VERSION ""

NS_ :

BS_:

BU_: RLPSU DPSU APSU PSB SHVU_RR vHS_B2 FCS EMCU SLB RCM CGW_CCU vDummy_HS_B ATS RLHV PFSU SGU ALBCU DSAU SWRC SHVU_FR RCS RRPSU BLTN_CAM SCM DLBCU OHCL RWPC RRHV WPC HOD ASAU

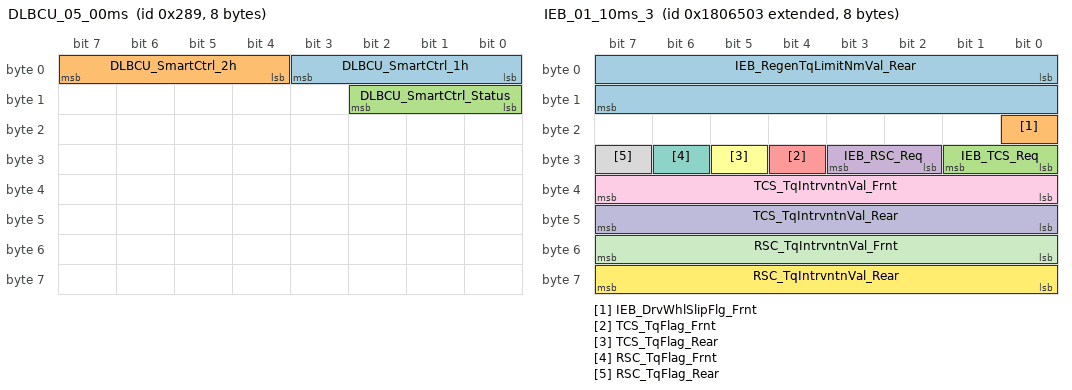
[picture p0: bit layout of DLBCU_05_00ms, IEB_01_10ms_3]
BO_ 649 DLBCU_05_00ms: 8 DLBCU
 SG_ DLBCU_SmartCtrl_1h : 0|4@1+ (1,0) [0|0] ""  CGW_CCU
 SG_ DLBCU_SmartCtrl_2h : 4|4@1+ (1,0) [0|0] ""  CGW_CCU
 SG_ DLBCU_SmartCtrl_Status : 8|3@1+ (1,0) [0|0] ""  CGW_CCU

BO_ 2172675331 IEB_01_10ms_3: 8 CGW_CCU
 SG_ IEB_RegenTqLimitNmVal_Rear : 0|16@1+ (1,0) [0|0] "Nm"  Vector__XXX
 SG_ IEB_DrvWhlSlipFlg_Frnt : 16|1@1+ (1,0) [0|0] ""  Vector__XXX
 SG_ IEB_TCS_Req : 24|2@1+ (1,0) [0|0] ""  Vector__XXX
 SG_ IEB_RSC_Req : 26|2@1+ (1,0) [0|0] ""  Vector__XXX
 SG_ TCS_TqFlag_Frnt : 28|1@1+ (1,0) [0|0] ""  Vector__XXX
 SG_ TCS_TqFlag_Rear : 29|1@1+ (1,0) [0|0] ""  Vector__XXX
 SG_ RSC_TqFlag_Frnt : 30|1@1+ (1,0) [0|0] ""  Vector__XXX
 SG_ RSC_TqFlag_Rear : 31|1@1+ (1,0) [0|0] ""  Vector__XXX
 SG_ TCS_TqIntrvntnVal_Frnt : 32|8@1+ (0.390625,0) [0|0] "%"  Vector__XXX
 SG_ TCS_TqIntrvntnVal_Rear : 40|8@1+ (0.390625,0) [0|0] "%"  Vector__XXX
 SG_ RSC_TqIntrvntnVal_Frnt : 48|8@1+ (0.390625,0) [0|0] "%"  Vector__XXX
 SG_ RSC_TqIntrvntnVal_Rear : 56|8@1+ (0.390625,0) [0|0] "%"  Vector__XXX

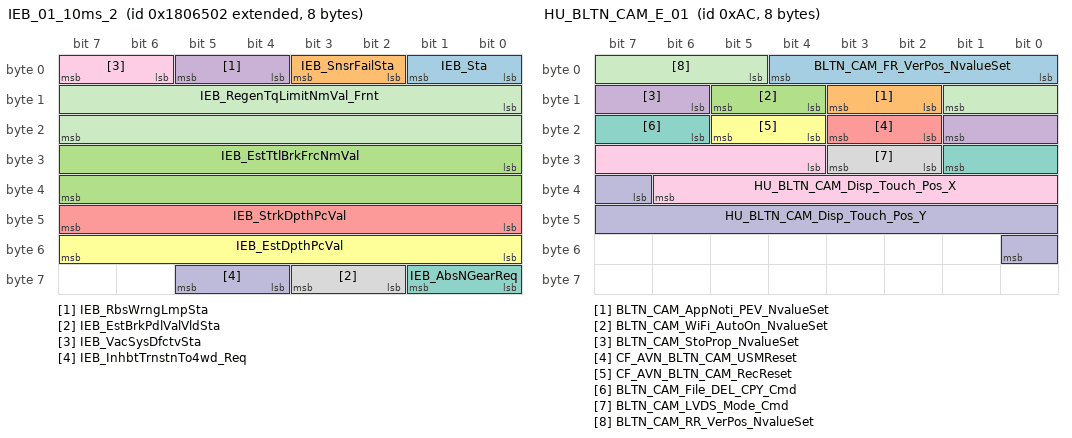
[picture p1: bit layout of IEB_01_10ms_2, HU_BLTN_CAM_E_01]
BO_ 2172675330 IEB_01_10ms_2: 8 CGW_CCU
 SG_ IEB_Sta : 0|2@1+ (1,0) [0|0] ""  Vector__XXX
 SG_ IEB_SnsrFailSta : 2|2@1+ (1,0) [0|0] ""  Vector__XXX
 SG_ IEB_EstTtlBrkFrcNmVal : 24|16@1+ (1,0) [0|0] "Nm"  Vector__XXX
 SG_ IEB_RbsWrngLmpSta : 4|2@1+ (1,0) [0|0] ""  Vector__XXX
 SG_ IEB_StrkDpthPcVal : 40|8@1+ (0.39215,0) [0|0] "%"  Vector__XXX
 SG_ IEB_EstDpthPcVal : 48|8@1+ (0.390625,0) [0|0] "%"  Vector__XXX
 SG_ IEB_AbsNGearReq : 56|2@1+ (1,0) [0|0] ""  Vector__XXX
 SG_ IEB_EstBrkPdlValVldSta : 58|2@1+ (1,0) [0|0] ""  Vector__XXX
 SG_ IEB_VacSysDfctvSta : 6|2@1+ (1,0) [0|0] ""  Vector__XXX
 SG_ IEB_InhbtTrnstnTo4wd_Req : 60|2@1+ (1,0) [0|0] ""  Vector__XXX
 SG_ IEB_RegenTqLimitNmVal_Frnt : 8|16@1+ (1,0) [0|0] "Nm"  Vector__XXX

BO_ 172 HU_BLTN_CAM_E_01: 8 CGW_CCU
 SG_ BLTN_CAM_FR_VerPos_NvalueSet : 0|5@1+ (1,0) [0|0] ""  BLTN_CAM
 SG_ BLTN_CAM_AppNoti_PEV_NvalueSet : 10|2@1+ (1,0) [0|0] ""  BLTN_CAM
 SG_ BLTN_CAM_WiFi_AutoOn_NvalueSet : 12|2@1+ (1,0) [0|0] ""  BLTN_CAM
 SG_ BLTN_CAM_StoProp_NvalueSet : 14|4@1+ (1,0) [0|0] ""  BLTN_CAM
 SG_ CF_AVN_BLTN_CAM_USMReset : 18|2@1+ (1,0) [0|0] ""  BLTN_CAM
 SG_ CF_AVN_BLTN_CAM_RecReset : 20|2@1+ (1,0) [0|0] ""  BLTN_CAM
 SG_ BLTN_CAM_File_DEL_CPY_Cmd : 22|4@1+ (1,0) [0|0] ""  BLTN_CAM
 SG_ BLTN_CAM_LVDS_Mode_Cmd : 26|2@1+ (1,0) [0|0] ""  BLTN_CAM
 SG_ HU_BLTN_CAM_Disp_Touch_Pos_X : 28|11@1+ (1,0) [0|0] ""  BLTN_CAM
 SG_ HU_BLTN_CAM_Disp_Touch_Pos_Y : 39|10@1+ (1,0) [0|0] ""  BLTN_CAM
 SG_ BLTN_CAM_RR_VerPos_NvalueSet : 5|5@1+ (1,0) [0|0] ""  BLTN_CAM

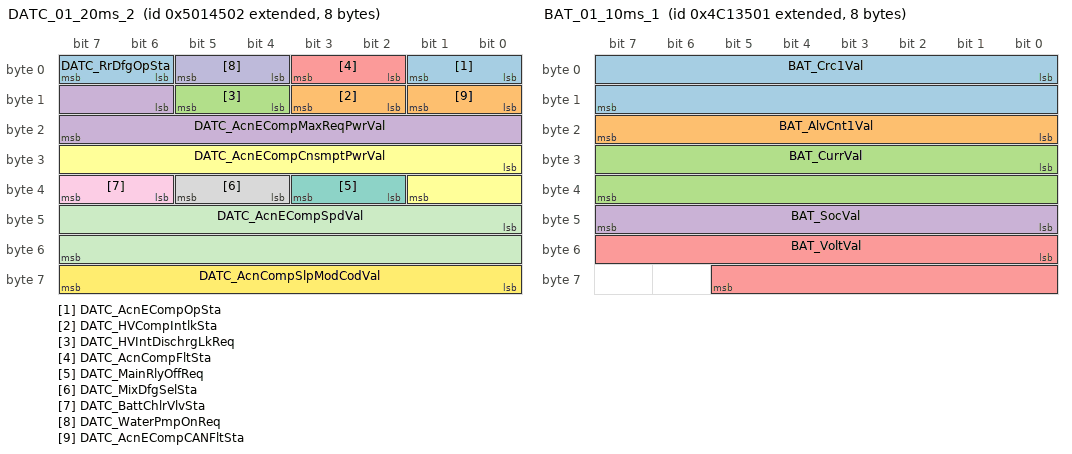
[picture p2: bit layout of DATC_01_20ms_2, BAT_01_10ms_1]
BO_ 2231452930 DATC_01_20ms_2: 8 CGW_CCU
 SG_ DATC_AcnECompOpSta : 0|2@1+ (1,0) [0|0] "flag"  Vector__XXX
 SG_ DATC_HVCompIntlkSta : 10|2@1+ (1,0) [0|0] "flag"  Vector__XXX
 SG_ DATC_HVIntDischrgLkReq : 12|2@1+ (1,0) [0|0] "flag"  Vector__XXX
 SG_ DATC_AcnECompMaxReqPwrVal : 14|10@1+ (20,0) [0|0] "W"  Vector__XXX
 SG_ DATC_AcnCompFltSta : 2|2@1+ (1,0) [0|0] "flag"  Vector__XXX
 SG_ DATC_AcnECompCnsmptPwrVal : 24|10@1+ (20,0) [0|0] "W"  Vector__XXX
 SG_ DATC_MainRlyOffReq : 34|2@1+ (1,0) [0|0] "flag"  Vector__XXX
 SG_ DATC_MixDfgSelSta : 36|2@1+ (1,0) [0|0] "flag"  Vector__XXX
 SG_ DATC_BattChlrVlvSta : 38|2@1+ (1,0) [0|0] ""  Vector__XXX
 SG_ DATC_WaterPmpOnReq : 4|2@1+ (1,0) [0|0] "flag"  Vector__XXX
 SG_ DATC_AcnECompSpdVal : 40|16@1+ (1,0) [0|0] "rpm"  Vector__XXX
 SG_ DATC_AcnCompSlpModCodVal : 56|8@1+ (1,0) [0|0] ""  Vector__XXX
 SG_ DATC_RrDfgOpSta : 6|2@1+ (1,0) [0|0] "flag"  Vector__XXX
 SG_ DATC_AcnECompCANFltSta : 8|2@1+ (1,0) [0|0] "flag"  Vector__XXX

BO_ 2227254529 BAT_01_10ms_1: 8 CGW_CCU
 SG_ BAT_Crc1Val : 0|16@1+ (1,0) [0|0] ""  Vector__XXX
 SG_ BAT_AlvCnt1Val : 16|8@1+ (1,0) [0|0] ""  Vector__XXX
 SG_ BAT_CurrVal : 24|16@1+ (0.01,-327) [0|0] "A"  Vector__XXX
 SG_ BAT_SocVal : 40|8@1+ (1,0) [0|0] "%"  BLTN_CAM
 SG_ BAT_VoltVal : 48|14@1+ (0.001,6) [0|0] "V"  Vector__XXX

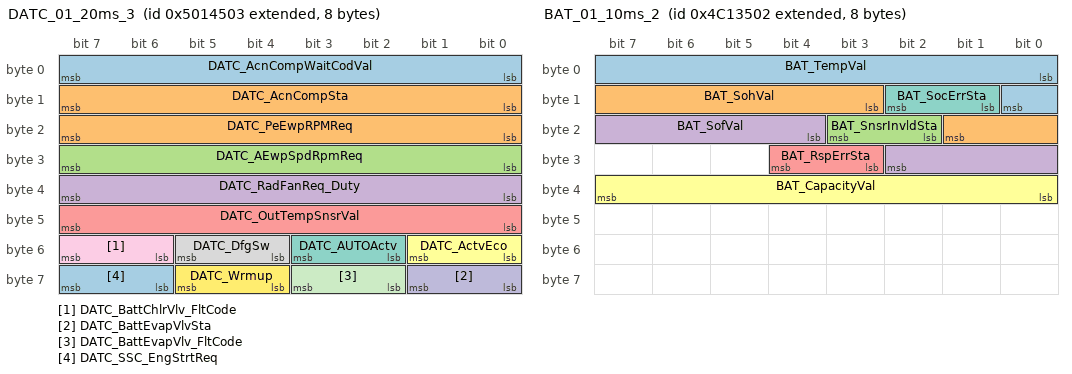
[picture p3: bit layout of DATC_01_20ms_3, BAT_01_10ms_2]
BO_ 2231452931 DATC_01_20ms_3: 8 CGW_CCU
 SG_ DATC_AcnCompWaitCodVal : 0|8@1+ (1,0) [0|0] ""  Vector__XXX
 SG_ DATC_PeEwpRPMReq : 16|8@1+ (30,0) [0|0] ""  Vector__XXX
 SG_ DATC_AEwpSpdRpmReq : 24|8@1+ (20,0) [0|0] "rpm"  Vector__XXX
 SG_ DATC_RadFanReq_Duty : 32|8@1+ (1,0) [0|0] "%"  Vector__XXX
 SG_ DATC_OutTempSnsrVal : 40|8@1+ (0.5,-40) [0|0] "¡É"  RCM
 SG_ DATC_ActvEco : 48|2@1+ (1,0) [0|0] ""  Vector__XXX
 SG_ DATC_AUTOActv : 50|2@1+ (1,0) [0|0] ""  Vector__XXX
 SG_ DATC_DfgSw : 52|2@1+ (1,0) [0|0] ""  Vector__XXX
 SG_ DATC_BattChlrVlv_FltCode : 54|2@1+ (1,0) [0|0] ""  Vector__XXX
 SG_ DATC_BattEvapVlvSta : 56|2@1+ (1,0) [0|0] ""  Vector__XXX
 SG_ DATC_BattEvapVlv_FltCode : 58|2@1+ (1,0) [0|0] ""  Vector__XXX
 SG_ DATC_Wrmup : 60|2@1+ (1,0) [0|0] ""  Vector__XXX
 SG_ DATC_SSC_EngStrtReq : 62|2@1+ (1,0) [0|0] ""  Vector__XXX
 SG_ DATC_AcnCompSta : 8|8@1+ (1,0) [0|0] ""  Vector__XXX

BO_ 2227254530 BAT_01_10ms_2: 8 CGW_CCU
 SG_ BAT_TempVal : 0|9@1+ (0.5,-40) [0|0] "¡É"  Vector__XXX
 SG_ BAT_SohVal : 11|7@1+ (1,0) [0|0] "%"  Vector__XXX
 SG_ BAT_SnsrInvldSta : 18|2@1+ (1,0) [0|0] ""  Vector__XXX
 SG_ BAT_SofVal : 20|7@1+ (0.1,0) [0|0] "V"  Vector__XXX
 SG_ BAT_RspErrSta : 27|2@1+ (1,0) [0|0] ""  Vector__XXX
 SG_ BAT_CapacityVal : 32|8@1+ (1,0) [0|0] ""  Vector__XXX
 SG_ BAT_SocErrSta : 9|2@1+ (1,0) [0|0] ""  Vector__XXX

BO_ 2231452929 DATC_01_20ms_1: 8 CGW_CCU
 SG_ DATC_Crc1Val : 0|16@1+ (1,0) [0|0] ""  Vector__XXX
 SG_ DATC_AlvCnt1Val : 16|8@1+ (1,0) [0|0] ""  Vector__XXX
 SG_ DATC_PtcRlySta : 24|3@1+ (1,0) [0|0] ""  Vector__XXX
 SG_ DATC_ManufacturerTyp : 27|3@1+ (1,0) [0|0] ""  Vector__XXX
 SG_ DATC_DatcPwmSts : 30|2@1+ (1,0) [0|0] ""  Vector__XXX
 SG_ DATC_AcnCompTyp : 32|3@1+ (1,0) [0|0] "flag"  Vector__XXX
 SG_ DATC_EewpRpmLvlReq : 35|3@1+ (1,0) [0|0] ""  Vector__XXX
 SG_ DATC_Cooldown : 38|2@1+ (1,0) [0|0] ""  Vector__XXX
 SG_ DATC_AcnReq : 40|2@1+ (1,0) [0|0] ""  Vector__XXX
 SG_ DATC_BlwSta : 42|2@1+ (1,0) [0|0] ""  Vector__XXX
 SG_ DATC_BlwMaxSta : 44|2@1+ (1,0) [0|0] ""  Vector__XXX
 SG_ DATC_EngStrtReq : 46|2@1+ (1,0) [0|0] ""  Vector__XXX
 SG_ DATC_IsgInhbtReq : 48|2@1+ (1,0) [0|0] ""  Vector__XXX
 SG_ DATC_AcnCompOnReq : 50|2@1+ (1,0) [0|0] "flag"  Vector__XXX
 SG_ DATC_SrvLmpReq : 52|2@1+ (1,0) [0|0] ""  Vector__XXX
 SG_ DATC_EcvFltSta : 54|2@1+ (1,0) [0|0] ""  Vector__XXX
 SG_ DATC_CalcAcnCompTqVal : 56|8@1+ (0.2,0) [0|0] "Nm"  Vector__XXX

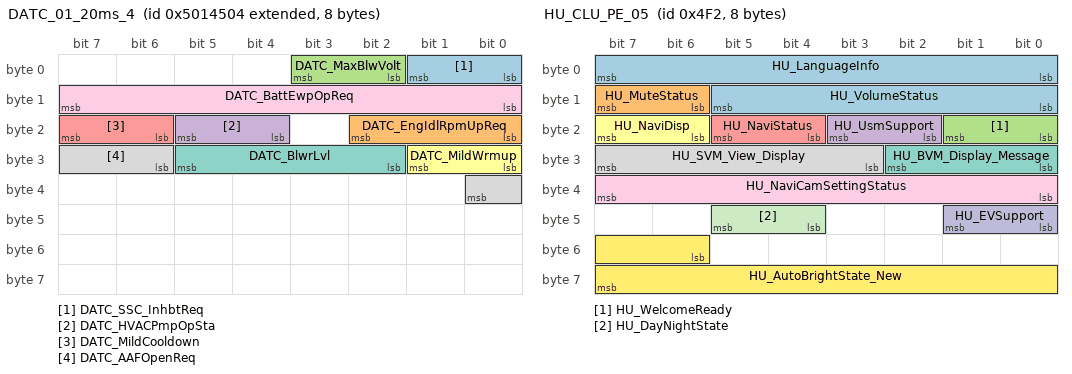
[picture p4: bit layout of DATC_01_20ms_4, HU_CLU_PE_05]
BO_ 2231452932 DATC_01_20ms_4: 8 CGW_CCU
 SG_ DATC_SSC_InhbtReq : 0|2@1+ (1,0) [0|0] ""  Vector__XXX
 SG_ DATC_EngIdlRpmUpReq : 16|3@1+ (1,0) [0|0] ""  Vector__XXX
 SG_ DATC_MaxBlwVolt : 2|2@1+ (1,0) [0|0] ""  Vector__XXX
 SG_ DATC_HVACPmpOpSta : 20|2@1+ (1,0) [0|0] ""  Vector__XXX
 SG_ DATC_MildCooldown : 22|2@1+ (1,0) [0|0] ""  Vector__XXX
 SG_ DATC_MildWrmup : 24|2@1+ (1,0) [0|0] ""  Vector__XXX
 SG_ DATC_BlwrLvl : 26|4@1+ (1,0) [0|0] ""  Vector__XXX
 SG_ DATC_AAFOpenReq : 30|3@1+ (1,0) [0|0] ""  Vector__XXX
 SG_ DATC_BattEwpOpReq : 8|8@1+ (30,0) [0|0] "rpm"  Vector__XXX

BO_ 1266 HU_CLU_PE_05: 8 CGW_CCU
 SG_ HU_LanguageInfo : 0|8@1+ (1,0) [0|0] ""  ATS,BLTN_CAM
 SG_ HU_MuteStatus : 14|2@1+ (1,0) [0|0] ""  Vector__XXX
 SG_ HU_WelcomeReady : 16|2@1+ (1,0) [0|0] ""  Vector__XXX
 SG_ HU_UsmSupport : 18|2@1+ (1,0) [0|0] ""  Vector__XXX
 SG_ HU_NaviStatus : 20|2@1+ (1,0) [0|0] ""  Vector__XXX
 SG_ HU_NaviDisp : 22|2@1+ (1,0) [0|0] ""  Vector__XXX
 SG_ HU_BVM_Display_Message : 24|3@1+ (1,0) [0|0] ""  Vector__XXX
 SG_ HU_SVM_View_Display : 27|5@1+ (1,0) [0|0] ""  Vector__XXX
 SG_ HU_NaviCamSettingStatus : 32|8@1+ (1,0) [0|0] ""  Vector__XXX
 SG_ HU_EVSupport : 40|2@1+ (1,0) [0|0] ""  Vector__XXX
 SG_ HU_DayNightState : 44|2@1+ (1,0) [0|0] ""  Vector__XXX
 SG_ HU_AutoBrightState_New : 54|10@1+ (1,0) [0|0] ""  Vector__XXX
 SG_ HU_VolumeStatus : 8|6@1+ (1,0) [0|0] ""  Vector__XXX

BO_ 191 RL_SHVU_03_200ms: 8 SHVU_RR
 SG_ RL_SHVU_DTCdisplay : 0|8@1+ (1,0) [0|0] ""  ATS
 SG_ RL_SHVU_DiagMode : 8|2@1+ (1,0) [0|0] ""  ATS

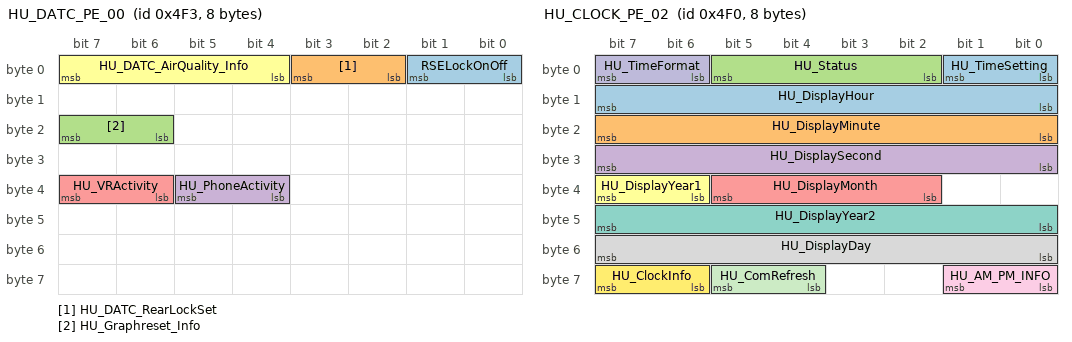
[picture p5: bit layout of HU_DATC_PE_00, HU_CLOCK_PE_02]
BO_ 1267 HU_DATC_PE_00: 8 CGW_CCU
 SG_ RSELockOnOff : 0|2@1+ (1,0) [0|0] ""  APSU,ATS
 SG_ HU_DATC_RearLockSet : 2|2@1+ (1,0) [0|0] ""  Vector__XXX
 SG_ HU_Graphreset_Info : 22|2@1+ (1,0) [0|0] ""  Vector__XXX
 SG_ HU_PhoneActivity : 36|2@1+ (1,0) [0|0] ""  Vector__XXX
 SG_ HU_VRActivity : 38|2@1+ (1,0) [0|0] ""  Vector__XXX
 SG_ HU_DATC_AirQuality_Info : 4|4@1+ (1,0) [0|0] ""  Vector__XXX

BO_ 1264 HU_CLOCK_PE_02: 8 CGW_CCU
 SG_ HU_TimeSetting : 0|2@1+ (1,0) [0|0] ""  ATS,BLTN_CAM
 SG_ HU_DisplayMinute : 16|8@1+ (1,0) [0|0] ""  ATS,BLTN_CAM
 SG_ HU_Status : 2|4@1+ (1,0) [0|0] ""  ATS,BLTN_CAM
 SG_ HU_DisplaySecond : 24|8@1+ (1,0) [0|0] ""  ATS,BLTN_CAM
 SG_ HU_DisplayMonth : 34|4@1+ (1,0) [0|0] ""  ATS,BLTN_CAM
 SG_ HU_DisplayYear1 : 38|2@1+ (1,0) [0|0] ""  ATS,BLTN_CAM
 SG_ HU_DisplayYear2 : 40|8@1+ (1,0) [0|0] ""  ATS,BLTN_CAM
 SG_ HU_DisplayDay : 48|8@1+ (1,0) [0|0] ""  ATS,BLTN_CAM
 SG_ HU_AM_PM_INFO : 56|2@1+ (1,0) [0|0] ""  ATS,BLTN_CAM
 SG_ HU_TimeFormat : 6|2@1+ (1,0) [0|0] ""  ATS,BLTN_CAM
 SG_ HU_ComRefresh : 60|2@1+ (1,0) [0|0] ""  ATS,BLTN_CAM
 SG_ HU_ClockInfo : 62|2@1+ (1,0) [0|0] ""  ATS,BLTN_CAM
 SG_ HU_DisplayHour : 8|8@1+ (1,0) [0|0] ""  ATS,BLTN_CAM

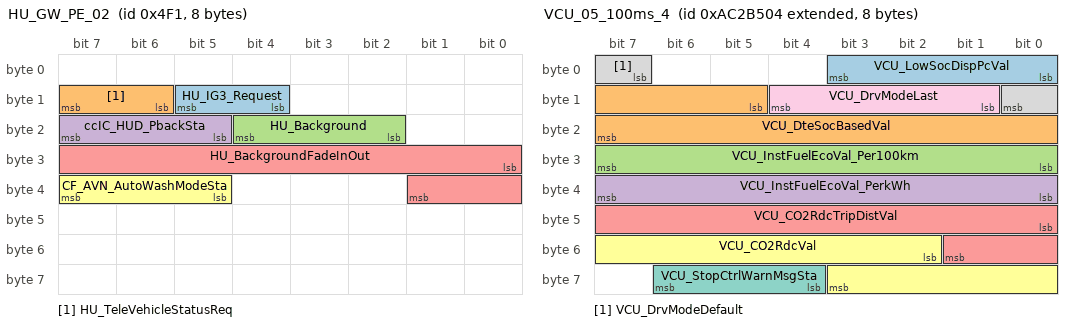
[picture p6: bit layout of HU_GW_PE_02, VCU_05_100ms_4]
BO_ 1265 HU_GW_PE_02: 8 CGW_CCU
 SG_ HU_IG3_Request : 12|2@1+ (1,0) [0|0] ""  Vector__XXX
 SG_ HU_TeleVehicleStatusReq : 14|2@1+ (1,0) [0|3] ""  Vector__XXX
 SG_ HU_Background : 18|3@1+ (1,0) [0|0] ""  ATS,BLTN_CAM
 SG_ ccIC_HUD_PbackSta : 21|3@1+ (1,0) [0|0] ""  DPSU
 SG_ HU_BackgroundFadeInOut : 24|10@1+ (0.1,0) [0|0] "%"  ATS,BLTN_CAM
 SG_ CF_AVN_AutoWashModeSta : 37|3@1+ (1,0) [0|0] ""  RCM

BO_ 2328016132 VCU_05_100ms_4: 8 CGW_CCU
 SG_ VCU_LowSocDispPcVal : 0|4@1+ (1,0) [0|0] ""  Vector__XXX
 SG_ VCU_DteSocBasedVal : 13|11@1+ (1,0) [0|0] "km"  Vector__XXX
 SG_ VCU_InstFuelEcoVal_Per100km : 24|8@1+ (0.5,0) [0|126.5] "kWh/100km"  Vector__XXX
 SG_ VCU_InstFuelEcoVal_PerkWh : 32|8@1+ (0.1,0) [0|25.5] "km/kWh"  Vector__XXX
 SG_ VCU_CO2RdcTripDistVal : 40|10@1+ (1,0) [0|1023] "km"  Vector__XXX
 SG_ VCU_CO2RdcVal : 50|10@1+ (100,0) [0|102300] "g"  Vector__XXX
 SG_ VCU_StopCtrlWarnMsgSta : 60|3@1+ (1,0) [0|0] ""  Vector__XXX
 SG_ VCU_DrvModeDefault : 7|2@1+ (1,0) [0|0] ""  Vector__XXX
 SG_ VCU_DrvModeLast : 9|4@1+ (1,0) [0|0] ""  Vector__XXX

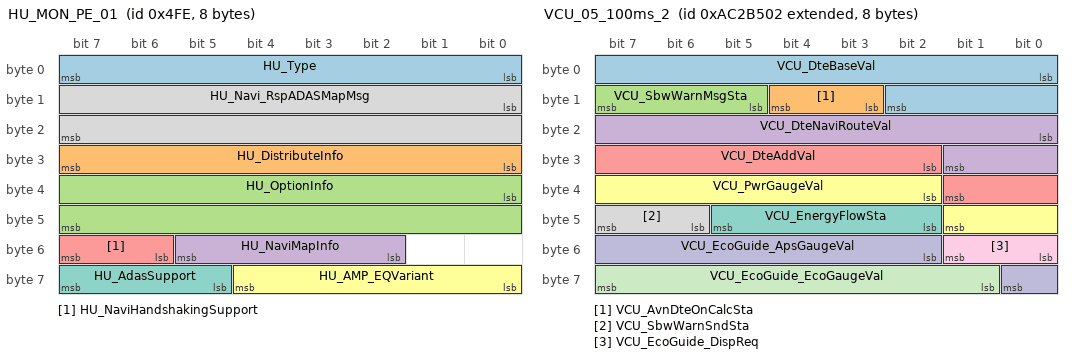
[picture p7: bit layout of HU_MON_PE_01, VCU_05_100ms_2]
BO_ 1278 HU_MON_PE_01: 8 CGW_CCU
 SG_ HU_Type : 0|8@1+ (1,0) [0|0] ""  BLTN_CAM
 SG_ HU_DistributeInfo : 24|8@1+ (1,0) [0|0] ""  BLTN_CAM
 SG_ HU_OptionInfo : 32|16@1+ (1,0) [0|0] ""  BLTN_CAM
 SG_ HU_NaviMapInfo : 50|4@1+ (1,0) [0|0] ""  Vector__XXX
 SG_ HU_NaviHandshakingSupport : 54|2@1+ (1,0) [0|0] ""  Vector__XXX
 SG_ HU_AMP_EQVariant : 56|5@1+ (1,0) [0|0] ""  Vector__XXX
 SG_ HU_AdasSupport : 61|3@1+ (1,0) [0|0] ""  Vector__XXX
 SG_ HU_Navi_RspADASMapMsg : 8|16@1+ (1,0) [0|0] ""  Vector__XXX

BO_ 1279 HU_USM_E_10: 8 CGW_CCU
 SG_ USM_SmartRegen_Map_Set : 11|2@1+ (1,0) [0|0] ""  Vector__XXX
 SG_ USM_SmartRegen_Sens_Set : 13|3@1+ (1,0) [0|0] ""  Vector__XXX
 SG_ AVN_SeatPosMemory_Btn : 16|3@1+ (1,0) [0|0] ""  Vector__XXX
 SG_ AVN_SeatPosPlyBck_Btn : 19|3@1+ (1,0) [0|0] ""  DPSU
 SG_ USM_RhstaLvlEnaSetReq : 22|2@1+ (1,0) [0|0] ""  Vector__XXX
 SG_ USM_CMSDayBrgtnsLvlLHSetReq : 24|4@1+ (1,0) [0|0] ""  Vector__XXX
 SG_ USM_CMSNgtBrgtnsLvlLHSetReq : 28|4@1+ (1,0) [0|0] ""  Vector__XXX
 SG_ USM_CMSDayBrgtnsLvlRHSetReq : 32|4@1+ (1,0) [0|0] ""  Vector__XXX
 SG_ USM_CMSNgtBrgtnsLvlRHSetReq : 36|4@1+ (1,0) [0|0] ""  Vector__XXX
 SG_ USM_CMSBrgtnsReset : 40|2@1+ (1,0) [0|0] ""  Vector__XXX
 SG_ USM_TurnDistLnDispSetReq : 42|2@1+ (1,0) [0|0] ""  Vector__XXX
 SG_ PCA_FrSd_NValueSet : 44|2@1+ (1,0) [0|0] ""  Vector__XXX
 SG_ CF_AVN_1stRrStRmndNValueSet : 46|2@1+ (1,0) [0|0] ""  Vector__XXX
 SG_ AVN_Usm_CluThemeSta_New : 48|4@1+ (1,0) [0|0] ""  Vector__XXX
 SG_ C_AllDrOpnNValueSet : 52|3@1+ (1,0) [0|0] ""  Vector__XXX
 SG_ USM_RpmECOSet : 55|2@1+ (1,0) [0|0] ""  Vector__XXX
 SG_ VESS_ChgGuideMdLvl : 57|3@1+ (1,0) [0|0] ""  Vector__XXX
 SG_ Usm_RpmSPORTSet : 60|2@1+ (1,0) [0|0] ""  Vector__XXX
 SG_ Usm_RpmSPORTPLUSSet : 62|2@1+ (1,0) [0|0] ""  Vector__XXX

BO_ 2328016129 VCU_05_100ms_1: 8 CGW_CCU
 SG_ VCU_Crc5Val : 0|16@1+ (1,0) [0|0] ""  Vector__XXX
 SG_ VCU_AlvCnt5Val : 16|8@1+ (1,0) [0|0] ""  Vector__XXX
 SG_ VCU_EvDrvRdyCluDispSta : 24|2@1+ (1,0) [0|3] ""  SWRC
 SG_ VCU_PwrDnModeSta : 26|2@1+ (1,0) [0|3] ""  Vector__XXX
 SG_ VCU_CluWarnMsgSta : 28|4@1+ (1,0) [0|15] ""  Vector__XXX
 SG_ VCU_DteOffDispSta : 32|2@1+ (1,0) [0|0] "flag"  Vector__XXX
 SG_ VCU_LowSocAlertSta : 34|3@1+ (1,0) [0|7] ""  Vector__XXX
 SG_ VCU_VcrmReq : 38|2@1+ (1,0) [0|3] ""  Vector__XXX
 SG_ VCU_PdlWarnMsgSta : 40|2@1+ (1,0) [0|3] ""  Vector__XXX
 SG_ VCU_AwdDiagDispSta : 42|2@1+ (1,0) [0|0] ""  Vector__XXX
 SG_ VCU_AwdLockDispSta : 44|2@1+ (1,0) [0|0] ""  Vector__XXX
 SG_ VCU_VirtualApsActSta : 46|2@1+ (1,0) [0|3] ""  Vector__XXX
 SG_ VCU_VirtualApsVal : 48|8@1+ (0.3906,0) [0|99.61] "%"  Vector__XXX
 SG_ VCU_ServiceLampReq : 56|2@1+ (1,0) [0|3] ""  Vector__XXX
 SG_ VCU_ServiceModeSta : 58|2@1+ (1,0) [0|3] ""  Vector__XXX
 SG_ VCU_NPosWshModSta : 60|2@1+ (1,0) [0|0] "flag"  Vector__XXX
 SG_ VCU_PowerTrainType : 62|2@1+ (1,0) [0|3] ""  Vector__XXX

BO_ 2328016130 VCU_05_100ms_2: 8 CGW_CCU
 SG_ VCU_DteBaseVal : 0|11@1+ (1,0) [0|2047] "km"  Vector__XXX
 SG_ VCU_AvnDteOnCalcSta : 11|2@1+ (1,0) [0|3] ""  Vector__XXX
 SG_ VCU_SbwWarnMsgSta : 13|3@1+ (1,0) [0|0] "flag"  Vector__XXX
 SG_ VCU_DteNaviRouteVal : 16|10@1+ (2,0) [0|1026] "km"  Vector__XXX
 SG_ VCU_DteAddVal : 26|8@1+ (1,0) [0|255] "km"  Vector__XXX
 SG_ VCU_PwrGaugeVal : 34|8@1- (1,0) [-100|100] "%"  Vector__XXX
 SG_ VCU_EnergyFlowSta : 42|4@1+ (1,0) [0|15] ""  Vector__XXX
 SG_ VCU_SbwWarnSndSta : 46|2@1+ (1,0) [0|0] "flag"  Vector__XXX
 SG_ VCU_EcoGuide_DispReq : 48|2@1+ (1,0) [0|3] ""  Vector__XXX
 SG_ VCU_EcoGuide_ApsGaugeVal : 50|7@1+ (1,0) [0|100] "%"  Vector__XXX
 SG_ VCU_EcoGuide_EcoGaugeVal : 57|7@1+ (1,0) [0|100] "%"  Vector__XXX

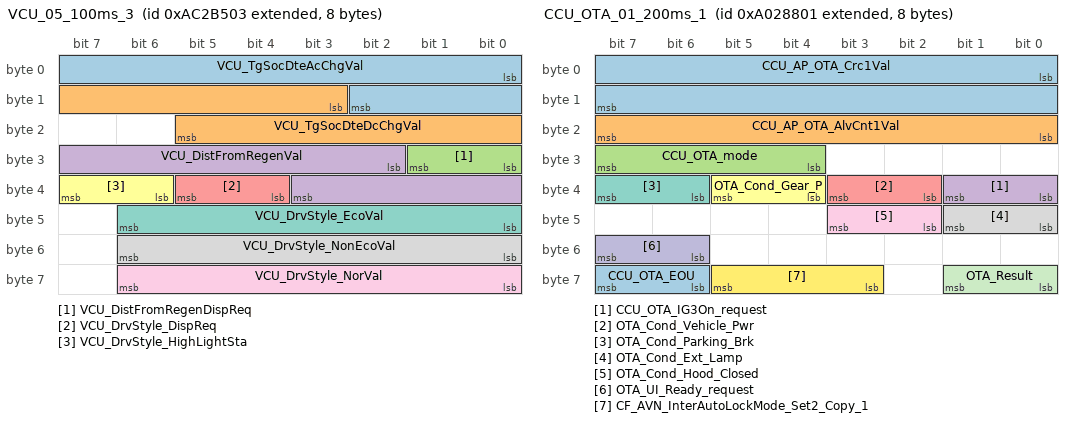
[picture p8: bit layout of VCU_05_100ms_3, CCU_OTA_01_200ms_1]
BO_ 2328016131 VCU_05_100ms_3: 8 CGW_CCU
 SG_ VCU_TgSocDteAcChgVal : 0|11@1+ (1,0) [0|2047] "km"  Vector__XXX
 SG_ VCU_TgSocDteDcChgVal : 11|11@1+ (1,0) [0|2047] "km"  Vector__XXX
 SG_ VCU_DistFromRegenDispReq : 24|2@1+ (1,0) [0|3] ""  Vector__XXX
 SG_ VCU_DistFromRegenVal : 26|10@1+ (10,0) [0|10230] "m"  Vector__XXX
 SG_ VCU_DrvStyle_DispReq : 36|2@1+ (1,0) [0|3] ""  Vector__XXX
 SG_ VCU_DrvStyle_HighLightSta : 38|2@1+ (1,0) [0|3] ""  Vector__XXX
 SG_ VCU_DrvStyle_EcoVal : 40|7@1+ (1,0) [0|100] "%"  Vector__XXX
 SG_ VCU_DrvStyle_NonEcoVal : 48|7@1+ (1,0) [0|100] "%"  Vector__XXX
 SG_ VCU_DrvStyle_NorVal : 56|7@1+ (1,0) [0|100] "%"  Vector__XXX

BO_ 2315421697 CCU_OTA_01_200ms_1: 8 CGW_CCU
 SG_ CCU_AP_OTA_Crc1Val : 0|16@1+ (1,0) [0|0] ""  vDummy_HS_B
 SG_ CCU_AP_OTA_AlvCnt1Val : 16|8@1+ (1,0) [0|0] ""  vDummy_HS_B
 SG_ CCU_OTA_mode : 28|4@1+ (1,0) [0|0] ""  Vector__XXX
 SG_ CCU_OTA_IG3On_request : 32|2@1+ (1,0) [0|0] ""  Vector__XXX
 SG_ OTA_Cond_Vehicle_Pwr : 34|2@1+ (1,0) [0|0] "flag"  Vector__XXX
 SG_ OTA_Cond_Gear_P : 36|2@1+ (1,0) [0|0] "flag"  Vector__XXX
 SG_ OTA_Cond_Parking_Brk : 38|2@1+ (1,0) [0|0] "flag"  Vector__XXX
 SG_ OTA_Cond_Ext_Lamp : 40|2@1+ (1,0) [0|0] "flag"  Vector__XXX
 SG_ OTA_Cond_Hood_Closed : 42|2@1+ (1,0) [0|0] "flag"  Vector__XXX
 SG_ OTA_UI_Ready_request : 54|2@1+ (1,0) [0|0] ""  Vector__XXX
 SG_ OTA_Result : 56|2@1+ (1,0) [0|0] "flag"  Vector__XXX
 SG_ CF_AVN_InterAutoLockMode_Set2_Copy_1 : 59|3@1+ (1,0) [0|0] ""  Vector__XXX
 SG_ CCU_OTA_EOU : 62|2@1+ (1,0) [0|0] ""  Vector__XXX

BO_ 2470763009 CLU_09_00ms_1: 8 CGW_CCU
 SG_ CLU_Crc9Val : 0|16@1+ (1,0) [0|0] ""  Vector__XXX
 SG_ CLU_AlvCnt9Val : 16|8@1+ (1,0) [0|0] ""  Vector__XXX
 SG_ USM_MdLmpClrSetReq : 24|4@1+ (1,0) [0|0] ""  Vector__XXX
 SG_ USM_RrWiperRevSetReq : 28|2@1+ (1,0) [0|0] ""  Vector__XXX
 SG_ USM_RrStRemindSetReq : 30|2@1+ (1,0) [0|0] ""  Vector__XXX
 SG_ USM_RrWpcSetReq : 32|2@1+ (1,0) [0|0] ""  Vector__XXX
 SG_ USM_WpcSetReq : 34|2@1+ (1,0) [0|0] ""  WPC
 SG_ USM_SeqLmpSetReq : 36|2@1+ (1,0) [0|0] ""  Vector__XXX
 SG_ USM_UnlckWlcmSetReq : 38|2@1+ (1,0) [0|0] ""  Vector__XXX
 SG_ USM_SmrtWlcmSetReq : 40|2@1+ (1,0) [0|0] ""  Vector__XXX
 SG_ USM_UipSetReq : 42|2@1+ (1,0) [0|0] ""  Vector__XXX
 SG_ USM_DigitalKeyEnblSetReq : 44|2@1+ (1,0) [0|0] ""  Vector__XXX
 SG_ USM_OwnerPhnRegSetReq : 46|2@1+ (1,0) [0|0] ""  Vector__XXX
 SG_ USM_NFCCard1RegSetReq : 48|2@1+ (1,0) [0|0] ""  Vector__XXX
 SG_ USM_NFCCard2RegSetReq : 50|2@1+ (1,0) [0|0] ""  Vector__XXX
 SG_ USM_ProcStpReq : 52|1@1+ (1,0) [0|0] ""  Vector__XXX
 SG_ USM_PwrAutoOffTimeSetReq : 54|3@1+ (1,0) [0|0] ""  Vector__XXX
 SG_ USM_RrStRemindSetReq_RestMode : 57|3@1+ (1,0) [0|0] ""  Vector__XXX
 SG_ USM_1stRrStRemindSetReq : 60|2@1+ (1,0) [0|0] ""  Vector__XXX

BO_ 200 HU_USM_E_12: 8 CGW_CCU
 SG_ CF_AVN_ADrLNValueSet_2 : 0|3@1+ (1,0) [0|0] ""  Vector__XXX
 SG_ CF_AVN_FCA_JC_OnOffEquipNvalueSet : 12|2@1+ (1,0) [0|0] ""  Vector__XXX
 SG_ CF_AVN_FCA_FrSdOnOffEquipNvalueSet : 14|2@1+ (1,0) [0|0] ""  Vector__XXX
 SG_ CF_AVN_LKA_OnOffEquip2NvalueSet : 16|2@1+ (1,0) [0|0] ""  Vector__XXX
 SG_ CF_AVN_BCA_OnOffEquip2NvalueSet : 18|2@1+ (1,0) [0|0] ""  Vector__XXX
 SG_ CF_AVN_BVM_OnOffEquipNvalueSet : 20|2@1+ (1,0) [0|0] ""  Vector__XXX
 SG_ CF_AVN_SEA_OnOffEquip3NvalueSet : 22|2@1+ (1,0) [0|0] ""  Vector__XXX
 SG_ CF_AVN_BodySpprtSet_AST : 24|2@1+ (1,0) [0|0] ""  ALBCU
 SG_ CF_AVN_SEW_OnOffEquip3NvalueSet : 26|2@1+ (1,0) [0|0] ""  Vector__XXX
 SG_ CF_AVN_HudImsAutoSave : 28|2@1+ (1,0) [0|0] ""  Vector__XXX
 SG_ USM_PwrDrBuzzerNValueSet : 3|2@1+ (1,0) [0|0] ""  Vector__XXX
 SG_ CF_AVN_DWLNValueSet : 30|3@1+ (1,0) [0|0] ""  Vector__XXX
 SG_ CF_AVN_AirSptTimeNValueSet_AST : 33|3@1+ (1,0) [0|0] ""  ALBCU
 SG_ CF_AVN_AirSptStrNValue_AST : 36|2@1+ (1,0) [0|0] ""  ALBCU
 SG_ CF_AVN_SeatDrvModNvalueSet_AST : 38|2@1+ (1,0) [0|0] ""  ALBCU
 SG_ CF_AVN_TPMS_TireReplaceNValueSet : 40|3@1+ (1,0) [0|0] ""  Vector__XXX
 SG_ CF_AVN_TowModeSet : 43|3@1+ (1,0) [0|0] ""  Vector__XXX
 SG_ USM_PwrDrCloseByBraekNValueSet : 46|2@1+ (1,0) [0|0] ""  Vector__XXX
 SG_ CF_AVN_ISLANAOffstNvalueSet : 50|3@1+ (1,0) [0|0] ""  Vector__XXX
 SG_ USM_DrvGhostDoorReq : 56|2@1+ (1,0) [0|0] ""  Vector__XXX
 SG_ USM_AstGhostDoorReq : 58|2@1+ (1,0) [0|0] ""  Vector__XXX
 SG_ USM_RLGhostDoorReq : 60|2@1+ (1,0) [0|0] ""  Vector__XXX
 SG_ USM_RRGhostDoorReq : 62|2@1+ (1,0) [0|0] ""  Vector__XXX
 SG_ CF_AVN_FCA_FrOnOffEquipNvalueSet : 7|2@1+ (1,0) [0|0] ""  Vector__XXX
 SG_ CF_AVN_FCA_WarnTimeNvalueSet : 9|3@1+ (1,0) [0|0] ""  Vector__XXX

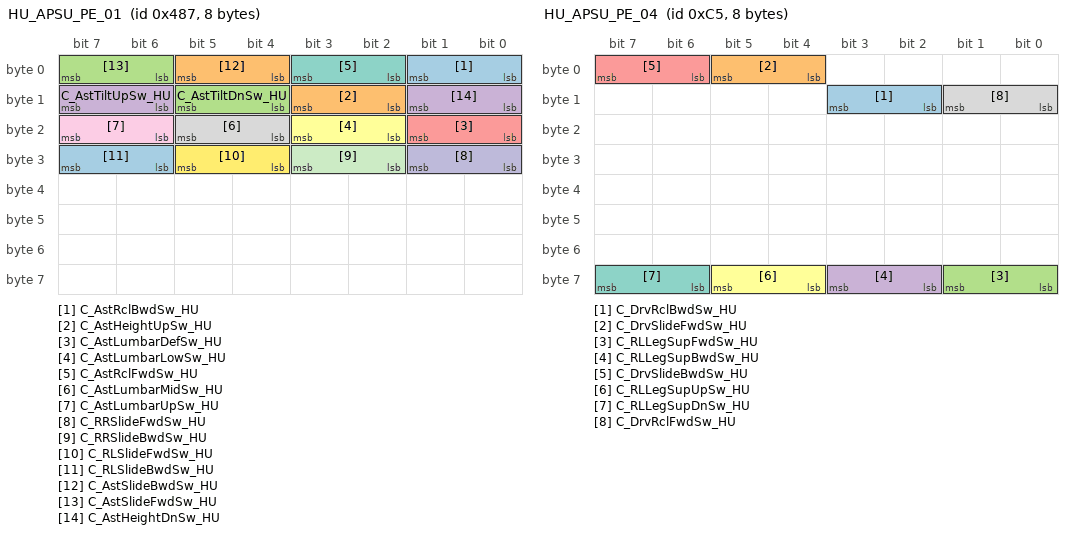
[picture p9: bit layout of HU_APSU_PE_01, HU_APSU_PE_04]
BO_ 1159 HU_APSU_PE_01: 8 CGW_CCU
 SG_ C_AstRclBwdSw_HU : 0|2@1+ (1,0) [0|0] ""  APSU
 SG_ C_AstHeightUpSw_HU : 10|2@1+ (1,0) [0|0] ""  APSU
 SG_ C_AstTiltDnSw_HU : 12|2@1+ (1,0) [0|0] ""  APSU
 SG_ C_AstTiltUpSw_HU : 14|2@1+ (1,0) [0|0] ""  APSU
 SG_ C_AstLumbarDefSw_HU : 16|2@1+ (1,0) [0|0] ""  ASAU,ALBCU
 SG_ C_AstLumbarLowSw_HU : 18|2@1+ (1,0) [0|0] ""  ASAU,ALBCU
 SG_ C_AstRclFwdSw_HU : 2|2@1+ (1,0) [0|0] ""  APSU
 SG_ C_AstLumbarMidSw_HU : 20|2@1+ (1,0) [0|0] ""  ASAU,ALBCU
 SG_ C_AstLumbarUpSw_HU : 22|2@1+ (1,0) [0|0] ""  ASAU,ALBCU
 SG_ C_RRSlideFwdSw_HU : 24|2@1+ (1,0) [0|0] ""  APSU,RRPSU,RLPSU
 SG_ C_RRSlideBwdSw_HU : 26|2@1+ (1,0) [0|0] ""  APSU,RRPSU,RLPSU
 SG_ C_RLSlideFwdSw_HU : 28|2@1+ (1,0) [0|0] ""  APSU,RRPSU,RLPSU
 SG_ C_RLSlideBwdSw_HU : 30|2@1+ (1,0) [0|0] ""  APSU,RRPSU,RLPSU
 SG_ C_AstSlideBwdSw_HU : 4|2@1+ (1,0) [0|0] ""  APSU
 SG_ C_AstSlideFwdSw_HU : 6|2@1+ (1,0) [0|0] ""  APSU
 SG_ C_AstHeightDnSw_HU : 8|2@1+ (1,0) [0|0] ""  APSU

BO_ 197 HU_APSU_PE_04: 8 CGW_CCU
 SG_ C_DrvRclBwdSw_HU : 10|2@1+ (1,0) [0|0] ""  DPSU
 SG_ C_DrvSlideFwdSw_HU : 4|2@1+ (1,0) [0|0] ""  DPSU
 SG_ C_RLLegSupFwdSw_HU : 56|2@1+ (1,0) [0|0] ""  APSU,RRPSU,RLPSU
 SG_ C_RLLegSupBwdSw_HU : 58|2@1+ (1,0) [0|0] ""  APSU,RRPSU,RLPSU
 SG_ C_DrvSlideBwdSw_HU : 6|2@1+ (1,0) [0|0] ""  DPSU
 SG_ C_RLLegSupUpSw_HU : 60|2@1+ (1,0) [0|0] ""  APSU,RRPSU,RLPSU
 SG_ C_RLLegSupDnSw_HU : 62|2@1+ (1,0) [0|0] ""  APSU,RRPSU,RLPSU
 SG_ C_DrvRclFwdSw_HU : 8|2@1+ (1,0) [0|0] ""  DPSU

BO_TX_BU_ 191 : SHVU_RR,SHVU_FR,RLHV;
CM_ BO_ 2227254529 "[P] Periodic";
CM_ SG_ 2227254529 BAT_Crc1Val "BAT_CyclicRedundancyCheck1Value";
CM_ SG_ 2227254529 BAT_AlvCnt1Val "BAT_AliveCounter1Value";
CM_ SG_ 2227254529 BAT_CurrVal "BAT_CurrentValue";
CM_ SG_ 2227254529 BAT_SocVal "BAT_StateOfChargeValue";
CM_ SG_ 2227254529 BAT_VoltVal "BAT_VoltageValue";
CM_ BO_ 2227254530 "[P] Periodic";
CM_ SG_ 2227254530 BAT_TempVal "BAT_TemperatureValue";
CM_ SG_ 2227254530 BAT_SohVal "BAT_StateOfHealthValue";
CM_ SG_ 2227254530 BAT_SnsrInvldSta "BAT_SensorInvalidStatus";
CM_ SG_ 2227254530 BAT_SofVal "BAT_StateOfFunctionValue";
CM_ SG_ 2227254530 BAT_RspErrSta "BAT_ResponseErrorStatus";
CM_ SG_ 2227254530 BAT_CapacityVal "12V Battery Capacity Value";
CM_ SG_ 2227254530 BAT_SocErrSta "BAT_SoCErrorStatus";
CM_ BO_ 2315421697 "[PE] Periodic and On Event";
CM_ SG_ 2315421697 CCU_OTA_mode "OTA_mode";
CM_ SG_ 2315421697 CCU_OTA_IG3On_request "IG3 Rly ON request";
CM_ SG_ 2315421697 OTA_UI_Ready_request "OTA UI Ready";
CM_ SG_ 2315421697 OTA_Result "¾÷µ¥ÀÌÆ® °á°ú";
CM_ SG_ 2315421697 CF_AVN_InterAutoLockMode_Set2_Copy_1 "USM Request for Charing Connector Locking Mode (Auto/Lock/Unlock)";
CM_ BO_ 2470763009 "[EC] On Event and On Change";
CM_ SG_ 2470763009 CLU_Crc9Val "CLU_CyclicRedundancyCheck9Value";
CM_ SG_ 2470763009 CLU_AlvCnt9Val "CLU_AliveCounter9Value";
CM_ SG_ 2470763009 USM_MdLmpClrSetReq "USM_MoodLampColorSetRequest";
CM_ SG_ 2470763009 USM_RrWiperRevSetReq "USM_RearWiperReverseSetRequest";
CM_ SG_ 2470763009 USM_RrStRemindSetReq "USM_RrseatReminderSetRequest(2nd :General: CLU20/CF_Clu_RrSeatRemindNValueSet)";
CM_ SG_ 2470763009 USM_RrWpcSetReq "USM_RearWpcSetRequest";
CM_ SG_ 2470763009 USM_WpcSetReq "USM_WpcSetRequest";
CM_ SG_ 2470763009 USM_SeqLmpSetReq "USM_SequencialLampSetRequest";
CM_ SG_ 2470763009 USM_UnlckWlcmSetReq "USM_UnlockWelcomeSetRequest";
CM_ SG_ 2470763009 USM_SmrtWlcmSetReq "USM_SmartWelcomeSetRequest";
CM_ SG_ 2470763009 USM_UipSetReq "2nd General: CF_Clu_UIPNValueSet";
CM_ SG_ 2470763009 USM_DigitalKeyEnblSetReq "Request to set the Digital Key ON or OFF(2nd General DB: CF_Clu_DigitalKeyNValueSet)";
CM_ SG_ 2470763009 USM_OwnerPhnRegSetReq "2nd general DB: CF_Clu_OwnerPhoneNValueSet";
CM_ SG_ 2470763009 USM_NFCCard1RegSetReq "2nd General DB:CF_Clu_NFCCard1NValueSet";
CM_ SG_ 2470763009 USM_NFCCard2RegSetReq "2nd General DB:CF_Clu_NFCCard2NValueSet";
CM_ SG_ 2470763009 USM_ProcStpReq "2nd General DB:CF_Clu_ProcessStopReq";
CM_ SG_ 2470763009 USM_PwrAutoOffTimeSetReq "USM_PowerAutoofftimeSetRequest";
CM_ SG_ 2470763009 USM_RrStRemindSetReq_RestMode "Request to set  Restmod of Rear Seat remind";
CM_ SG_ 2470763009 USM_1stRrStRemindSetReq "USM_RrseatReminderSetRequest(2nd :General: CLU21/CF_Clu_1stRrSeatRemindNValueSet)";
CM_ BO_ 2231452929 "[P] Periodic";
CM_ SG_ 2231452929 DATC_Crc1Val "DATC_CyclicRedundancyCheck1Value";
CM_ SG_ 2231452929 DATC_AlvCnt1Val "DATC_AliveCounter1Value";
CM_ SG_ 2231452929 DATC_PtcRlySta "DATC_PtcRelayStatus";
CM_ SG_ 2231452929 DATC_ManufacturerTyp "DATC_ManufacturerType";
CM_ SG_ 2231452929 DATC_DatcPwmSts "Status of E-comp";
CM_ SG_ 2231452929 DATC_AcnCompTyp "DATC_AirconCompressorType";
CM_ SG_ 2231452929 DATC_EewpRpmLvlReq "DATC_EewpRpmlevelReq";
CM_ SG_ 2231452929 DATC_Cooldown "Complete of cooldown";
CM_ SG_ 2231452929 DATC_AcnReq "DATC_AirconRequest";
CM_ SG_ 2231452929 DATC_BlwSta "DATC_BlowerStatus";
CM_ SG_ 2231452929 DATC_BlwMaxSta "DATC_BlowerMaxStatus";
CM_ SG_ 2231452929 DATC_EngStrtReq "DATC_EngineStartRequest";
CM_ SG_ 2231452929 DATC_IsgInhbtReq "DATC_IsgInhibitRequset";
CM_ SG_ 2231452929 DATC_AcnCompOnReq "DATC_AirconCompressorOnRequest";
CM_ SG_ 2231452929 DATC_SrvLmpReq "DATC_ServiceLampRequest";
CM_ SG_ 2231452929 DATC_EcvFltSta "DATC_EcvFaultStatus";
CM_ SG_ 2231452929 DATC_CalcAcnCompTqVal "DATC_CalculatedAirconCompressortorqueValue";
CM_ BO_ 2231452930 "[P] Periodic";
CM_ SG_ 2231452930 DATC_AcnECompOpSta "DATC_AirconElectricCompressorOperationStatus";
CM_ SG_ 2231452930 DATC_HVCompIntlkSta "DATC_HighVoltageCompressorInterlockStatus";
CM_ SG_ 2231452930 DATC_HVIntDischrgLkReq "DATC_HighVoltageInterlockDischargeRequest";
CM_ SG_ 2231452930 DATC_AcnECompMaxReqPwrVal "DATC_AirconElectricalCompressorMaximumRequestPowerValue";
CM_ SG_ 2231452930 DATC_AcnCompFltSta "DATC_AirconElectricCompressorFaultStatus";
CM_ SG_ 2231452930 DATC_AcnECompCnsmptPwrVal "DATC_AirconElectricalCompressorConsumptionPowerValue";
CM_ SG_ 2231452930 DATC_MainRlyOffReq "DATC_MainRelayoffRequest";
CM_ SG_ 2231452930 DATC_MixDfgSelSta "DATC_MixDefogSelectStatus";
CM_ SG_ 2231452930 DATC_BattChlrVlvSta "Battery chiller valve status";
CM_ SG_ 2231452930 DATC_WaterPmpOnReq "DATC_WaterPumpOnRequest";
CM_ SG_ 2231452930 DATC_AcnECompSpdVal "DATC_AirconElectricalCompressorSpeedValue";
CM_ SG_ 2231452930 DATC_AcnCompSlpModCodVal "DATC_AirconCompressorSleepModeCodeValue";
CM_ SG_ 2231452930 DATC_RrDfgOpSta "DATC_RearDefogOperatingState";
CM_ SG_ 2231452930 DATC_AcnECompCANFltSta "DATC_AirconElectricalCompressorCANFaultStatus";
CM_ BO_ 2231452931 "[P] Periodic";
CM_ SG_ 2231452931 DATC_AcnCompWaitCodVal "DATC_AirconCompressorWaitCode";
CM_ SG_ 2231452931 DATC_PeEwpRPMReq "DATC_PeEwpRpmRequest";
CM_ SG_ 2231452931 DATC_AEwpSpdRpmReq "DATC_AsistenceEwpSpeedRpmRequest";
CM_ SG_ 2231452931 DATC_RadFanReq_Duty "This signal indicates Request cooling fan speed to cool HVAC System (Duty)";
CM_ SG_ 2231452931 DATC_OutTempSnsrVal "DATC_OutsideTemperatureSensorValue";
CM_ SG_ 2231452931 DATC_ActvEco "DATC_ActiveEco";
CM_ SG_ 2231452931 DATC_AUTOActv "DATCAutoActivation";
CM_ SG_ 2231452931 DATC_DfgSw "DATC_DefogSwitch";
CM_ SG_ 2231452931 DATC_BattChlrVlv_FltCode "Battery Chiller Filt Code";
CM_ SG_ 2231452931 DATC_BattEvapVlvSta "BATTERY COOL V/V (EVAP) STATUS";
CM_ SG_ 2231452931 DATC_BattEvapVlv_FltCode "BATTERY COOL V/V (EVAP) FltCode";
CM_ SG_ 2231452931 DATC_Wrmup "Complete of warmup";
CM_ SG_ 2231452931 DATC_SSC_EngStrtReq "Engine start request in SSC state";
CM_ SG_ 2231452931 DATC_AcnCompSta "DATC_AirconCompressorStatus";
CM_ BO_ 2231452932 "[P] Periodic";
CM_ SG_ 2231452932 DATC_SSC_InhbtReq "Request to EMS not to enter SSC";
CM_ SG_ 2231452932 DATC_EngIdlRpmUpReq "DATC_EngineIdleRpmUpRequest";
CM_ SG_ 2231452932 DATC_MaxBlwVolt "DATC_MaxBlowerVoltage";
CM_ SG_ 2231452932 DATC_HVACPmpOpSta "HVAC Pump Operation Status";
CM_ SG_ 2231452932 DATC_MildWrmup "Mild Warmup State";
CM_ SG_ 2231452932 DATC_BattEwpOpReq "Battery EWP Operating Request";
CM_ BO_ 649 "[EC] On Event and On Change";
CM_ SG_ 649 DLBCU_SmartCtrl_1h "½º¸¶Æ® ÀÚ¼¼Á¦¾î DLBCU ¿¬µ¿ Á¶Àý¿¡ µû¸¥ °³¼±ÇöÈ² AVN Ç¥½Ã¹®±¸_1½Ã°£";
CM_ SG_ 649 DLBCU_SmartCtrl_2h "½º¸¶Æ® ÀÚ¼¼Á¦¾î DLBCU ¿¬µ¿ Á¶Àý¿¡ µû¸¥ °³¼±ÇöÈ² AVN Ç¥½Ã ¹®±¸_2½Ã°£";
CM_ SG_ 649 DLBCU_SmartCtrl_Status "½º¸¶Æ® ÀÚ¼¼Á¦¾î 2´Ü°è DLBCU ¿¬µ¿ Á¶Àý µ¿ÀÛ ½ÃÀÛ / Á¾·á / Áß´Ü AVN ÆË¾÷";
CM_ BO_ 1159 "[PE] Periodic and On Event";
CM_ SG_ 1159 C_AstRclBwdSw_HU "Assistant seat Moving control :Recline Backward";
CM_ SG_ 1159 C_AstHeightUpSw_HU "Assistant seat Moving control : Height Up";
CM_ SG_ 1159 C_AstTiltDnSw_HU "Assistant seat Moving control : Tilt Down";
CM_ SG_ 1159 C_AstTiltUpSw_HU "Assistant seat Moving Switch : Tilt Up";
CM_ SG_ 1159 C_AstLumbarDefSw_HU "Assistant seat moving switch: Deflate";
CM_ SG_ 1159 C_AstLumbarLowSw_HU "Assistant seat moving switch:Lumbar Low";
CM_ SG_ 1159 C_AstRclFwdSw_HU "Assistant seat Moving Switch : Recline Forward";
CM_ SG_ 1159 C_AstLumbarMidSw_HU "Assistant seat Moving control : Lumbar Mid";
CM_ SG_ 1159 C_AstLumbarUpSw_HU "Assistant seat Moving control : Lumbar Up";
CM_ SG_ 1159 C_RRSlideFwdSw_HU "2nd Right side seat Moving control :Power Slide Forward";
CM_ SG_ 1159 C_RRSlideBwdSw_HU "2nd Right side seat Moving control :Power Slide Backward";
CM_ SG_ 1159 C_RLSlideFwdSw_HU "2nd Left side seat Moving control :Power Slide Forward";
CM_ SG_ 1159 C_RLSlideBwdSw_HU "2nd Left side seat Moving control :Power Slide Backward";
CM_ SG_ 1159 C_AstSlideBwdSw_HU "Assistant seat moving switch : Slide Backward";
CM_ SG_ 1159 C_AstSlideFwdSw_HU "Assistant seat Moving switch : Slide Forward";
CM_ SG_ 1159 C_AstHeightDnSw_HU "Assistant seat Moving control : Height Down";
CM_ BO_ 197 "[PE] Periodic and On Event";
CM_ SG_ 197 C_DrvRclBwdSw_HU "Driver Seat Recline Backward Control";
CM_ SG_ 197 C_DrvSlideFwdSw_HU "Driver Seat Slide Forward Control";
CM_ SG_ 197 C_RLLegSupFwdSw_HU "2nd Left side seat Moving control : Leg Support Forward";
CM_ SG_ 197 C_RLLegSupBwdSw_HU "2nd Left side seat Moving control : Leg Support Backward";
CM_ SG_ 197 C_DrvSlideBwdSw_HU "Driver Seat Slide Backward Control";
CM_ SG_ 197 C_RLLegSupUpSw_HU "2nd Left side seat Moving control : Leg Support Up";
CM_ SG_ 197 C_RLLegSupDnSw_HU "2nd Left side seat Moving control : Leg Support Down";
CM_ SG_ 197 C_DrvRclFwdSw_HU "Driver Seat Recline Forward Control";
CM_ BO_ 172 "[EC] On Event and On Change";
CM_ SG_ 172 BLTN_CAM_FR_VerPos_NvalueSet "Front Camera Vertical position setting value.";
CM_ SG_ 172 BLTN_CAM_AppNoti_PEV_NvalueSet "Parked Event notification to Connectivity Phone App. On/Off";
CM_ SG_ 172 BLTN_CAM_WiFi_AutoOn_NvalueSet "Wifi On/Off User setting";
CM_ SG_ 172 BLTN_CAM_StoProp_NvalueSet "Propotion of built-in Cam SD card Propotion set of the Recording Categories";
CM_ SG_ 172 CF_AVN_BLTN_CAM_USMReset "Buit-in Cam USM Reset Request.";
CM_ SG_ 172 CF_AVN_BLTN_CAM_RecReset "Buit-in Cam format(all file delete/Reset) Request.";
CM_ SG_ 172 BLTN_CAM_File_DEL_CPY_Cmd "Buit-in Cam operation control of copying and deleting.";
CM_ SG_ 172 BLTN_CAM_LVDS_Mode_Cmd "This Signal is for LVDS output commend to BLTN_CAM";
CM_ SG_ 172 HU_BLTN_CAM_Disp_Touch_Pos_X "X position of touch of display when BLTN-in CAM Engineer mode in";
CM_ SG_ 172 HU_BLTN_CAM_Disp_Touch_Pos_Y "Y position of touch of display when BLTN-in CAM Engineer mode in";
CM_ SG_ 172 BLTN_CAM_RR_VerPos_NvalueSet "Rear Camera Vertical position setting value.";
CM_ BO_ 1264 "[PE] Periodic and On Event";
CM_ SG_ 1264 HU_TimeSetting "Information for current time setting";
CM_ SG_ 1264 HU_DisplayMinute "Information for time display in Minute unit";
CM_ SG_ 1264 HU_Status "Information for H/U status
Transmitted on H/U status changing";
CM_ SG_ 1264 HU_DisplaySecond "Information for time display in Second unit";
CM_ SG_ 1264 HU_DisplayMonth "Information for Month";
CM_ SG_ 1264 HU_DisplayYear1 "Information for Year (XXOO)
XX : HU_DisplayYear1
OO: HU_DisplayYear2";
CM_ SG_ 1264 HU_DisplayYear2 "Information for Year (XXOO)
XX : HU_DisplayYear1
OO: HU_DisplayYear2";
CM_ SG_ 1264 HU_DisplayDay "Information for Day";
CM_ SG_ 1264 HU_AM_PM_INFO "Information for AM/PM";
CM_ SG_ 1264 HU_TimeFormat "Information for time format
Digital CLOCK only";
CM_ SG_ 1264 HU_DisplayHour "Information for time display in Hour unit";
CM_ BO_ 1266 "[PE] Periodic and On Event";
CM_ SG_ 1266 HU_LanguageInfo "Information for System Language (for Display Font)";
CM_ SG_ 1266 HU_MuteStatus "Information for System Mute Display";
CM_ SG_ 1266 HU_WelcomeReady "HU playback ready signal to play welcome animation video";
CM_ SG_ 1266 HU_UsmSupport "Information whether HU can support USM or not";
CM_ SG_ 1266 HU_NaviStatus "Information for Navigation Status (Booting, Normal Operation, No SD card)
-AVN NAVI Transmission Signal";
CM_ SG_ 1266 HU_NaviDisp "Information for Navi Display status on Front Monitor";
CM_ SG_ 1266 HU_BVM_Display_Message "BVM Operation Message";
CM_ SG_ 1266 HU_SVM_View_Display "BVM View display to cluster";
CM_ SG_ 1266 HU_NaviCamSettingStatus "Information for Navi Camera alert setting status

+ Bit-coded field (On 1, Off 0)
   - bit 0 : Fixed Camera
   - bit 1 : Signal/Speed Violation Camera
   - bit 2 : Movable Camera
   - bit 3 : User Registration Fixed Camera
   - bit 4 : User Registration Signal/Speed Violation Camera
   - bit 5~6 : Reserved
-AVN NAVI Transmission Signal";
CM_ SG_ 1266 HU_EVSupport "Notification whether EV function support or not.";
CM_ SG_ 1266 HU_AutoBrightState_New "HU Display Brightness State(When automatically adjusted)";
CM_ SG_ 1266 HU_VolumeStatus "Information for AVN Volume";
CM_ BO_ 1267 "[PE] Periodic and On Event";
CM_ SG_ 1267 RSELockOnOff "Command for RSE Lock Requst from Head Unit";
CM_ SG_ 1267 HU_DATC_RearLockSet "This signal is rear DATC(MTC) lock siganl when no RRC option";
CM_ SG_ 1267 HU_Graphreset_Info "Command for Hybrid Vehicle Fuel Economy Graph Reset Information
-Transmitting to Cluster when drivers agree 'Graph Reset'
-Keep the Value of Avergae Fuel Consumption and Line on the Graph";
CM_ SG_ 1267 HU_PhoneActivity "Information for Acitivity of Phone Call (For All area)";
CM_ SG_ 1267 HU_VRActivity "Information for Acitivity of VR (For All area)";
CM_ SG_ 1267 HU_DATC_AirQuality_Info "AirQuality Information";
CM_ BO_ 1265 "[PE] Periodic and On Event";
CM_ SG_ 1265 HU_IG3_Request "IG3 wake up and sleep request for EV/PHEV";
CM_ SG_ 1265 HU_TeleVehicleStatusReq "Request vehicle status information.";
CM_ SG_ 1265 HU_Background "HU Backgound image info";
CM_ SG_ 1265 ccIC_HUD_PbackSta "Status signal for HUD interoperation with IMS";
CM_ SG_ 1265 HU_BackgroundFadeInOut "HU Background Fade in/out info - (HEX * Factor) %";
CM_ BO_ 1278 "[PE] Periodic and On Event";
CM_ SG_ 1278 HU_Type "Information for H/U Platform type
- Integrated AVN 1.0 use different value depends on development company (Mobis:0x68/LG:0x70)
- Integrated AVN 1.0 Mobis is developed based on Display Audio
- Integrated AVN 1.0 LG is developed based on Compact AVN

Information for China OPIO Platform
- 0xFC: China OPIO w/o CLU interface (most of phase1)
- 0xFD: China OPIO w/CLU interface (parts of phase1, phase2)

Information for Audio Platform Type
- 0x43 : Audio 4.0 Value";
CM_ SG_ 1278 HU_DistributeInfo "Region :Europe/North America/
Vehicle Type : RHD/LHD
Positionning information";
CM_ SG_ 1278 HU_OptionInfo "Information of H/U functions";
CM_ SG_ 1278 HU_NaviMapInfo "Information about map data  used in Navigation";
CM_ SG_ 1278 HU_NaviHandshakingSupport "This is a signal to send whether handshaking logic is applied related to Navigation's 'Map based ADAS' specification";
CM_ SG_ 1278 HU_AMP_EQVariant "Set EQ Variant for various vehicle cases.
During the AMP initializing process, This signal should be sent before AMP unmute.
This signal is only needed for models that have variant EQ for vehicle types. (Hatchback, Wagon, Hybrid etc..)
Models that doesn¡¯t have variant EQ for vehicle types shouldn¡¯t have this signal.";
CM_ SG_ 1278 HU_AdasSupport "Information about ADAS support
-Classify between General Map and Precise Map Transmission Function
-AVN System Transmission Signal";
CM_ SG_ 1278 HU_Navi_RspADASMapMsg "HU_ResponseADASMapMessage";
CM_ BO_ 1279 "[EC] On Event and On Change";
CM_ SG_ 1279 USM_SmartRegen_Map_Set "Smart Regeneration 2.0 Map information USM User set signal";
CM_ SG_ 1279 USM_SmartRegen_Sens_Set "Smart Regeneration User Personality of Reduction Set Signal";
CM_ SG_ 1279 AVN_SeatPosMemory_Btn "Seat position save signal";
CM_ SG_ 1279 AVN_SeatPosPlyBck_Btn "Seat position move signal";
CM_ SG_ 1279 USM_CMSBrgtnsReset "CMS Brightness Reset (LH/RH)";
CM_ SG_ 1279 CF_AVN_1stRrStRmndNValueSet "This signal is for setting the ROA function when IBU control ROA Function.";
CM_ SG_ 1279 AVN_Usm_CluThemeSta_New "This signal is u sed for a Cluster Theme setitng.";
CM_ SG_ 1279 VESS_ChgGuideMdLvl "Releated to VESS Alarm Sound Level";
CM_ BO_ 200 "[EC] On Event and On Change";
CM_ SG_ 200 CF_AVN_BodySpprtSet_AST "This signal is for the Ergo-Motion seat (AST) body support (Smart Posture Assist) USM";
CM_ SG_ 200 CF_AVN_AirSptTimeNValueSet_AST "This signal is for the Ergo-Motion seat (AST) massage function time setting";
CM_ SG_ 200 CF_AVN_AirSptStrNValue_AST "This signal is for the ERGO seat (AST) massage intensity USM";
CM_ SG_ 200 CF_AVN_SeatDrvModNvalueSet_AST "This signal is for the Ergo-Motion seat (AST) smart support (Smart Support) USM";
CM_ BO_ 2172675330 "[P] Periodic";
CM_ SG_ 2172675330 IEB_Sta "IEB_Status ##2G##ESC - EBS1 - CF_Brk_EBSStat";
CM_ SG_ 2172675330 IEB_SnsrFailSta "IEB_SensorFailStatus ##2G##ESC - EBS1 - CF_Brk_SnsFail";
CM_ SG_ 2172675330 IEB_EstTtlBrkFrcNmVal "IEB_EstimatedTotalBrakeForceValue ##2G##ESC - EBS1 - CR_Brk_EstTot_Nm";
CM_ SG_ 2172675330 IEB_RbsWrngLmpSta "IEB_RbsWarningLamp ##2G##ESC - EBS1 - CF_Brk_RBSWLamp";
CM_ SG_ 2172675330 IEB_StrkDpthPcVal "IEB_StrokeDepthPcValue ##2G##ESC - EBS2 - CR_Brk_StkDep_Pc";
CM_ SG_ 2172675330 IEB_EstDpthPcVal "IEB_EstimatedPedalDepthValue ##2G##ESC - EBS2 - CR_Brk_Est_StkDep_Pc";
CM_ SG_ 2172675330 IEB_AbsNGearReq "IEB_AbsNGearRequest ##2G##ESC - TCS11 - CF_Brk_AbsNReq";
CM_ SG_ 2172675330 IEB_EstBrkPdlValVldSta "IEB_EstimatedBrakePedalValueValidityStatus ##2G##ESC - EBS2 - CF_Brk_Est_StkValid";
CM_ SG_ 2172675330 IEB_VacSysDfctvSta "IEB_VacuumSystemDefectiveStatus ##2G##ESC - EBS1 - CF_Brk_VacuumSysDef";
CM_ SG_ 2172675330 IEB_RegenTqLimitNmVal_Frnt "IEB_RegenTorqueLimitValue ##2G##ESC - EBS1 - CR_Brk_RegenTqLimit_Nm";
CM_ BO_ 2172675331 "[P] Periodic";
CM_ SG_ 2172675331 IEB_RegenTqLimitNmVal_Rear "IEB_RegenTorqueLimitValue Rear";
CM_ SG_ 2172675331 IEB_DrvWhlSlipFlg_Frnt "Slip status of driving wheel ##2G##ESC ? EBS2 ? CF_Brk_DrvWhlSlipFlg";
CM_ SG_ 2172675331 IEB_TCS_Req "IEB_TCS_Request";
CM_ SG_ 2172675331 IEB_RSC_Req "IEB_RSC_Request";
CM_ SG_ 2172675331 TCS_TqFlag_Frnt "TCS_TorqueFlag_Front";
CM_ SG_ 2172675331 TCS_TqFlag_Rear "TCS_TorqueFlag_Rear";
CM_ SG_ 2172675331 RSC_TqFlag_Frnt "RSC_TorqueFlag_Front";
CM_ SG_ 2172675331 RSC_TqFlag_Rear "RSC_TorqueFlag_Rear";
CM_ SG_ 2172675331 TCS_TqIntrvntnVal_Frnt "TCS_TorqueInterventionValue_Front";
CM_ SG_ 2172675331 TCS_TqIntrvntnVal_Rear "TCS_TorqueInterventionValue_Rear";
CM_ SG_ 2172675331 RSC_TqIntrvntnVal_Frnt "RSC_TorqueInterventionValue_Front";
CM_ SG_ 2172675331 RSC_TqIntrvntnVal_Rear "RSC_TorqueInterventionValue_Rear";
CM_ BO_ 191 "[PE] Periodic and On Event";
CM_ SG_ 191 RL_SHVU_DTCdisplay "0x00: DTC is not exist(Fail is not exist)/0x01:IGN2 Fuse Open Detection/0x02:Switch Input Detection at Same Time/0x03:NTC/Heating wire Open Detection/0x04:NTC+/NTC- Terminal Short Detection/0x05:NTC+/Heater+ Terminal Short Detection/0x06:NTC+/Heater-, Heater+/Heater-, Heater+/NTC- Terminal Short Detection/0x07:NTC+/Heater- Wiring Short Detection/0x08:NTC+/Heater-, Heater+/Heater-, Heater+/NTC- Wiring Short Detection/0x09:Target Temperature Dissatisfied/0x0A:Blower+/Blower- Short, Blower+/Blower Speed, Blower-/Blower Speed Wiring Short Detection/0x0B:Blower+/Blower RPM, Blower-/Blower RPM, Blower Speed/Blower RPM Short Detection/0x0C:Blower+, Blower-, Blower Speed Signal open Detection/0x0D:Blower RPM signal Open Detection/0x0E~0xFD:Unused/0xFE:No Display/0xFF:Invalid";
CM_ SG_ 191 RL_SHVU_DiagMode "0x0:Default/0x1:DTC Mode/0x2:Normal Mode/0x3:Invalid";
CM_ BO_ 2328016129 "[P] Periodic";
CM_ SG_ 2328016129 VCU_Crc5Val "VCU_CyclicRedundancyCheck5Value";
CM_ SG_ 2328016129 VCU_AlvCnt5Val "VCU_AliveCounter5Value";
CM_ SG_ 2328016129 VCU_EvDrvRdyCluDispSta "VCU_EvDriveReadyClusterDisplayStatus ##2G##VCU - VCU1 - CF_Vcu_EvRdyClu";
CM_ SG_ 2328016129 VCU_PwrDnModeSta "VCU_PowerDownModeStatus ##2G##VCU - VCU5 - CF_Vcu_PwrDnMode";
CM_ SG_ 2328016129 VCU_CluWarnMsgSta "VCU_ClusterWarningMessageStatus ##2G##VCU - VCU7 - CF_Vcu_WarnMsg";
CM_ SG_ 2328016129 VCU_DteOffDispSta "VCU_DteOffDisplayStatus ##2G##VCU - VCU5 - CF_Vcu_DteOff";
CM_ SG_ 2328016129 VCU_LowSocAlertSta "VCU_LowSocAlertStatus ##2G##VCU - VCU3 - CF_Vcu_LowSocAlert";
CM_ SG_ 2328016129 VCU_VcrmReq "VCU_VcrmRequest ##2G##VCU - VCU3 - CF_Vcu_Vcrm_Req";
CM_ SG_ 2328016129 VCU_PdlWarnMsgSta "VCU_PaddleWarningMassageStatus";
CM_ SG_ 2328016129 VCU_AwdDiagDispSta "VCU_AwdDiagnosisDisplayStatus";
CM_ SG_ 2328016129 VCU_AwdLockDispSta "VCU_AwdLockDisplayStatus";
CM_ SG_ 2328016129 VCU_VirtualApsActSta "VCU_VirtualApsActivatedStatus ##2G##VCU - VCU1 - CF_Vcu_EstApsSel";
CM_ SG_ 2328016129 VCU_VirtualApsVal "VCU_VirtualApsValue ##2G##VCU - VCU1 - CR_Vcu_EstAccPed_PC";
CM_ SG_ 2328016129 VCU_ServiceLampReq "VCU_SeviceLampRequest ##2G##VCU - VCU5 - CF_Vcu_SerLamp";
CM_ SG_ 2328016129 VCU_ServiceModeSta "VCU_ServiceModeStatus ##2G##VCU - VCU2 - CF_Vcu_ServiceMod";
CM_ SG_ 2328016129 VCU_NPosWshModSta "VCU_NPositionWashModeStatus";
CM_ SG_ 2328016129 VCU_PowerTrainType "VCU_PowerTrainType";
CM_ BO_ 2328016130 "[P] Periodic";
CM_ SG_ 2328016130 VCU_DteBaseVal "VCU_DteBaseValue ##2G##VCU - VCU1 - CR_Vcu_DistEmpty_km(VCU6 - CR_Vcu_DistEmpty_km)";
CM_ SG_ 2328016130 VCU_AvnDteOnCalcSta "VCU_AvnDteOnCalculationStatus ##2G##VCU - VCU1 - CF_Vcu_AvnDteCalc(VCU6 - CF_Vcu_AvnDteCalc)";
CM_ SG_ 2328016130 VCU_SbwWarnMsgSta "VCU_SbwWarningMessageStatus ##2G##VCU - VCU20 - CF_Vcu_SbwWarnMsg";
CM_ SG_ 2328016130 VCU_DteNaviRouteVal "VCU_DteNaviRouteValue ##2G##VCU - VCU3 - CR_Vcu_DistEmptyAvn_km";
CM_ SG_ 2328016130 VCU_DteAddVal "VCU_DteAddedValue ##2G##VCU - VCU1 - CR_Vcu_DistEmptyAdd_km(VCU6 - CR_Vcu_DistEmptyAdd_km)";
CM_ SG_ 2328016130 VCU_PwrGaugeVal "VCU_PowerGaugeValue ##2G##VCU - VCU5 - CR_Vcu_TqMotClu_Pc";
CM_ SG_ 2328016130 VCU_EnergyFlowSta "VCU_EnergyFlowStatus ##2G##VCU - VCU5 - CF_Vcu_EvMod";
CM_ SG_ 2328016130 VCU_SbwWarnSndSta "VCU_SbwWarningSoundStatus ##2G##VCU - VCU20 - CF_Vcu_SbwWarnSnd";
CM_ SG_ 2328016130 VCU_EcoGuide_DispReq "VCU_EcoGuide_DisplayRequest ##2G##VCU - VCU7 - CF_Vcu_SmartEcoDisp";
CM_ SG_ 2328016130 VCU_EcoGuide_ApsGaugeVal "VCU_EcoGuide_ApsGaugeValue ##2G##VCU - VCU7 - CR_Vcu_SmartEcoLvl";
CM_ SG_ 2328016130 VCU_EcoGuide_EcoGaugeVal "VCU_EcoGuide_EcoGaugeValue ##2G##VCU - VCU7 - CR_Vcu_SmartEcoRng";
CM_ BO_ 2328016131 "[P] Periodic";
CM_ SG_ 2328016131 VCU_TgSocDteAcChgVal "VCU_TargetSocDte(Sc/Ac)ChargerValue ##2G##VCU - VCU19 - CR_Vcu_TgSocDte_AcChg";
CM_ SG_ 2328016131 VCU_TgSocDteDcChgVal "VCU_TargetSocDte(Qc/Dc)ChargerValue ##2G##VCU - VCU19 - CR_Vcu_TgSocDte_DcChg";
CM_ SG_ 2328016131 VCU_DistFromRegenDispReq "VCU_DistanceFromRegenerationDisplayRequest ##2G##VCU - VCU7 - CR_Vcu_RegenRangeAddSet";
CM_ SG_ 2328016131 VCU_DistFromRegenVal "VCU_DistanceFromRegenerationValue ##2G##VCU - VCU7 - CR_Vcu_RegenRangeAdd";
CM_ SG_ 2328016131 VCU_DrvStyle_DispReq "VCU_DriveStyle_DisplayRequest ##2G##VCU - VCU7 - CF_Vcu_FueEffStat";
CM_ SG_ 2328016131 VCU_DrvStyle_HighLightSta "VCU_DriveStyle_HighLightStatus ##2G##VCU - VCU7 - CF_Vcu_FueEffStatBox";
CM_ SG_ 2328016131 VCU_DrvStyle_EcoVal "VCU_DriveStyle_EcoValue ##2G##VCU - VCU7 - CR_Vcu_HighFueEff_Pc";
CM_ SG_ 2328016131 VCU_DrvStyle_NonEcoVal "VCU_DriveStyle_NonEcoValue ##2G##VCU - VCU7 - CR_Vcu_LowFueEff_Pc";
CM_ SG_ 2328016131 VCU_DrvStyle_NorVal "VCU_DriveStyle_NorValue ##2G##VCU - VCU7 - CR_Vcu_NorFueEff_Pc";
CM_ BO_ 2328016132 "[P] Periodic";
CM_ SG_ 2328016132 VCU_LowSocDispPcVal "VCU_LowSocDisplayPercentValue";
CM_ SG_ 2328016132 VCU_DteSocBasedVal "VCU_DteSocBasedValue";
CM_ SG_ 2328016132 VCU_InstFuelEcoVal_Per100km "VCU_InstantFuelEconomy(kWh/100km) ##2G##VCU - VCU5 - CR_Vcu_FuelEco_KP100km";
CM_ SG_ 2328016132 VCU_InstFuelEcoVal_PerkWh "VCU_InstantFuelEconomyValue_(km/kWh) ##2G##VCU - VCU5 - CR_Vcu_FuelEco_KPK";
CM_ SG_ 2328016132 VCU_CO2RdcTripDistVal "VCU_CO2ReductionTripDistanceValue ##2G##VCU - VCU4 - CF_Vcu_CO2RdcTripDist";
CM_ SG_ 2328016132 VCU_CO2RdcVal "VCU_CO2ReductionValue ##2G##VCU - VCU4 - CF_Vcu_CO2Rdc";
CM_ SG_ 2328016132 VCU_StopCtrlWarnMsgSta "i-Pedal Warning Message Status";
CM_ SG_ 2328016132 VCU_DrvModeDefault "Drive Mode(Default Mode) Value for Cluster Display(EV)";
CM_ SG_ 2328016132 VCU_DrvModeLast "This signal is the drive mode that needs to maintain on restart";
BA_DEF_ BO_ "DiagState" ENUM "No","Yes" ;
BA_DEF_ BO_ "DiagResponse" ENUM "No","Yes" ;
BA_DEF_ BO_ "DiagRequest" ENUM "No","Yes" ;
BA_DEF_ BO_ "TpMessage" ENUM "No","Yes" ;
BA_DEF_ BO_ "UsrMsgIDSforwardDeviation" INT 0 100 ;
BA_DEF_ BO_ "UsrMsgIDSbackwardDeviation" INT 50 1000 ;
BA_DEF_ BO_ "GenMsgCycleTime" INT 0 2000 ;
BA_DEF_ BO_ "GenMsgStartDelayTime" INT 0 2000 ;
BA_DEF_ BO_ "GenMsgSendType" ENUM "Cyclic","NoMsgSendType" ;
BA_DEF_ BO_ "GenMsgCycleTimeFast" INT 0 500 ;
BA_DEF_ BO_ "GenMsgDelayTime" INT 0 20 ;
BA_DEF_ BO_ "GenMsgILSupport" ENUM "No","Yes" ;
BA_DEF_ BO_ "GenMsgNrOfRepetition" INT 0 3 ;
BA_DEF_ BO_ "NmMessage" ENUM "No","Yes" ;
BA_DEF_ BO_ "NWM-Botschaft" ENUM "No","Yes" ;
BA_DEF_ BO_ "TpTxIndex" INT 0 255 ;
BA_DEF_ BO_ "VFrameFormat" ENUM "StandardCAN","ExtendedCAN","reserved","reserved","reserved","reserved","reserved","reserved","reserved","reserved","reserved","reserved","reserved","reserved","StandardCAN_FD","ExtendedCAN_FD" ;
BA_DEF_ SG_ "UserSigValidity" ENUM "B+","ACC","IG","IG1","IG2","IG3","IG1 or IG2","IG1 or IG3","Undef" ;
BA_DEF_ SG_ "TimeoutValue" STRING ;
BA_DEF_ SG_ "UsrSigPurpose" ENUM "Undef","FN","DIAG","DIAG(Req)","DIAG(Res)","DIAG(Phy)","DEV","CCP(Req)","CCP(Res)","NM","TP" ;
BA_DEF_ SG_ "GenSigStartValue" INT 0 1215752192 ;
BA_DEF_ SG_ "NetworkRequest" ENUM "Yes","No" ;
BA_DEF_ SG_ "NetworkRequestHoldingTime" INT 0 65535 ;
BA_DEF_ SG_ "Description" STRING ;
BA_DEF_ SG_ "Version" STRING ;
BA_DEF_ SG_ "GenSigEnvVarType" ENUM "Int","Float","Undef" ;
BA_DEF_ SG_ "GenSigSendType" ENUM "Cyclic","OnWrite","OnWriteWithRepetition","OnChange","OnChangeWithRepetition","IfActive","IfActiveWithRepetition","NoSigSendType","OnChangeAndIfActive","OnChangeAndIfActiveWithRepetition" ;
BA_DEF_ SG_ "GwSigLatencyTime" INT 0 65536 ;
BA_DEF_ SG_ "GwSigMissingSourceType" ENUM "Undef","OldValue","DefaultValue","InitialValue" ;
BA_DEF_ SG_ "NWM-WakeupAllowed" ENUM "<n.a.>" ;
BA_DEF_ SG_ "RoutingFactor" INT 1 1215752192 ;
BA_DEF_REL_ BU_SG_REL_ "GenSigTimeoutTime" INT 0 7000 ;
BA_DEF_DEF_ "DiagState" "No" ;
BA_DEF_DEF_ "DiagResponse" "No" ;
BA_DEF_DEF_ "DiagRequest" "No" ;
BA_DEF_DEF_ "TpMessage" "No" ;
BA_DEF_DEF_ "UsrMsgIDSforwardDeviation" 10 ;
BA_DEF_DEF_ "UsrMsgIDSbackwardDeviation" 100 ;
BA_DEF_DEF_ "GenMsgCycleTime" 200 ;
BA_DEF_DEF_ "GenMsgStartDelayTime" 0 ;
BA_DEF_DEF_ "GenMsgSendType" "NoMsgSendType" ;
BA_DEF_DEF_ "GenMsgCycleTimeFast" 40 ;
BA_DEF_DEF_ "GenMsgDelayTime" 20 ;
BA_DEF_DEF_ "GenMsgILSupport" "Yes" ;
BA_DEF_DEF_ "GenMsgNrOfRepetition" 3 ;
BA_DEF_DEF_ "NmMessage" "No" ;
BA_DEF_DEF_ "NWM-Botschaft" "No" ;
BA_DEF_DEF_ "TpTxIndex" 0 ;
BA_DEF_DEF_ "VFrameFormat" "StandardCAN" ;
BA_DEF_DEF_ "UserSigValidity" "IG" ;
BA_DEF_DEF_ "TimeoutValue" "" ;
BA_DEF_DEF_ "UsrSigPurpose" "FN" ;
BA_DEF_DEF_ "GenSigStartValue" 0 ;
BA_DEF_DEF_ "NetworkRequest" "No" ;
BA_DEF_DEF_ "NetworkRequestHoldingTime" 0 ;
BA_DEF_DEF_ "Description" "" ;
BA_DEF_DEF_ "Version" "" ;
BA_DEF_DEF_ "GenSigEnvVarType" "Undef" ;
BA_DEF_DEF_ "GenSigSendType" "NoSigSendType" ;
BA_DEF_DEF_ "GwSigLatencyTime" 40 ;
BA_DEF_DEF_ "GwSigMissingSourceType" "Undef" ;
BA_DEF_DEF_ "NWM-WakeupAllowed" "<n.a.>" ;
BA_DEF_DEF_ "RoutingFactor" 1 ;
BA_DEF_DEF_REL_ "GenSigTimeoutTime" 500 ;
BA_ "GenMsgSendType" BO_ 2227254529 0;
BA_ "GenMsgCycleTime" BO_ 2227254529 50;
BA_ "GenMsgCycleTimeFast" BO_ 2227254529 0;
BA_ "GenMsgNrOfRepetition" BO_ 2227254529 0;
BA_ "VFrameFormat" BO_ 2227254529 1;
BA_ "Description" SG_ 2227254529 BAT_Crc1Val "The data area for CRC calculation is based on the data length (DLC) of the message DB.

The CRC shall be calculated over the entire data block (excluding the CRC bytes) including the user data, alive counter and Data ID

 

- CRC Polynomial (0x1021) , Initial Value : 0xFFFF, XOR value : 0x0000, Data ID : Message ID + 0xF800 

- The initial value is for CRC calculation and the message should be sent with the calculated result value. 

- The mathematical expression to 16 bit CRC polynomial is given here. G(x) = x16 + x12 + x5 + 1";
BA_ "GenSigStartValue" SG_ 2227254529 BAT_Crc1Val 65535;
BA_ "UserSigValidity" SG_ 2227254529 BAT_Crc1Val 7;
BA_ "RoutingFactor" SG_ 2227254529 BAT_Crc1Val 5;
BA_ "Version" SG_ 2227254529 BAT_Crc1Val "18.11.08";
BA_ "Description" SG_ 2227254529 BAT_AlvCnt1Val "For the first transmission request for a data element the counter shall be initialized with 0 and shall be incremented by 1 for every subsequent send request. 

When the counter reaches the maximum value(0xFF), then it shall restart with 0 for the next send request";
BA_ "UserSigValidity" SG_ 2227254529 BAT_AlvCnt1Val 7;
BA_ "RoutingFactor" SG_ 2227254529 BAT_AlvCnt1Val 5;
BA_ "Version" SG_ 2227254529 BAT_AlvCnt1Val "18.11.08";
BA_ "Description" SG_ 2227254529 BAT_CurrVal "[For 12V Lithium Battery vehicle model]

This is Battery current as measured by battery sensor.

This value is  

   - IRANGE : 1 (medium current)

   - Resolution : 10mA";
BA_ "GenSigStartValue" SG_ 2227254529 BAT_CurrVal 65535;
BA_ "UserSigValidity" SG_ 2227254529 BAT_CurrVal 7;
BA_ "RoutingFactor" SG_ 2227254529 BAT_CurrVal 5;
BA_ "Version" SG_ 2227254529 BAT_CurrVal "17.11.00";
BA_ "Description" SG_ 2227254529 BAT_SocVal "[For 12V Lithium Battery vehicle model]

This signal is battery State of Charge as calculated by battery sensor.";
BA_ "UserSigValidity" SG_ 2227254529 BAT_SocVal 7;
BA_ "RoutingFactor" SG_ 2227254529 BAT_SocVal 5;
BA_ "Version" SG_ 2227254529 BAT_SocVal "19.01.00";
BA_ "Description" SG_ 2227254529 BAT_VoltVal "[For 12V Lithium Battery vehicle model]

This is the actual battery voltage as measured on the battery pole by battery sensor.

The Resolution is 1mV.";
BA_ "GenSigStartValue" SG_ 2227254529 BAT_VoltVal 16383;
BA_ "UserSigValidity" SG_ 2227254529 BAT_VoltVal 7;
BA_ "RoutingFactor" SG_ 2227254529 BAT_VoltVal 5;
BA_ "Version" SG_ 2227254529 BAT_VoltVal "17.11.00";
BA_ "GenMsgSendType" BO_ 2227254530 0;
BA_ "GenMsgCycleTime" BO_ 2227254530 50;
BA_ "GenMsgCycleTimeFast" BO_ 2227254530 0;
BA_ "GenMsgNrOfRepetition" BO_ 2227254530 0;
BA_ "VFrameFormat" BO_ 2227254530 1;
BA_ "Description" SG_ 2227254530 BAT_TempVal "This is actual battery electrolyte temperature value by battery sensor.

The value is calculated by a Battery Temperature Model, depending on measured temperature of the battery pole.

The resolution is 0.5¡É.";
BA_ "GenSigStartValue" SG_ 2227254530 BAT_TempVal 511;
BA_ "UserSigValidity" SG_ 2227254530 BAT_TempVal 7;
BA_ "RoutingFactor" SG_ 2227254530 BAT_TempVal 5;
BA_ "Version" SG_ 2227254530 BAT_TempVal "20.03.05";
BA_ "Description" SG_ 2227254530 BAT_SohVal "[For 12V Lithium Battery vehicle model]

This signal is battery State of Health(SOH) as calculated by battery sensor.

This value shows reduction rate of nominal capacity.

This value can be used for diagnosis information of application system.";
BA_ "GenSigStartValue" SG_ 2227254530 BAT_SohVal 127;
BA_ "UserSigValidity" SG_ 2227254530 BAT_SohVal 7;
BA_ "RoutingFactor" SG_ 2227254530 BAT_SohVal 5;
BA_ "Version" SG_ 2227254530 BAT_SohVal "17.11.00";
BA_ "Description" SG_ 2227254530 BAT_SnsrInvldSta "[For 12V Lithium Battery vehicle model]

This bit is Battery Sensor Invalid flag and setting condition is depending on Battery Sensor self diagnosis information.

 BS Invalid = 0 : BS is Valid Condition

 BS Invalid = 1 : BS is Invalid Condition";
BA_ "GenSigStartValue" SG_ 2227254530 BAT_SnsrInvldSta 1;
BA_ "UserSigValidity" SG_ 2227254530 BAT_SnsrInvldSta 7;
BA_ "RoutingFactor" SG_ 2227254530 BAT_SnsrInvldSta 5;
BA_ "Version" SG_ 2227254530 BAT_SnsrInvldSta "17.11.00";
BA_ "Description" SG_ 2227254530 BAT_SofVal "[For 12V Lithium Battery vehicle model]

This signal is battery State of Function(SOF) as calculated by battery sensor.

This value shows information about the battery ability to crank the engine (both of warm & cold cranking).

This value is prediction value of the minimum voltage for the next cranking.";
BA_ "GenSigStartValue" SG_ 2227254530 BAT_SofVal 127;
BA_ "UserSigValidity" SG_ 2227254530 BAT_SofVal 7;
BA_ "RoutingFactor" SG_ 2227254530 BAT_SofVal 5;
BA_ "Version" SG_ 2227254530 BAT_SofVal "17.11.00";
BA_ "Description" SG_ 2227254530 BAT_RspErrSta "[For 12V Lithium Battery vehicle model]

Battery Sensor shall send one status bit signal, Response_Error. Response_Error shall be set whenever a frame received by the node or a frame transmitted by the node contains an error in the response field.

Response_Error shall be cleared after transmission.

Based on this single bit the master node can conclude the following:

 -Response_Error = 0 : the node is operating correctly

 -Response_Error = 1 : the node has intermittent problems

 -The node did not answer : the node (or bus or master) has serious problems.";
BA_ "GenSigStartValue" SG_ 2227254530 BAT_RspErrSta 1;
BA_ "UserSigValidity" SG_ 2227254530 BAT_RspErrSta 7;
BA_ "RoutingFactor" SG_ 2227254530 BAT_RspErrSta 5;
BA_ "Version" SG_ 2227254530 BAT_RspErrSta "17.11.00";
BA_ "Description" SG_ 2227254530 BAT_CapacityVal "12V Battery Capacity Value";
BA_ "UserSigValidity" SG_ 2227254530 BAT_CapacityVal 7;
BA_ "RoutingFactor" SG_ 2227254530 BAT_CapacityVal 5;
BA_ "Version" SG_ 2227254530 BAT_CapacityVal "21.07.06";
BA_ "Description" SG_ 2227254530 BAT_SocErrSta "[For 12V Lithium Battery vehicle model]

This bit is flags for indication whether battery SOC detection value is plausible or not by battery sensor.

If it is set to value 0, then it means battery SOC is normal state.

If it is set to value 1, then it means battery SOC is implausible state.

 * Conditions to set value = 1

  1) There has no chance to recalibrate SOC after power on reset

  2) There has no SOC recalibration after last recalibration

  3) There has no chance to get a plausible CNOM value";
BA_ "GenSigStartValue" SG_ 2227254530 BAT_SocErrSta 1;
BA_ "UserSigValidity" SG_ 2227254530 BAT_SocErrSta 7;
BA_ "RoutingFactor" SG_ 2227254530 BAT_SocErrSta 5;
BA_ "Version" SG_ 2227254530 BAT_SocErrSta "19.01.00";
BA_ "GenMsgSendType" BO_ 2315421697 0;
BA_ "VFrameFormat" BO_ 2315421697 1;
BA_ "Description" SG_ 2315421697 CCU_AP_OTA_Crc1Val "The data area for CRC calculation is based on the data length (DLC) of the message DB.

The CRC shall be calculated over the entire data block (excluding the CRC bytes) including the user data, alive counter and Data ID

 

- CRC Polynomial (0x1021) , Initial Value : 0xFFFF, XOR value : 0x0000, Data ID : Message ID + 0xF800 

- The initial value is for CRC calculation and the message should be sent with the calculated result value. 

- The mathematical expression to 16 bit CRC polynomial is given here. G(x) = x16 + x12 + x5 + 1";
BA_ "GenSigSendType" SG_ 2315421697 CCU_AP_OTA_Crc1Val 4;
BA_ "GenSigStartValue" SG_ 2315421697 CCU_AP_OTA_Crc1Val 65535;
BA_ "UserSigValidity" SG_ 2315421697 CCU_AP_OTA_Crc1Val 3;
BA_REL_ "GenSigTimeoutTime" BU_SG_REL_ vDummy_HS_B SG_ 2315421697 CCU_AP_OTA_Crc1Val 1500;
BA_ "Version" SG_ 2315421697 CCU_AP_OTA_Crc1Val "19.12.02";
BA_ "Description" SG_ 2315421697 CCU_AP_OTA_AlvCnt1Val "For the first transmission request for a data element the counter shall be initialized with 0 and shall be incremented by 1 for every subsequent send request. 

When the counter reaches the maximum value(0xFF), then it shall restart with 0 for the next send request";
BA_ "GenSigSendType" SG_ 2315421697 CCU_AP_OTA_AlvCnt1Val 4;
BA_ "UserSigValidity" SG_ 2315421697 CCU_AP_OTA_AlvCnt1Val 3;
BA_REL_ "GenSigTimeoutTime" BU_SG_REL_ vDummy_HS_B SG_ 2315421697 CCU_AP_OTA_AlvCnt1Val 1500;
BA_ "Version" SG_ 2315421697 CCU_AP_OTA_AlvCnt1Val "19.12.02";
BA_ "GenSigSendType" SG_ 2315421697 CCU_OTA_mode 4;
BA_ "UserSigValidity" SG_ 2315421697 CCU_OTA_mode 0;
BA_ "Version" SG_ 2315421697 CCU_OTA_mode "20.01.01";
BA_ "GenSigSendType" SG_ 2315421697 CCU_OTA_IG3On_request 4;
BA_ "UserSigValidity" SG_ 2315421697 CCU_OTA_IG3On_request 0;
BA_ "Version" SG_ 2315421697 CCU_OTA_IG3On_request "20.01.02";
BA_ "GenSigSendType" SG_ 2315421697 OTA_Cond_Vehicle_Pwr 4;
BA_ "GenSigStartValue" SG_ 2315421697 OTA_Cond_Vehicle_Pwr 1;
BA_ "UserSigValidity" SG_ 2315421697 OTA_Cond_Vehicle_Pwr 0;
BA_ "Version" SG_ 2315421697 OTA_Cond_Vehicle_Pwr "20.11.03";
BA_ "GenSigSendType" SG_ 2315421697 OTA_Cond_Gear_P 4;
BA_ "GenSigStartValue" SG_ 2315421697 OTA_Cond_Gear_P 1;
BA_ "UserSigValidity" SG_ 2315421697 OTA_Cond_Gear_P 0;
BA_ "Version" SG_ 2315421697 OTA_Cond_Gear_P "20.11.03";
BA_ "GenSigSendType" SG_ 2315421697 OTA_Cond_Parking_Brk 4;
BA_ "GenSigStartValue" SG_ 2315421697 OTA_Cond_Parking_Brk 1;
BA_ "UserSigValidity" SG_ 2315421697 OTA_Cond_Parking_Brk 0;
BA_ "Version" SG_ 2315421697 OTA_Cond_Parking_Brk "20.11.03";
BA_ "GenSigSendType" SG_ 2315421697 OTA_Cond_Ext_Lamp 4;
BA_ "GenSigStartValue" SG_ 2315421697 OTA_Cond_Ext_Lamp 1;
BA_ "UserSigValidity" SG_ 2315421697 OTA_Cond_Ext_Lamp 0;
BA_ "Version" SG_ 2315421697 OTA_Cond_Ext_Lamp "20.11.03";
BA_ "GenSigSendType" SG_ 2315421697 OTA_Cond_Hood_Closed 4;
BA_ "GenSigStartValue" SG_ 2315421697 OTA_Cond_Hood_Closed 1;
BA_ "UserSigValidity" SG_ 2315421697 OTA_Cond_Hood_Closed 0;
BA_ "Version" SG_ 2315421697 OTA_Cond_Hood_Closed "20.11.03";
BA_ "Description" SG_ 2315421697 OTA_UI_Ready_request "OTA User Approval Popup Request Signal (to ccIC)";
BA_ "GenSigSendType" SG_ 2315421697 OTA_UI_Ready_request 4;
BA_ "UserSigValidity" SG_ 2315421697 OTA_UI_Ready_request 0;
BA_ "Version" SG_ 2315421697 OTA_UI_Ready_request "21.04.00";
BA_ "GenSigSendType" SG_ 2315421697 OTA_Result 4;
BA_ "UserSigValidity" SG_ 2315421697 OTA_Result 0;
BA_ "Version" SG_ 2315421697 OTA_Result "21.02.02";
BA_ "GenSigSendType" SG_ 2315421697 CF_AVN_InterAutoLockMode_Set2_Copy_1 4;
BA_ "UserSigValidity" SG_ 2315421697 CF_AVN_InterAutoLockMode_Set2_Copy_1 3;
BA_ "Version" SG_ 2315421697 CF_AVN_InterAutoLockMode_Set2_Copy_1 "20.09.00";
BA_ "GenSigSendType" SG_ 2315421697 CCU_OTA_EOU 4;
BA_ "UserSigValidity" SG_ 2315421697 CCU_OTA_EOU 0;
BA_ "Version" SG_ 2315421697 CCU_OTA_EOU "20.09.00";
BA_ "GenMsgCycleTime" BO_ 2470763009 0;
BA_ "VFrameFormat" BO_ 2470763009 1;
BA_ "Description" SG_ 2470763009 CLU_Crc9Val "The data area for CRC calculation is based on the data length (DLC) of the message DB.

The CRC shall be calculated over the entire data block (excluding the CRC bytes) including the user data, alive counter and Data ID

 

- CRC Polynomial (0x1021) , Initial Value : 0xFFFF, XOR value : 0x0000, Data ID : Message ID + 0xF800 

- The initial value is for CRC calculation and the message should be sent with the calculated result value. 

- The mathematical expression to 16 bit CRC polynomial is given here. G(x) = x16 + x12 + x5 + 1";
BA_ "GenSigSendType" SG_ 2470763009 CLU_Crc9Val 4;
BA_ "GenSigStartValue" SG_ 2470763009 CLU_Crc9Val 65535;
BA_ "UserSigValidity" SG_ 2470763009 CLU_Crc9Val 3;
BA_ "Version" SG_ 2470763009 CLU_Crc9Val "18.11.08";
BA_ "Description" SG_ 2470763009 CLU_AlvCnt9Val "For the first transmission request for a data element the counter shall be initialized with 0 and shall be incremented by 1 for every subsequent send request. 

When the counter reaches the maximum value(0xFF), then it shall restart with 0 for the next send request";
BA_ "GenSigSendType" SG_ 2470763009 CLU_AlvCnt9Val 4;
BA_ "UserSigValidity" SG_ 2470763009 CLU_AlvCnt9Val 3;
BA_ "Version" SG_ 2470763009 CLU_AlvCnt9Val "18.11.08";
BA_ "Description" SG_ 2470763009 USM_MdLmpClrSetReq "Request set the Mood Lamp Color";
BA_ "GenSigSendType" SG_ 2470763009 USM_MdLmpClrSetReq 4;
BA_ "UserSigValidity" SG_ 2470763009 USM_MdLmpClrSetReq 3;
BA_ "Version" SG_ 2470763009 USM_MdLmpClrSetReq "20.08.06";
BA_ "Description" SG_ 2470763009 USM_RrWiperRevSetReq "Request to set RearWiper Reverse Mode";
BA_ "GenSigSendType" SG_ 2470763009 USM_RrWiperRevSetReq 4;
BA_ "UserSigValidity" SG_ 2470763009 USM_RrWiperRevSetReq 3;
BA_ "Version" SG_ 2470763009 USM_RrWiperRevSetReq "17.11.00";
BA_ "Description" SG_ 2470763009 USM_RrStRemindSetReq "USM Function for RearSeatReminder on/off SW";
BA_ "GenSigSendType" SG_ 2470763009 USM_RrStRemindSetReq 4;
BA_ "UserSigValidity" SG_ 2470763009 USM_RrStRemindSetReq 3;
BA_ "Version" SG_ 2470763009 USM_RrStRemindSetReq "19.01.04";
BA_ "Description" SG_ 2470763009 USM_RrWpcSetReq "USM Function for REAR WPC(Wireless Phone Chager) on/off SW";
BA_ "GenSigSendType" SG_ 2470763009 USM_RrWpcSetReq 4;
BA_ "UserSigValidity" SG_ 2470763009 USM_RrWpcSetReq 3;
BA_ "Version" SG_ 2470763009 USM_RrWpcSetReq "17.11.00";
BA_ "Description" SG_ 2470763009 USM_WpcSetReq "USM Function for WPC(Wireless Phone Chager) on/off SW";
BA_ "GenSigSendType" SG_ 2470763009 USM_WpcSetReq 4;
BA_ "UserSigValidity" SG_ 2470763009 USM_WpcSetReq 3;
BA_REL_ "GenSigTimeoutTime" BU_SG_REL_ WPC SG_ 2470763009 USM_WpcSetReq 0;
BA_ "Version" SG_ 2470763009 USM_WpcSetReq "17.11.00";
BA_ "Description" SG_ 2470763009 USM_SeqLmpSetReq "This signal is used for a request to set the value of USM Menus. This signal requests to change status of SequencialLamp ON/OFF setting.





When this signal change, the message (CLU18) is sent 3 times.";
BA_ "GenSigSendType" SG_ 2470763009 USM_SeqLmpSetReq 4;
BA_ "UserSigValidity" SG_ 2470763009 USM_SeqLmpSetReq 3;
BA_ "Version" SG_ 2470763009 USM_SeqLmpSetReq "17.11.00";
BA_ "Description" SG_ 2470763009 USM_UnlckWlcmSetReq "This signal is used for a request to set the value of USM Menus. This signal requests to change status of Welcome System setting.





When this signal change, the message (CLU18) is sent 3 times.";
BA_ "GenSigSendType" SG_ 2470763009 USM_UnlckWlcmSetReq 4;
BA_ "UserSigValidity" SG_ 2470763009 USM_UnlckWlcmSetReq 3;
BA_ "Version" SG_ 2470763009 USM_UnlckWlcmSetReq "17.11.00";
BA_ "Description" SG_ 2470763009 USM_SmrtWlcmSetReq "This signal is used for a request to set the value of USM Menus. This signal requests to change status of Welcome System setting.





When this signal change, the message (CLU18) is sent 3 times.";
BA_ "GenSigSendType" SG_ 2470763009 USM_SmrtWlcmSetReq 4;
BA_ "UserSigValidity" SG_ 2470763009 USM_SmrtWlcmSetReq 3;
BA_ "Version" SG_ 2470763009 USM_SmrtWlcmSetReq "17.11.00";
BA_ "Description" SG_ 2470763009 USM_UipSetReq "Request to set Uip(Ultrasonic Intrusion Protection)

This signal is used for a request to set the value of USM Menus. 

When this signal change, the message is sent 3 times.";
BA_ "GenSigSendType" SG_ 2470763009 USM_UipSetReq 4;
BA_ "UserSigValidity" SG_ 2470763009 USM_UipSetReq 3;
BA_ "Version" SG_ 2470763009 USM_UipSetReq "18.11.07";
BA_ "Description" SG_ 2470763009 USM_DigitalKeyEnblSetReq "This signal is used for a request to set the value of USM Menus. This signal requests to set Digital Key On/Off.";
BA_ "GenSigSendType" SG_ 2470763009 USM_DigitalKeyEnblSetReq 4;
BA_ "UserSigValidity" SG_ 2470763009 USM_DigitalKeyEnblSetReq 3;
BA_ "Version" SG_ 2470763009 USM_DigitalKeyEnblSetReq "18.11.00";
BA_ "Description" SG_ 2470763009 USM_OwnerPhnRegSetReq "This signal is used for a request to set the value of USM Menus.

This signal requests to set Digital Key On/Off";
BA_ "GenSigSendType" SG_ 2470763009 USM_OwnerPhnRegSetReq 4;
BA_ "UserSigValidity" SG_ 2470763009 USM_OwnerPhnRegSetReq 3;
BA_ "Version" SG_ 2470763009 USM_OwnerPhnRegSetReq "18.11.00";
BA_ "Description" SG_ 2470763009 USM_NFCCard1RegSetReq "This signal is used for a request to set the value of USM Menus. This signal requests to go through the process for NFC Card 1 recoding.";
BA_ "GenSigSendType" SG_ 2470763009 USM_NFCCard1RegSetReq 4;
BA_ "UserSigValidity" SG_ 2470763009 USM_NFCCard1RegSetReq 3;
BA_ "Version" SG_ 2470763009 USM_NFCCard1RegSetReq "18.11.00";
BA_ "Description" SG_ 2470763009 USM_NFCCard2RegSetReq "This signal is used for arequest to set the value of usm menus.

This signal requests to go through the process NFC Card 2 recording";
BA_ "GenSigSendType" SG_ 2470763009 USM_NFCCard2RegSetReq 4;
BA_ "UserSigValidity" SG_ 2470763009 USM_NFCCard2RegSetReq 3;
BA_ "Version" SG_ 2470763009 USM_NFCCard2RegSetReq "18.11.00";
BA_ "Description" SG_ 2470763009 USM_ProcStpReq "This signal is used for a request to escape the IAU Authorizaton processing";
BA_ "GenSigSendType" SG_ 2470763009 USM_ProcStpReq 4;
BA_ "UserSigValidity" SG_ 2470763009 USM_ProcStpReq 3;
BA_ "Version" SG_ 2470763009 USM_ProcStpReq "18.11.00";
BA_ "Description" SG_ 2470763009 USM_PwrAutoOffTimeSetReq "This signal is used for a request to set the value of USM Menus. This signal requests to change status of Power auto off time setting.";
BA_ "GenSigSendType" SG_ 2470763009 USM_PwrAutoOffTimeSetReq 4;
BA_ "UserSigValidity" SG_ 2470763009 USM_PwrAutoOffTimeSetReq 3;
BA_ "Version" SG_ 2470763009 USM_PwrAutoOffTimeSetReq "18.12.02";
BA_ "Description" SG_ 2470763009 USM_RrStRemindSetReq_RestMode "This is a signal for Rear Seat remind USM 

Request to set  Restmod of Rear Seat remind";
BA_ "GenSigSendType" SG_ 2470763009 USM_RrStRemindSetReq_RestMode 4;
BA_ "UserSigValidity" SG_ 2470763009 USM_RrStRemindSetReq_RestMode 3;
BA_ "Version" SG_ 2470763009 USM_RrStRemindSetReq_RestMode "19.09.04";
BA_ "Description" SG_ 2470763009 USM_1stRrStRemindSetReq "USM Function for RearSeatReminder on/off SW for IBU only Type";
BA_ "GenSigSendType" SG_ 2470763009 USM_1stRrStRemindSetReq 4;
BA_ "UserSigValidity" SG_ 2470763009 USM_1stRrStRemindSetReq 3;
BA_ "Version" SG_ 2470763009 USM_1stRrStRemindSetReq "20.02.06";
BA_ "GenMsgSendType" BO_ 2231452929 0;
BA_ "GenMsgCycleTime" BO_ 2231452929 100;
BA_ "GenMsgCycleTimeFast" BO_ 2231452929 0;
BA_ "GenMsgNrOfRepetition" BO_ 2231452929 0;
BA_ "VFrameFormat" BO_ 2231452929 1;
BA_ "Description" SG_ 2231452929 DATC_Crc1Val "The data area for CRC calculation is based on the data length (DLC) of the message DB.

The CRC shall be calculated over the entire data block (excluding the CRC bytes) including the user data, alive counter and Data ID

 

- CRC Polynomial (0x1021) , Initial Value : 0xFFFF, XOR value : 0x0000, Data ID : Message ID + 0xF800 

- The initial value is for CRC calculation and the message should be sent with the calculated result value. 

- The mathematical expression to 16 bit CRC polynomial is given here. G(x) = x16 + x12 + x5 + 1";
BA_ "GenSigStartValue" SG_ 2231452929 DATC_Crc1Val 65535;
BA_ "UserSigValidity" SG_ 2231452929 DATC_Crc1Val 7;
BA_ "RoutingFactor" SG_ 2231452929 DATC_Crc1Val 5;
BA_ "Version" SG_ 2231452929 DATC_Crc1Val "18.11.08";
BA_ "Description" SG_ 2231452929 DATC_AlvCnt1Val "For the first transmission request for a data element the counter shall be initialized with 0 and shall be incremented by 1 for every subsequent send request. 

When the counter reaches the maximum value(0xFF), then it shall restart with 0 for the next send request";
BA_ "UserSigValidity" SG_ 2231452929 DATC_AlvCnt1Val 7;
BA_ "RoutingFactor" SG_ 2231452929 DATC_AlvCnt1Val 5;
BA_ "Version" SG_ 2231452929 DATC_AlvCnt1Val "18.11.08";
BA_ "Description" SG_ 2231452929 DATC_PtcRlySta "This signal indicates PTC relay operation condition of gasoline engine. This signal is used for EMS to decide engine RPM up.";
BA_ "UserSigValidity" SG_ 2231452929 DATC_PtcRlySta 7;
BA_ "RoutingFactor" SG_ 2231452929 DATC_PtcRlySta 5;
BA_ "Version" SG_ 2231452929 DATC_PtcRlySta "17.11.00";
BA_ "Description" SG_ 2231452929 DATC_ManufacturerTyp "This signal FATC_ID identifies FATC Maker.";
BA_ "UserSigValidity" SG_ 2231452929 DATC_ManufacturerTyp 3;
BA_ "RoutingFactor" SG_ 2231452929 DATC_ManufacturerTyp 5;
BA_ "Version" SG_ 2231452929 DATC_ManufacturerTyp "17.11.00";
BA_ "Description" SG_ 2231452929 DATC_DatcPwmSts "This signal indicates operating status of E-comp.";
BA_ "UserSigValidity" SG_ 2231452929 DATC_DatcPwmSts 3;
BA_ "RoutingFactor" SG_ 2231452929 DATC_DatcPwmSts 5;
BA_ "Version" SG_ 2231452929 DATC_DatcPwmSts "18.09.00";
BA_ "Description" SG_ 2231452929 DATC_AcnCompTyp "Heater Control(FATC/MTC) information generated by HVAC Compressor type.";
BA_ "UserSigValidity" SG_ 2231452929 DATC_AcnCompTyp 3;
BA_ "RoutingFactor" SG_ 2231452929 DATC_AcnCompTyp 5;
BA_ "Version" SG_ 2231452929 DATC_AcnCompTyp "17.11.00";
BA_ "Description" SG_ 2231452929 DATC_EewpRpmLvlReq "EEWP Target RPM level



00h : MAX A/C

01h : Low

02h : Mid

03h : High";
BA_ "UserSigValidity" SG_ 2231452929 DATC_EewpRpmLvlReq 3;
BA_ "RoutingFactor" SG_ 2231452929 DATC_EewpRpmLvlReq 5;
BA_ "Version" SG_ 2231452929 DATC_EewpRpmLvlReq "17.11.00";
BA_ "Description" SG_ 2231452929 DATC_Cooldown "This signal indicates complete of cooldown.";
BA_ "UserSigValidity" SG_ 2231452929 DATC_Cooldown 3;
BA_ "RoutingFactor" SG_ 2231452929 DATC_Cooldown 5;
BA_ "Version" SG_ 2231452929 DATC_Cooldown "18.09.00";
BA_ "Description" SG_ 2231452929 DATC_AcnReq "This signal indicates A/C request switch by FATC

This signal occurs when A/C switch(button) is selected either manually or automatically.

EMS decides the torque compensation value to avoid torque shortage while A/C on";
BA_ "UserSigValidity" SG_ 2231452929 DATC_AcnReq 7;
BA_ "RoutingFactor" SG_ 2231452929 DATC_AcnReq 5;
BA_ "Version" SG_ 2231452929 DATC_AcnReq "17.11.00";
BA_ "Description" SG_ 2231452929 DATC_BlwSta "This signal indicates HVAC blower motor operation condition.

The signal is used for EMS to decide PTC on or manage battery level.";
BA_ "UserSigValidity" SG_ 2231452929 DATC_BlwSta 7;
BA_ "RoutingFactor" SG_ 2231452929 DATC_BlwSta 5;
BA_ "Version" SG_ 2231452929 DATC_BlwSta "17.11.00";
BA_ "Description" SG_ 2231452929 DATC_BlwMaxSta "This signal indicates that FATC operates HVAC blower by maximum speed.";
BA_ "UserSigValidity" SG_ 2231452929 DATC_BlwMaxSta 7;
BA_ "RoutingFactor" SG_ 2231452929 DATC_BlwMaxSta 5;
BA_ "Version" SG_ 2231452929 DATC_BlwMaxSta "17.11.00";
BA_ "Description" SG_ 2231452929 DATC_EngStrtReq "FATC requests Engine Auto Start to EMS by this signal during idle stop.";
BA_ "UserSigValidity" SG_ 2231452929 DATC_EngStrtReq 3;
BA_ "RoutingFactor" SG_ 2231452929 DATC_EngStrtReq 5;
BA_ "Version" SG_ 2231452929 DATC_EngStrtReq "17.11.00";
BA_ "Description" SG_ 2231452929 DATC_IsgInhbtReq "FATC requests EMS that ISG is prohibited (ISG function is not operating) by this signal.

FATC send the disable signal in the condition, for example HVAC Blower is Max.";
BA_ "UserSigValidity" SG_ 2231452929 DATC_IsgInhbtReq 3;
BA_ "RoutingFactor" SG_ 2231452929 DATC_IsgInhbtReq 5;
BA_ "Version" SG_ 2231452929 DATC_IsgInhbtReq "17.11.00";
BA_ "Description" SG_ 2231452929 DATC_AcnCompOnReq "FATC requests A/C compressor clutch on or off to EMS by this signal

This signal is off to maintain a/c refrigerant flow and air flow smoothly and avoid abnormal a/c compressor torque rising even though A/C request switch on, if the surface temperature of evaporator is below the certain icing temperature.";
BA_ "UserSigValidity" SG_ 2231452929 DATC_AcnCompOnReq 3;
BA_ "RoutingFactor" SG_ 2231452929 DATC_AcnCompOnReq 5;
BA_ "Version" SG_ 2231452929 DATC_AcnCompOnReq "17.11.00";
BA_ "Description" SG_ 2231452929 DATC_SrvLmpReq "This signal indicates request of service Lamp";
BA_ "UserSigValidity" SG_ 2231452929 DATC_SrvLmpReq 7;
BA_ "RoutingFactor" SG_ 2231452929 DATC_SrvLmpReq 5;
BA_ "Version" SG_ 2231452929 DATC_SrvLmpReq "19.08.04";
BA_ "Description" SG_ 2231452929 DATC_EcvFltSta "This signal indicates ECV control fault.

The detailed fault state is in the error identifiers of CR_Fatc_TqAcnOut signal";
BA_ "UserSigValidity" SG_ 2231452929 DATC_EcvFltSta 3;
BA_ "RoutingFactor" SG_ 2231452929 DATC_EcvFltSta 5;
BA_ "Version" SG_ 2231452929 DATC_EcvFltSta "17.11.00";
BA_ "Description" SG_ 2231452929 DATC_CalcAcnCompTqVal "This signal indicates the torque output of A/C compressor calculated by FATC.

EMS decides the torque compensation value or A/C compressor clutch disengagement (off) by receiving of this signal.";
BA_ "UserSigValidity" SG_ 2231452929 DATC_CalcAcnCompTqVal 3;
BA_ "RoutingFactor" SG_ 2231452929 DATC_CalcAcnCompTqVal 5;
BA_ "Version" SG_ 2231452929 DATC_CalcAcnCompTqVal "17.11.00";
BA_ "GenMsgSendType" BO_ 2231452930 0;
BA_ "GenMsgCycleTime" BO_ 2231452930 100;
BA_ "GenMsgCycleTimeFast" BO_ 2231452930 0;
BA_ "GenMsgNrOfRepetition" BO_ 2231452930 0;
BA_ "VFrameFormat" BO_ 2231452930 1;
BA_ "UserSigValidity" SG_ 2231452930 DATC_AcnECompOpSta 7;
BA_ "RoutingFactor" SG_ 2231452930 DATC_AcnECompOpSta 5;
BA_ "Version" SG_ 2231452930 DATC_AcnECompOpSta "17.11.00";
BA_ "UserSigValidity" SG_ 2231452930 DATC_HVCompIntlkSta 7;
BA_ "RoutingFactor" SG_ 2231452930 DATC_HVCompIntlkSta 5;
BA_ "Version" SG_ 2231452930 DATC_HVCompIntlkSta "17.11.00";
BA_ "Description" SG_ 2231452930 DATC_HVIntDischrgLkReq "This signal indicates forced discharge request when HV PTC Interlock or E-Compressor Interlock is open.";
BA_ "UserSigValidity" SG_ 2231452930 DATC_HVIntDischrgLkReq 7;
BA_ "RoutingFactor" SG_ 2231452930 DATC_HVIntDischrgLkReq 5;
BA_ "Version" SG_ 2231452930 DATC_HVIntDischrgLkReq "17.11.00";
BA_ "Description" SG_ 2231452930 DATC_AcnECompMaxReqPwrVal "0....20440[W] = 00H...3FEH (PH)= 20 * (HEX)[W]";
BA_ "UserSigValidity" SG_ 2231452930 DATC_AcnECompMaxReqPwrVal 7;
BA_ "RoutingFactor" SG_ 2231452930 DATC_AcnECompMaxReqPwrVal 5;
BA_ "Version" SG_ 2231452930 DATC_AcnECompMaxReqPwrVal "19.08.04";
BA_ "UserSigValidity" SG_ 2231452930 DATC_AcnCompFltSta 7;
BA_ "RoutingFactor" SG_ 2231452930 DATC_AcnCompFltSta 5;
BA_ "Version" SG_ 2231452930 DATC_AcnCompFltSta "17.11.00";
BA_ "Description" SG_ 2231452930 DATC_AcnECompCnsmptPwrVal "0¡¦20440[W] = 00H...3FEH (PH)= 20 * (HEX)[W]";
BA_ "UserSigValidity" SG_ 2231452930 DATC_AcnECompCnsmptPwrVal 7;
BA_ "RoutingFactor" SG_ 2231452930 DATC_AcnECompCnsmptPwrVal 5;
BA_ "Version" SG_ 2231452930 DATC_AcnECompCnsmptPwrVal "19.08.04";
BA_ "UserSigValidity" SG_ 2231452930 DATC_MainRlyOffReq 3;
BA_ "RoutingFactor" SG_ 2231452930 DATC_MainRlyOffReq 5;
BA_ "Version" SG_ 2231452930 DATC_MainRlyOffReq "17.11.00";
BA_ "Description" SG_ 2231452930 DATC_MixDfgSelSta "DATC will send this request signal to BMS when controlled in Mix/Def mode.";
BA_ "UserSigValidity" SG_ 2231452930 DATC_MixDfgSelSta 3;
BA_ "RoutingFactor" SG_ 2231452930 DATC_MixDfgSelSta 5;
BA_ "Version" SG_ 2231452930 DATC_MixDfgSelSta "17.11.00";
BA_ "Description" SG_ 2231452930 DATC_BattChlrVlvSta "Battery chiller valve status";
BA_ "UserSigValidity" SG_ 2231452930 DATC_BattChlrVlvSta 3;
BA_ "RoutingFactor" SG_ 2231452930 DATC_BattChlrVlvSta 5;
BA_ "Version" SG_ 2231452930 DATC_BattChlrVlvSta "19.07.02";
BA_ "UserSigValidity" SG_ 2231452930 DATC_WaterPmpOnReq 3;
BA_ "RoutingFactor" SG_ 2231452930 DATC_WaterPmpOnReq 5;
BA_ "Version" SG_ 2231452930 DATC_WaterPmpOnReq "17.11.00";
BA_ "Description" SG_ 2231452930 DATC_AcnECompSpdVal "0 ¡¦65534 [rpm] = 0000H ¡¦ FFFEH, (PH) = 1*(HEX) [rpm]";
BA_ "UserSigValidity" SG_ 2231452930 DATC_AcnECompSpdVal 7;
BA_ "RoutingFactor" SG_ 2231452930 DATC_AcnECompSpdVal 5;
BA_ "Version" SG_ 2231452930 DATC_AcnECompSpdVal "17.11.00";
BA_ "Description" SG_ 2231452930 DATC_AcnCompSlpModCodVal "(PH) = 1 * (HEX) [-]";
BA_ "UserSigValidity" SG_ 2231452930 DATC_AcnCompSlpModCodVal 7;
BA_ "RoutingFactor" SG_ 2231452930 DATC_AcnCompSlpModCodVal 5;
BA_ "Version" SG_ 2231452930 DATC_AcnCompSlpModCodVal "17.11.00";
BA_ "UserSigValidity" SG_ 2231452930 DATC_RrDfgOpSta 3;
BA_ "RoutingFactor" SG_ 2231452930 DATC_RrDfgOpSta 5;
BA_ "Version" SG_ 2231452930 DATC_RrDfgOpSta "17.11.00";
BA_ "UserSigValidity" SG_ 2231452930 DATC_AcnECompCANFltSta 3;
BA_ "RoutingFactor" SG_ 2231452930 DATC_AcnECompCANFltSta 5;
BA_ "Version" SG_ 2231452930 DATC_AcnECompCANFltSta "17.11.00";
BA_ "GenMsgSendType" BO_ 2231452931 0;
BA_ "GenMsgCycleTime" BO_ 2231452931 100;
BA_ "GenMsgCycleTimeFast" BO_ 2231452931 0;
BA_ "GenMsgNrOfRepetition" BO_ 2231452931 0;
BA_ "VFrameFormat" BO_ 2231452931 1;
BA_ "Description" SG_ 2231452931 DATC_AcnCompWaitCodVal "(PH) = 1 * (HEX) [-]";
BA_ "UserSigValidity" SG_ 2231452931 DATC_AcnCompWaitCodVal 7;
BA_ "RoutingFactor" SG_ 2231452931 DATC_AcnCompWaitCodVal 5;
BA_ "Version" SG_ 2231452931 DATC_AcnCompWaitCodVal "17.11.00";
BA_ "Description" SG_ 2231452931 DATC_PeEwpRPMReq "This signal indicates Cooling For High V Component (for A/C or Heatpump)

ÀüÀå¿ë ³Ã°¢¼ö¿ë, ÀüÀåÆó¿­À» ÀÌ¿ëÇÑ ¸®È÷ÆÃ¿ë";
BA_ "UserSigValidity" SG_ 2231452931 DATC_PeEwpRPMReq 3;
BA_ "RoutingFactor" SG_ 2231452931 DATC_PeEwpRPMReq 5;
BA_ "Version" SG_ 2231452931 DATC_PeEwpRPMReq "20.05.02";
BA_ "Description" SG_ 2231452931 DATC_AEwpSpdRpmReq "This signal indicates Request EWP speed to recover heat in HVAC System.(ENG COOLING ¿ë È¸·Î / È÷ÅÍÄÚ¾î ¿¬°ü)";
BA_ "UserSigValidity" SG_ 2231452931 DATC_AEwpSpdRpmReq 7;
BA_ "RoutingFactor" SG_ 2231452931 DATC_AEwpSpdRpmReq 5;
BA_ "Version" SG_ 2231452931 DATC_AEwpSpdRpmReq "17.11.00";
BA_ "Description" SG_ 2231452931 DATC_RadFanReq_Duty "This signal indicates Request cooling fan speed to cool HVAC System (Duty)

(0xFE value is only used to wake up EMS )";
BA_ "UserSigValidity" SG_ 2231452931 DATC_RadFanReq_Duty 5;
BA_ "RoutingFactor" SG_ 2231452931 DATC_RadFanReq_Duty 5;
BA_ "Version" SG_ 2231452931 DATC_RadFanReq_Duty "20.02.05";
BA_ "Description" SG_ 2231452931 DATC_OutTempSnsrVal "Actual temperature of Ambient Sensor via an A/D converter; converted into degrees

centigrade (¡É).

This is raw data of ambient sensor; just transferred from Ambient Sensor Voltage.";
BA_ "UserSigValidity" SG_ 2231452931 DATC_OutTempSnsrVal 7;
BA_REL_ "GenSigTimeoutTime" BU_SG_REL_ RCM SG_ 2231452931 DATC_OutTempSnsrVal 1500;
BA_ "RoutingFactor" SG_ 2231452931 DATC_OutTempSnsrVal 5;
BA_ "Version" SG_ 2231452931 DATC_OutTempSnsrVal "17.11.00";
BA_ "Description" SG_ 2231452931 DATC_ActvEco "This signal indicates the operating condition (ON or OFF) of Active ECO Button.";
BA_ "UserSigValidity" SG_ 2231452931 DATC_ActvEco 7;
BA_ "RoutingFactor" SG_ 2231452931 DATC_ActvEco 5;
BA_ "Version" SG_ 2231452931 DATC_ActvEco "17.11.00";
BA_ "Description" SG_ 2231452931 DATC_AUTOActv "As soon as FATC receive activation message from TMU, 

For 5 Seconds, FATC Send The massage ¡° Automatic control is Active(01H) ¡° and 

control 23¡É Auto.

After 5 seconds FATC send the initial value(00H) massage";
BA_ "UserSigValidity" SG_ 2231452931 DATC_AUTOActv 7;
BA_ "RoutingFactor" SG_ 2231452931 DATC_AUTOActv 5;
BA_ "Version" SG_ 2231452931 DATC_AUTOActv "17.11.00";
BA_ "Description" SG_ 2231452931 DATC_DfgSw "This signal indicates whether FRONT DEF switch is selected or not.";
BA_ "UserSigValidity" SG_ 2231452931 DATC_DfgSw 7;
BA_ "RoutingFactor" SG_ 2231452931 DATC_DfgSw 5;
BA_ "Version" SG_ 2231452931 DATC_DfgSw "17.11.00";
BA_ "Description" SG_ 2231452931 DATC_BattChlrVlv_FltCode "Battery Chiller Filt Code";
BA_ "UserSigValidity" SG_ 2231452931 DATC_BattChlrVlv_FltCode 3;
BA_ "RoutingFactor" SG_ 2231452931 DATC_BattChlrVlv_FltCode 5;
BA_ "Version" SG_ 2231452931 DATC_BattChlrVlv_FltCode "18.09.00";
BA_ "Description" SG_ 2231452931 DATC_BattEvapVlvSta "BATTERY COOL V/V (EVAP) STATUS";
BA_ "UserSigValidity" SG_ 2231452931 DATC_BattEvapVlvSta 5;
BA_ "RoutingFactor" SG_ 2231452931 DATC_BattEvapVlvSta 5;
BA_ "Version" SG_ 2231452931 DATC_BattEvapVlvSta "18.09.00";
BA_ "Description" SG_ 2231452931 DATC_BattEvapVlv_FltCode "BATTERY COOL V/V (EVAP) FltCode";
BA_ "UserSigValidity" SG_ 2231452931 DATC_BattEvapVlv_FltCode 5;
BA_ "RoutingFactor" SG_ 2231452931 DATC_BattEvapVlv_FltCode 5;
BA_ "Version" SG_ 2231452931 DATC_BattEvapVlv_FltCode "18.09.00";
BA_ "Description" SG_ 2231452931 DATC_Wrmup "This signal indicates complete of warmup";
BA_ "UserSigValidity" SG_ 2231452931 DATC_Wrmup 5;
BA_ "RoutingFactor" SG_ 2231452931 DATC_Wrmup 5;
BA_ "Version" SG_ 2231452931 DATC_Wrmup "18.09.00";
BA_ "Description" SG_ 2231452931 DATC_SSC_EngStrtReq "Engine start request in SSC state";
BA_ "UserSigValidity" SG_ 2231452931 DATC_SSC_EngStrtReq 3;
BA_ "RoutingFactor" SG_ 2231452931 DATC_SSC_EngStrtReq 5;
BA_ "Version" SG_ 2231452931 DATC_SSC_EngStrtReq "19.04.00";
BA_ "Description" SG_ 2231452931 DATC_AcnCompSta "1 : Initialize Mode, 2: Standby Mode, 4 : Wait Mode, 8 : Sleep Mode, 10H: Operating Mode";
BA_ "UserSigValidity" SG_ 2231452931 DATC_AcnCompSta 3;
BA_ "RoutingFactor" SG_ 2231452931 DATC_AcnCompSta 5;
BA_ "Version" SG_ 2231452931 DATC_AcnCompSta "17.11.00";
BA_ "GenMsgSendType" BO_ 2231452932 0;
BA_ "GenMsgCycleTime" BO_ 2231452932 100;
BA_ "GenMsgCycleTimeFast" BO_ 2231452932 0;
BA_ "GenMsgNrOfRepetition" BO_ 2231452932 0;
BA_ "VFrameFormat" BO_ 2231452932 1;
BA_ "Description" SG_ 2231452932 DATC_SSC_InhbtReq "Request to EMS not to enter SSC";
BA_ "UserSigValidity" SG_ 2231452932 DATC_SSC_InhbtReq 3;
BA_ "RoutingFactor" SG_ 2231452932 DATC_SSC_InhbtReq 5;
BA_ "Version" SG_ 2231452932 DATC_SSC_InhbtReq "19.04.00";
BA_ "Description" SG_ 2231452932 DATC_EngIdlRpmUpReq "This signal is information of A/C Comp_Load by FATC.";
BA_ "UserSigValidity" SG_ 2231452932 DATC_EngIdlRpmUpReq 3;
BA_ "RoutingFactor" SG_ 2231452932 DATC_EngIdlRpmUpReq 5;
BA_ "Version" SG_ 2231452932 DATC_EngIdlRpmUpReq "20.07.12";
BA_ "Description" SG_ 2231452932 DATC_MaxBlwVolt "Max blower voltage that only B+ status send to LDC";
BA_ "UserSigValidity" SG_ 2231452932 DATC_MaxBlwVolt 7;
BA_ "RoutingFactor" SG_ 2231452932 DATC_MaxBlwVolt 5;
BA_ "Version" SG_ 2231452932 DATC_MaxBlwVolt "20.05.01";
BA_ "Description" SG_ 2231452932 DATC_HVACPmpOpSta "HVAC Pump Operation Status";
BA_ "UserSigValidity" SG_ 2231452932 DATC_HVACPmpOpSta 3;
BA_ "RoutingFactor" SG_ 2231452932 DATC_HVACPmpOpSta 5;
BA_ "Version" SG_ 2231452932 DATC_HVACPmpOpSta "18.09.00";
BA_ "Description" SG_ 2231452932 DATC_MildCooldown "Mild Cooldown State";
BA_ "UserSigValidity" SG_ 2231452932 DATC_MildCooldown 7;
BA_ "RoutingFactor" SG_ 2231452932 DATC_MildCooldown 5;
BA_ "Version" SG_ 2231452932 DATC_MildCooldown "18.10.06";
BA_ "Description" SG_ 2231452932 DATC_MildWrmup "Mild Warmup State";
BA_ "UserSigValidity" SG_ 2231452932 DATC_MildWrmup 5;
BA_ "RoutingFactor" SG_ 2231452932 DATC_MildWrmup 5;
BA_ "Version" SG_ 2231452932 DATC_MildWrmup "18.09.00";
BA_ "Description" SG_ 2231452932 DATC_BlwrLvl "This signal indicates step of Front blower operation .";
BA_ "UserSigValidity" SG_ 2231452932 DATC_BlwrLvl 7;
BA_ "RoutingFactor" SG_ 2231452932 DATC_BlwrLvl 5;
BA_ "Version" SG_ 2231452932 DATC_BlwrLvl "18.10.06";
BA_ "Description" SG_ 2231452932 DATC_AAFOpenReq "Open Reqest Active Air Flap(AAF) before Compressor max rpm";
BA_ "UserSigValidity" SG_ 2231452932 DATC_AAFOpenReq 7;
BA_ "RoutingFactor" SG_ 2231452932 DATC_AAFOpenReq 5;
BA_ "Version" SG_ 2231452932 DATC_AAFOpenReq "19.06.03";
BA_ "Description" SG_ 2231452932 DATC_BattEwpOpReq "This signal requests the operation of BATT EWP for heat recovery technique.";
BA_ "UserSigValidity" SG_ 2231452932 DATC_BattEwpOpReq 5;
BA_ "RoutingFactor" SG_ 2231452932 DATC_BattEwpOpReq 5;
BA_ "Version" SG_ 2231452932 DATC_BattEwpOpReq "18.12.03";
BA_ "GenMsgCycleTime" BO_ 649 0;
BA_ "Description" SG_ 649 DLBCU_SmartCtrl_1h "½º¸¶Æ® ÀÚ¼¼Á¦¾î DLBCU ¿¬µ¿ Á¶Àý¿¡ µû¸¥ °³¼±ÇöÈ² AVN Ç¥½Ã¹®±¸_1½Ã°£";
BA_ "GenSigSendType" SG_ 649 DLBCU_SmartCtrl_1h 4;
BA_ "UserSigValidity" SG_ 649 DLBCU_SmartCtrl_1h 1;
BA_REL_ "GenSigTimeoutTime" BU_SG_REL_ CGW_CCU SG_ 649 DLBCU_SmartCtrl_1h 0;
BA_ "Version" SG_ 649 DLBCU_SmartCtrl_1h "19.10.02";
BA_ "Description" SG_ 649 DLBCU_SmartCtrl_2h "½º¸¶Æ® ÀÚ¼¼Á¦¾î DLBCU ¿¬µ¿ Á¶Àý¿¡ µû¸¥ °³¼±ÇöÈ² AVN Ç¥½Ã ¹®±¸_2½Ã°£";
BA_ "GenSigSendType" SG_ 649 DLBCU_SmartCtrl_2h 4;
BA_ "UserSigValidity" SG_ 649 DLBCU_SmartCtrl_2h 1;
BA_REL_ "GenSigTimeoutTime" BU_SG_REL_ CGW_CCU SG_ 649 DLBCU_SmartCtrl_2h 0;
BA_ "Version" SG_ 649 DLBCU_SmartCtrl_2h "19.10.02";
BA_ "Description" SG_ 649 DLBCU_SmartCtrl_Status "½º¸¶Æ® ÀÚ¼¼Á¦¾î 2´Ü°è DLBCU ¿¬µ¿ Á¶Àý µ¿ÀÛ ½ÃÀÛ / Á¾·á / Áß´Ü AVN ÆË¾÷";
BA_ "GenSigSendType" SG_ 649 DLBCU_SmartCtrl_Status 4;
BA_ "UserSigValidity" SG_ 649 DLBCU_SmartCtrl_Status 1;
BA_REL_ "GenSigTimeoutTime" BU_SG_REL_ CGW_CCU SG_ 649 DLBCU_SmartCtrl_Status 0;
BA_ "Version" SG_ 649 DLBCU_SmartCtrl_Status "19.10.03";
BA_ "GenMsgSendType" BO_ 1159 0;
BA_ "GenMsgStartDelayTime" BO_ 1159 90;
BA_ "GenSigSendType" SG_ 1159 C_AstRclBwdSw_HU 4;
BA_ "UserSigValidity" SG_ 1159 C_AstRclBwdSw_HU 0;
BA_REL_ "GenSigTimeoutTime" BU_SG_REL_ APSU SG_ 1159 C_AstRclBwdSw_HU 1500;
BA_ "Version" SG_ 1159 C_AstRclBwdSw_HU "19.11.05";
BA_ "GenSigSendType" SG_ 1159 C_AstHeightUpSw_HU 4;
BA_ "UserSigValidity" SG_ 1159 C_AstHeightUpSw_HU 0;
BA_REL_ "GenSigTimeoutTime" BU_SG_REL_ APSU SG_ 1159 C_AstHeightUpSw_HU 1500;
BA_ "Version" SG_ 1159 C_AstHeightUpSw_HU "19.11.05";
BA_ "GenSigSendType" SG_ 1159 C_AstTiltDnSw_HU 4;
BA_ "UserSigValidity" SG_ 1159 C_AstTiltDnSw_HU 0;
BA_REL_ "GenSigTimeoutTime" BU_SG_REL_ APSU SG_ 1159 C_AstTiltDnSw_HU 1500;
BA_ "Version" SG_ 1159 C_AstTiltDnSw_HU "19.11.05";
BA_ "GenSigSendType" SG_ 1159 C_AstTiltUpSw_HU 4;
BA_ "UserSigValidity" SG_ 1159 C_AstTiltUpSw_HU 0;
BA_REL_ "GenSigTimeoutTime" BU_SG_REL_ APSU SG_ 1159 C_AstTiltUpSw_HU 1500;
BA_ "Version" SG_ 1159 C_AstTiltUpSw_HU "19.11.05";
BA_ "GenSigSendType" SG_ 1159 C_AstLumbarDefSw_HU 4;
BA_ "UserSigValidity" SG_ 1159 C_AstLumbarDefSw_HU 0;
BA_REL_ "GenSigTimeoutTime" BU_SG_REL_ ASAU SG_ 1159 C_AstLumbarDefSw_HU 1500;
BA_REL_ "GenSigTimeoutTime" BU_SG_REL_ ALBCU SG_ 1159 C_AstLumbarDefSw_HU 1500;
BA_ "Version" SG_ 1159 C_AstLumbarDefSw_HU "19.11.05";
BA_ "GenSigSendType" SG_ 1159 C_AstLumbarLowSw_HU 4;
BA_ "UserSigValidity" SG_ 1159 C_AstLumbarLowSw_HU 0;
BA_REL_ "GenSigTimeoutTime" BU_SG_REL_ ASAU SG_ 1159 C_AstLumbarLowSw_HU 1500;
BA_REL_ "GenSigTimeoutTime" BU_SG_REL_ ALBCU SG_ 1159 C_AstLumbarLowSw_HU 1500;
BA_ "Version" SG_ 1159 C_AstLumbarLowSw_HU "19.11.05";
BA_ "GenSigSendType" SG_ 1159 C_AstRclFwdSw_HU 4;
BA_ "UserSigValidity" SG_ 1159 C_AstRclFwdSw_HU 0;
BA_REL_ "GenSigTimeoutTime" BU_SG_REL_ APSU SG_ 1159 C_AstRclFwdSw_HU 1500;
BA_ "Version" SG_ 1159 C_AstRclFwdSw_HU "19.11.05";
BA_ "GenSigSendType" SG_ 1159 C_AstLumbarMidSw_HU 4;
BA_ "UserSigValidity" SG_ 1159 C_AstLumbarMidSw_HU 0;
BA_REL_ "GenSigTimeoutTime" BU_SG_REL_ ASAU SG_ 1159 C_AstLumbarMidSw_HU 1500;
BA_REL_ "GenSigTimeoutTime" BU_SG_REL_ ALBCU SG_ 1159 C_AstLumbarMidSw_HU 1500;
BA_ "Version" SG_ 1159 C_AstLumbarMidSw_HU "19.11.05";
BA_ "GenSigSendType" SG_ 1159 C_AstLumbarUpSw_HU 4;
BA_ "UserSigValidity" SG_ 1159 C_AstLumbarUpSw_HU 0;
BA_REL_ "GenSigTimeoutTime" BU_SG_REL_ ASAU SG_ 1159 C_AstLumbarUpSw_HU 1500;
BA_REL_ "GenSigTimeoutTime" BU_SG_REL_ ALBCU SG_ 1159 C_AstLumbarUpSw_HU 1500;
BA_ "Version" SG_ 1159 C_AstLumbarUpSw_HU "19.11.05";
BA_ "GenSigSendType" SG_ 1159 C_RRSlideFwdSw_HU 4;
BA_ "UserSigValidity" SG_ 1159 C_RRSlideFwdSw_HU 0;
BA_REL_ "GenSigTimeoutTime" BU_SG_REL_ APSU SG_ 1159 C_RRSlideFwdSw_HU 1500;
BA_REL_ "GenSigTimeoutTime" BU_SG_REL_ RRPSU SG_ 1159 C_RRSlideFwdSw_HU 1500;
BA_REL_ "GenSigTimeoutTime" BU_SG_REL_ RLPSU SG_ 1159 C_RRSlideFwdSw_HU 1500;
BA_ "Version" SG_ 1159 C_RRSlideFwdSw_HU "19.11.05";
BA_ "GenSigSendType" SG_ 1159 C_RRSlideBwdSw_HU 4;
BA_ "UserSigValidity" SG_ 1159 C_RRSlideBwdSw_HU 0;
BA_REL_ "GenSigTimeoutTime" BU_SG_REL_ APSU SG_ 1159 C_RRSlideBwdSw_HU 1500;
BA_REL_ "GenSigTimeoutTime" BU_SG_REL_ RRPSU SG_ 1159 C_RRSlideBwdSw_HU 1500;
BA_REL_ "GenSigTimeoutTime" BU_SG_REL_ RLPSU SG_ 1159 C_RRSlideBwdSw_HU 1500;
BA_ "Version" SG_ 1159 C_RRSlideBwdSw_HU "19.11.05";
BA_ "GenSigSendType" SG_ 1159 C_RLSlideFwdSw_HU 4;
BA_ "UserSigValidity" SG_ 1159 C_RLSlideFwdSw_HU 0;
BA_REL_ "GenSigTimeoutTime" BU_SG_REL_ APSU SG_ 1159 C_RLSlideFwdSw_HU 1500;
BA_REL_ "GenSigTimeoutTime" BU_SG_REL_ RRPSU SG_ 1159 C_RLSlideFwdSw_HU 1500;
BA_REL_ "GenSigTimeoutTime" BU_SG_REL_ RLPSU SG_ 1159 C_RLSlideFwdSw_HU 1500;
BA_ "Version" SG_ 1159 C_RLSlideFwdSw_HU "19.11.05";
BA_ "GenSigSendType" SG_ 1159 C_RLSlideBwdSw_HU 4;
BA_ "UserSigValidity" SG_ 1159 C_RLSlideBwdSw_HU 0;
BA_REL_ "GenSigTimeoutTime" BU_SG_REL_ APSU SG_ 1159 C_RLSlideBwdSw_HU 1500;
BA_REL_ "GenSigTimeoutTime" BU_SG_REL_ RRPSU SG_ 1159 C_RLSlideBwdSw_HU 1500;
BA_REL_ "GenSigTimeoutTime" BU_SG_REL_ RLPSU SG_ 1159 C_RLSlideBwdSw_HU 1500;
BA_ "Version" SG_ 1159 C_RLSlideBwdSw_HU "19.11.05";
BA_ "GenSigSendType" SG_ 1159 C_AstSlideBwdSw_HU 4;
BA_ "UserSigValidity" SG_ 1159 C_AstSlideBwdSw_HU 0;
BA_REL_ "GenSigTimeoutTime" BU_SG_REL_ APSU SG_ 1159 C_AstSlideBwdSw_HU 1500;
BA_ "Version" SG_ 1159 C_AstSlideBwdSw_HU "19.11.05";
BA_ "GenSigSendType" SG_ 1159 C_AstSlideFwdSw_HU 4;
BA_ "UserSigValidity" SG_ 1159 C_AstSlideFwdSw_HU 0;
BA_REL_ "GenSigTimeoutTime" BU_SG_REL_ APSU SG_ 1159 C_AstSlideFwdSw_HU 1500;
BA_ "Version" SG_ 1159 C_AstSlideFwdSw_HU "19.11.05";
BA_ "GenSigSendType" SG_ 1159 C_AstHeightDnSw_HU 4;
BA_ "UserSigValidity" SG_ 1159 C_AstHeightDnSw_HU 0;
BA_REL_ "GenSigTimeoutTime" BU_SG_REL_ APSU SG_ 1159 C_AstHeightDnSw_HU 1500;
BA_ "Version" SG_ 1159 C_AstHeightDnSw_HU "19.11.05";
BA_ "GenMsgSendType" BO_ 197 0;
BA_ "GenSigSendType" SG_ 197 C_DrvRclBwdSw_HU 4;
BA_ "UserSigValidity" SG_ 197 C_DrvRclBwdSw_HU 0;
BA_REL_ "GenSigTimeoutTime" BU_SG_REL_ DPSU SG_ 197 C_DrvRclBwdSw_HU 1500;
BA_ "RoutingFactor" SG_ 197 C_DrvRclBwdSw_HU 0;
BA_ "Version" SG_ 197 C_DrvRclBwdSw_HU "20.01.02";
BA_ "GenSigSendType" SG_ 197 C_DrvSlideFwdSw_HU 4;
BA_ "UserSigValidity" SG_ 197 C_DrvSlideFwdSw_HU 0;
BA_REL_ "GenSigTimeoutTime" BU_SG_REL_ DPSU SG_ 197 C_DrvSlideFwdSw_HU 1500;
BA_ "RoutingFactor" SG_ 197 C_DrvSlideFwdSw_HU 0;
BA_ "Version" SG_ 197 C_DrvSlideFwdSw_HU "20.01.02";
BA_ "GenSigSendType" SG_ 197 C_RLLegSupFwdSw_HU 4;
BA_ "UserSigValidity" SG_ 197 C_RLLegSupFwdSw_HU 0;
BA_REL_ "GenSigTimeoutTime" BU_SG_REL_ APSU SG_ 197 C_RLLegSupFwdSw_HU 1500;
BA_REL_ "GenSigTimeoutTime" BU_SG_REL_ RRPSU SG_ 197 C_RLLegSupFwdSw_HU 1500;
BA_REL_ "GenSigTimeoutTime" BU_SG_REL_ RLPSU SG_ 197 C_RLLegSupFwdSw_HU 1500;
BA_ "RoutingFactor" SG_ 197 C_RLLegSupFwdSw_HU 0;
BA_ "Version" SG_ 197 C_RLLegSupFwdSw_HU "20.05.03";
BA_ "GenSigSendType" SG_ 197 C_RLLegSupBwdSw_HU 4;
BA_ "UserSigValidity" SG_ 197 C_RLLegSupBwdSw_HU 0;
BA_REL_ "GenSigTimeoutTime" BU_SG_REL_ APSU SG_ 197 C_RLLegSupBwdSw_HU 1500;
BA_REL_ "GenSigTimeoutTime" BU_SG_REL_ RRPSU SG_ 197 C_RLLegSupBwdSw_HU 1500;
BA_REL_ "GenSigTimeoutTime" BU_SG_REL_ RLPSU SG_ 197 C_RLLegSupBwdSw_HU 1500;
BA_ "RoutingFactor" SG_ 197 C_RLLegSupBwdSw_HU 0;
BA_ "Version" SG_ 197 C_RLLegSupBwdSw_HU "20.05.03";
BA_ "GenSigSendType" SG_ 197 C_DrvSlideBwdSw_HU 4;
BA_ "UserSigValidity" SG_ 197 C_DrvSlideBwdSw_HU 0;
BA_REL_ "GenSigTimeoutTime" BU_SG_REL_ DPSU SG_ 197 C_DrvSlideBwdSw_HU 1500;
BA_ "RoutingFactor" SG_ 197 C_DrvSlideBwdSw_HU 0;
BA_ "Version" SG_ 197 C_DrvSlideBwdSw_HU "20.01.02";
BA_ "GenSigSendType" SG_ 197 C_RLLegSupUpSw_HU 4;
BA_ "UserSigValidity" SG_ 197 C_RLLegSupUpSw_HU 0;
BA_REL_ "GenSigTimeoutTime" BU_SG_REL_ APSU SG_ 197 C_RLLegSupUpSw_HU 1500;
BA_REL_ "GenSigTimeoutTime" BU_SG_REL_ RRPSU SG_ 197 C_RLLegSupUpSw_HU 1500;
BA_REL_ "GenSigTimeoutTime" BU_SG_REL_ RLPSU SG_ 197 C_RLLegSupUpSw_HU 1500;
BA_ "RoutingFactor" SG_ 197 C_RLLegSupUpSw_HU 0;
BA_ "Version" SG_ 197 C_RLLegSupUpSw_HU "20.05.03";
BA_ "GenSigSendType" SG_ 197 C_RLLegSupDnSw_HU 4;
BA_ "UserSigValidity" SG_ 197 C_RLLegSupDnSw_HU 0;
BA_REL_ "GenSigTimeoutTime" BU_SG_REL_ APSU SG_ 197 C_RLLegSupDnSw_HU 1500;
BA_REL_ "GenSigTimeoutTime" BU_SG_REL_ RRPSU SG_ 197 C_RLLegSupDnSw_HU 1500;
BA_REL_ "GenSigTimeoutTime" BU_SG_REL_ RLPSU SG_ 197 C_RLLegSupDnSw_HU 1500;
BA_ "RoutingFactor" SG_ 197 C_RLLegSupDnSw_HU 0;
BA_ "Version" SG_ 197 C_RLLegSupDnSw_HU "20.05.03";
BA_ "GenSigSendType" SG_ 197 C_DrvRclFwdSw_HU 4;
BA_ "UserSigValidity" SG_ 197 C_DrvRclFwdSw_HU 0;
BA_REL_ "GenSigTimeoutTime" BU_SG_REL_ DPSU SG_ 197 C_DrvRclFwdSw_HU 1500;
BA_ "RoutingFactor" SG_ 197 C_DrvRclFwdSw_HU 0;
BA_ "Version" SG_ 197 C_DrvRclFwdSw_HU "20.01.02";
BA_ "GenMsgCycleTime" BO_ 172 0;
BA_ "Description" SG_ 172 BLTN_CAM_FR_VerPos_NvalueSet "Front Camera Vertical position setting value.";
BA_ "GenSigSendType" SG_ 172 BLTN_CAM_FR_VerPos_NvalueSet 4;
BA_ "UserSigValidity" SG_ 172 BLTN_CAM_FR_VerPos_NvalueSet 0;
BA_REL_ "GenSigTimeoutTime" BU_SG_REL_ BLTN_CAM SG_ 172 BLTN_CAM_FR_VerPos_NvalueSet 0;
BA_ "Version" SG_ 172 BLTN_CAM_FR_VerPos_NvalueSet "21.05.02";
BA_ "Description" SG_ 172 BLTN_CAM_AppNoti_PEV_NvalueSet "Parked Event notification to Connectivity Phone App. On/Off";
BA_ "GenSigSendType" SG_ 172 BLTN_CAM_AppNoti_PEV_NvalueSet 4;
BA_ "UserSigValidity" SG_ 172 BLTN_CAM_AppNoti_PEV_NvalueSet 0;
BA_REL_ "GenSigTimeoutTime" BU_SG_REL_ BLTN_CAM SG_ 172 BLTN_CAM_AppNoti_PEV_NvalueSet 0;
BA_ "Version" SG_ 172 BLTN_CAM_AppNoti_PEV_NvalueSet "21.05.02";
BA_ "Description" SG_ 172 BLTN_CAM_WiFi_AutoOn_NvalueSet "Wifi On/Off User setting";
BA_ "GenSigSendType" SG_ 172 BLTN_CAM_WiFi_AutoOn_NvalueSet 4;
BA_ "UserSigValidity" SG_ 172 BLTN_CAM_WiFi_AutoOn_NvalueSet 0;
BA_REL_ "GenSigTimeoutTime" BU_SG_REL_ BLTN_CAM SG_ 172 BLTN_CAM_WiFi_AutoOn_NvalueSet 0;
BA_ "Version" SG_ 172 BLTN_CAM_WiFi_AutoOn_NvalueSet "21.05.02";
BA_ "Description" SG_ 172 BLTN_CAM_StoProp_NvalueSet "Propotion of built-in Cam SD card Propotion set of the Recording Categories";
BA_ "GenSigSendType" SG_ 172 BLTN_CAM_StoProp_NvalueSet 4;
BA_ "UserSigValidity" SG_ 172 BLTN_CAM_StoProp_NvalueSet 0;
BA_REL_ "GenSigTimeoutTime" BU_SG_REL_ BLTN_CAM SG_ 172 BLTN_CAM_StoProp_NvalueSet 0;
BA_ "Version" SG_ 172 BLTN_CAM_StoProp_NvalueSet "21.05.02";
BA_ "Description" SG_ 172 CF_AVN_BLTN_CAM_USMReset "Buit-in Cam USM Reset Request.";
BA_ "GenSigSendType" SG_ 172 CF_AVN_BLTN_CAM_USMReset 4;
BA_ "UserSigValidity" SG_ 172 CF_AVN_BLTN_CAM_USMReset 0;
BA_REL_ "GenSigTimeoutTime" BU_SG_REL_ BLTN_CAM SG_ 172 CF_AVN_BLTN_CAM_USMReset 0;
BA_ "Version" SG_ 172 CF_AVN_BLTN_CAM_USMReset "21.05.02";
BA_ "Description" SG_ 172 CF_AVN_BLTN_CAM_RecReset "Buit-in Cam format(all file delete/Reset) Request.";
BA_ "GenSigSendType" SG_ 172 CF_AVN_BLTN_CAM_RecReset 4;
BA_ "UserSigValidity" SG_ 172 CF_AVN_BLTN_CAM_RecReset 0;
BA_REL_ "GenSigTimeoutTime" BU_SG_REL_ BLTN_CAM SG_ 172 CF_AVN_BLTN_CAM_RecReset 0;
BA_ "Version" SG_ 172 CF_AVN_BLTN_CAM_RecReset "21.05.02";
BA_ "Description" SG_ 172 BLTN_CAM_File_DEL_CPY_Cmd "Buit-in Cam operation control of copying and deleting.";
BA_ "GenSigSendType" SG_ 172 BLTN_CAM_File_DEL_CPY_Cmd 4;
BA_ "UserSigValidity" SG_ 172 BLTN_CAM_File_DEL_CPY_Cmd 0;
BA_REL_ "GenSigTimeoutTime" BU_SG_REL_ BLTN_CAM SG_ 172 BLTN_CAM_File_DEL_CPY_Cmd 0;
BA_ "Version" SG_ 172 BLTN_CAM_File_DEL_CPY_Cmd "21.05.02";
BA_ "Description" SG_ 172 BLTN_CAM_LVDS_Mode_Cmd "This Signal is for LVDS output commend to BLTN_CAM";
BA_ "GenSigSendType" SG_ 172 BLTN_CAM_LVDS_Mode_Cmd 4;
BA_ "UserSigValidity" SG_ 172 BLTN_CAM_LVDS_Mode_Cmd 0;
BA_REL_ "GenSigTimeoutTime" BU_SG_REL_ BLTN_CAM SG_ 172 BLTN_CAM_LVDS_Mode_Cmd 0;
BA_ "Version" SG_ 172 BLTN_CAM_LVDS_Mode_Cmd "21.05.02";
BA_ "Description" SG_ 172 HU_BLTN_CAM_Disp_Touch_Pos_X "X position of touch of display when BLTN-in CAM Engineer mode in";
BA_ "GenSigSendType" SG_ 172 HU_BLTN_CAM_Disp_Touch_Pos_X 4;
BA_ "UserSigValidity" SG_ 172 HU_BLTN_CAM_Disp_Touch_Pos_X 0;
BA_REL_ "GenSigTimeoutTime" BU_SG_REL_ BLTN_CAM SG_ 172 HU_BLTN_CAM_Disp_Touch_Pos_X 0;
BA_ "Version" SG_ 172 HU_BLTN_CAM_Disp_Touch_Pos_X "21.05.02";
BA_ "Description" SG_ 172 HU_BLTN_CAM_Disp_Touch_Pos_Y "Y position of touch of display when BLTN-in CAM Engineer mode in";
BA_ "GenSigSendType" SG_ 172 HU_BLTN_CAM_Disp_Touch_Pos_Y 4;
BA_ "UserSigValidity" SG_ 172 HU_BLTN_CAM_Disp_Touch_Pos_Y 0;
BA_REL_ "GenSigTimeoutTime" BU_SG_REL_ BLTN_CAM SG_ 172 HU_BLTN_CAM_Disp_Touch_Pos_Y 0;
BA_ "Version" SG_ 172 HU_BLTN_CAM_Disp_Touch_Pos_Y "21.05.02";
BA_ "Description" SG_ 172 BLTN_CAM_RR_VerPos_NvalueSet "Rear Camera Vertical position setting value.";
BA_ "GenSigSendType" SG_ 172 BLTN_CAM_RR_VerPos_NvalueSet 4;
BA_ "UserSigValidity" SG_ 172 BLTN_CAM_RR_VerPos_NvalueSet 0;
BA_REL_ "GenSigTimeoutTime" BU_SG_REL_ BLTN_CAM SG_ 172 BLTN_CAM_RR_VerPos_NvalueSet 0;
BA_ "Version" SG_ 172 BLTN_CAM_RR_VerPos_NvalueSet "21.05.02";
BA_ "GenMsgSendType" BO_ 1264 0;
BA_ "GenMsgCycleTime" BO_ 1264 1000;
BA_ "Description" SG_ 1264 HU_TimeSetting "18.08.09_";
BA_ "GenSigSendType" SG_ 1264 HU_TimeSetting 4;
BA_ "GenSigStartValue" SG_ 1264 HU_TimeSetting 3;
BA_ "UserSigValidity" SG_ 1264 HU_TimeSetting 0;
BA_REL_ "GenSigTimeoutTime" BU_SG_REL_ ATS SG_ 1264 HU_TimeSetting 5000;
BA_REL_ "GenSigTimeoutTime" BU_SG_REL_ BLTN_CAM SG_ 1264 HU_TimeSetting 5000;
BA_ "NetworkRequest" SG_ 1264 HU_TimeSetting 0;
BA_ "Version" SG_ 1264 HU_TimeSetting "18.09.02";
BA_ "Description" SG_ 1264 HU_DisplayMinute "18.08.09_";
BA_ "GenSigSendType" SG_ 1264 HU_DisplayMinute 4;
BA_ "GenSigStartValue" SG_ 1264 HU_DisplayMinute 255;
BA_ "UserSigValidity" SG_ 1264 HU_DisplayMinute 0;
BA_REL_ "GenSigTimeoutTime" BU_SG_REL_ ATS SG_ 1264 HU_DisplayMinute 5000;
BA_REL_ "GenSigTimeoutTime" BU_SG_REL_ BLTN_CAM SG_ 1264 HU_DisplayMinute 5000;
BA_ "NetworkRequest" SG_ 1264 HU_DisplayMinute 0;
BA_ "Version" SG_ 1264 HU_DisplayMinute "18.09.02";
BA_ "Description" SG_ 1264 HU_Status "18.08.09_";
BA_ "GenSigSendType" SG_ 1264 HU_Status 4;
BA_ "GenSigStartValue" SG_ 1264 HU_Status 15;
BA_ "UserSigValidity" SG_ 1264 HU_Status 0;
BA_REL_ "GenSigTimeoutTime" BU_SG_REL_ ATS SG_ 1264 HU_Status 5000;
BA_REL_ "GenSigTimeoutTime" BU_SG_REL_ BLTN_CAM SG_ 1264 HU_Status 5000;
BA_ "NetworkRequest" SG_ 1264 HU_Status 0;
BA_ "Version" SG_ 1264 HU_Status "18.09.02";
BA_ "Description" SG_ 1264 HU_DisplaySecond "18.08.09_";
BA_ "GenSigSendType" SG_ 1264 HU_DisplaySecond 4;
BA_ "GenSigStartValue" SG_ 1264 HU_DisplaySecond 255;
BA_ "UserSigValidity" SG_ 1264 HU_DisplaySecond 0;
BA_REL_ "GenSigTimeoutTime" BU_SG_REL_ ATS SG_ 1264 HU_DisplaySecond 5000;
BA_REL_ "GenSigTimeoutTime" BU_SG_REL_ BLTN_CAM SG_ 1264 HU_DisplaySecond 5000;
BA_ "NetworkRequest" SG_ 1264 HU_DisplaySecond 0;
BA_ "Version" SG_ 1264 HU_DisplaySecond "18.09.02";
BA_ "Description" SG_ 1264 HU_DisplayMonth "18.08.09_";
BA_ "GenSigSendType" SG_ 1264 HU_DisplayMonth 4;
BA_ "GenSigStartValue" SG_ 1264 HU_DisplayMonth 15;
BA_ "UserSigValidity" SG_ 1264 HU_DisplayMonth 0;
BA_REL_ "GenSigTimeoutTime" BU_SG_REL_ ATS SG_ 1264 HU_DisplayMonth 5000;
BA_REL_ "GenSigTimeoutTime" BU_SG_REL_ BLTN_CAM SG_ 1264 HU_DisplayMonth 5000;
BA_ "NetworkRequest" SG_ 1264 HU_DisplayMonth 0;
BA_ "Version" SG_ 1264 HU_DisplayMonth "18.09.02";
BA_ "Description" SG_ 1264 HU_DisplayYear1 "18.08.09_";
BA_ "GenSigSendType" SG_ 1264 HU_DisplayYear1 4;
BA_ "GenSigStartValue" SG_ 1264 HU_DisplayYear1 3;
BA_ "UserSigValidity" SG_ 1264 HU_DisplayYear1 0;
BA_REL_ "GenSigTimeoutTime" BU_SG_REL_ ATS SG_ 1264 HU_DisplayYear1 5000;
BA_REL_ "GenSigTimeoutTime" BU_SG_REL_ BLTN_CAM SG_ 1264 HU_DisplayYear1 5000;
BA_ "NetworkRequest" SG_ 1264 HU_DisplayYear1 0;
BA_ "Version" SG_ 1264 HU_DisplayYear1 "18.09.02";
BA_ "Description" SG_ 1264 HU_DisplayYear2 "18.08.09_";
BA_ "GenSigSendType" SG_ 1264 HU_DisplayYear2 4;
BA_ "GenSigStartValue" SG_ 1264 HU_DisplayYear2 255;
BA_ "UserSigValidity" SG_ 1264 HU_DisplayYear2 0;
BA_REL_ "GenSigTimeoutTime" BU_SG_REL_ ATS SG_ 1264 HU_DisplayYear2 5000;
BA_REL_ "GenSigTimeoutTime" BU_SG_REL_ BLTN_CAM SG_ 1264 HU_DisplayYear2 5000;
BA_ "NetworkRequest" SG_ 1264 HU_DisplayYear2 0;
BA_ "Version" SG_ 1264 HU_DisplayYear2 "18.09.02";
BA_ "Description" SG_ 1264 HU_DisplayDay "18.08.09_";
BA_ "GenSigSendType" SG_ 1264 HU_DisplayDay 4;
BA_ "GenSigStartValue" SG_ 1264 HU_DisplayDay 255;
BA_ "UserSigValidity" SG_ 1264 HU_DisplayDay 0;
BA_REL_ "GenSigTimeoutTime" BU_SG_REL_ ATS SG_ 1264 HU_DisplayDay 5000;
BA_REL_ "GenSigTimeoutTime" BU_SG_REL_ BLTN_CAM SG_ 1264 HU_DisplayDay 5000;
BA_ "NetworkRequest" SG_ 1264 HU_DisplayDay 0;
BA_ "Version" SG_ 1264 HU_DisplayDay "18.09.02";
BA_ "Description" SG_ 1264 HU_AM_PM_INFO "18.08.09_";
BA_ "GenSigSendType" SG_ 1264 HU_AM_PM_INFO 4;
BA_ "GenSigStartValue" SG_ 1264 HU_AM_PM_INFO 3;
BA_ "UserSigValidity" SG_ 1264 HU_AM_PM_INFO 0;
BA_REL_ "GenSigTimeoutTime" BU_SG_REL_ ATS SG_ 1264 HU_AM_PM_INFO 5000;
BA_REL_ "GenSigTimeoutTime" BU_SG_REL_ BLTN_CAM SG_ 1264 HU_AM_PM_INFO 5000;
BA_ "NetworkRequest" SG_ 1264 HU_AM_PM_INFO 0;
BA_ "Version" SG_ 1264 HU_AM_PM_INFO "18.09.02";
BA_ "Description" SG_ 1264 HU_TimeFormat "18.08.09_";
BA_ "GenSigSendType" SG_ 1264 HU_TimeFormat 4;
BA_ "GenSigStartValue" SG_ 1264 HU_TimeFormat 3;
BA_ "UserSigValidity" SG_ 1264 HU_TimeFormat 0;
BA_REL_ "GenSigTimeoutTime" BU_SG_REL_ ATS SG_ 1264 HU_TimeFormat 5000;
BA_REL_ "GenSigTimeoutTime" BU_SG_REL_ BLTN_CAM SG_ 1264 HU_TimeFormat 5000;
BA_ "NetworkRequest" SG_ 1264 HU_TimeFormat 0;
BA_ "Version" SG_ 1264 HU_TimeFormat "18.09.02";
BA_ "Description" SG_ 1264 HU_ComRefresh "18.08.09_";
BA_ "GenSigSendType" SG_ 1264 HU_ComRefresh 4;
BA_ "GenSigStartValue" SG_ 1264 HU_ComRefresh 3;
BA_ "UserSigValidity" SG_ 1264 HU_ComRefresh 0;
BA_REL_ "GenSigTimeoutTime" BU_SG_REL_ ATS SG_ 1264 HU_ComRefresh 5000;
BA_REL_ "GenSigTimeoutTime" BU_SG_REL_ BLTN_CAM SG_ 1264 HU_ComRefresh 5000;
BA_ "NetworkRequest" SG_ 1264 HU_ComRefresh 0;
BA_ "Version" SG_ 1264 HU_ComRefresh "18.09.02";
BA_ "Description" SG_ 1264 HU_ClockInfo "18.08.09_";
BA_ "GenSigSendType" SG_ 1264 HU_ClockInfo 4;
BA_ "GenSigStartValue" SG_ 1264 HU_ClockInfo 3;
BA_ "UserSigValidity" SG_ 1264 HU_ClockInfo 0;
BA_REL_ "GenSigTimeoutTime" BU_SG_REL_ ATS SG_ 1264 HU_ClockInfo 5000;
BA_REL_ "GenSigTimeoutTime" BU_SG_REL_ BLTN_CAM SG_ 1264 HU_ClockInfo 5000;
BA_ "NetworkRequest" SG_ 1264 HU_ClockInfo 0;
BA_ "Version" SG_ 1264 HU_ClockInfo "18.09.02";
BA_ "Description" SG_ 1264 HU_DisplayHour "18.08.09_";
BA_ "GenSigSendType" SG_ 1264 HU_DisplayHour 4;
BA_ "GenSigStartValue" SG_ 1264 HU_DisplayHour 255;
BA_ "UserSigValidity" SG_ 1264 HU_DisplayHour 0;
BA_REL_ "GenSigTimeoutTime" BU_SG_REL_ ATS SG_ 1264 HU_DisplayHour 5000;
BA_REL_ "GenSigTimeoutTime" BU_SG_REL_ BLTN_CAM SG_ 1264 HU_DisplayHour 5000;
BA_ "NetworkRequest" SG_ 1264 HU_DisplayHour 0;
BA_ "Version" SG_ 1264 HU_DisplayHour "18.09.02";
BA_ "GenMsgSendType" BO_ 1266 0;
BA_ "GenMsgCycleTime" BO_ 1266 1000;
BA_ "GenSigSendType" SG_ 1266 HU_LanguageInfo 4;
BA_ "GenSigStartValue" SG_ 1266 HU_LanguageInfo 255;
BA_ "UserSigValidity" SG_ 1266 HU_LanguageInfo 1;
BA_REL_ "GenSigTimeoutTime" BU_SG_REL_ ATS SG_ 1266 HU_LanguageInfo 5000;
BA_REL_ "GenSigTimeoutTime" BU_SG_REL_ BLTN_CAM SG_ 1266 HU_LanguageInfo 5000;
BA_ "NetworkRequest" SG_ 1266 HU_LanguageInfo 0;
BA_ "NetworkRequestHoldingTime" SG_ 1266 HU_LanguageInfo 5000;
BA_ "Version" SG_ 1266 HU_LanguageInfo "21.06.12";
BA_ "Description" SG_ 1266 HU_MuteStatus "16.03.03_";
BA_ "GenSigSendType" SG_ 1266 HU_MuteStatus 4;
BA_ "GenSigStartValue" SG_ 1266 HU_MuteStatus 3;
BA_ "UserSigValidity" SG_ 1266 HU_MuteStatus 1;
BA_ "NetworkRequest" SG_ 1266 HU_MuteStatus 0;
BA_ "Version" SG_ 1266 HU_MuteStatus "18.04.02";
BA_ "Description" SG_ 1266 HU_WelcomeReady "HU playback ready signal to play welcome animation video";
BA_ "GenSigSendType" SG_ 1266 HU_WelcomeReady 4;
BA_ "UserSigValidity" SG_ 1266 HU_WelcomeReady 0;
BA_ "Version" SG_ 1266 HU_WelcomeReady "19.04.06";
BA_ "Description" SG_ 1266 HU_UsmSupport "17.04.06_";
BA_ "GenSigSendType" SG_ 1266 HU_UsmSupport 4;
BA_ "GenSigStartValue" SG_ 1266 HU_UsmSupport 3;
BA_ "UserSigValidity" SG_ 1266 HU_UsmSupport 1;
BA_ "Version" SG_ 1266 HU_UsmSupport "18.04.02";
BA_ "Description" SG_ 1266 HU_NaviStatus "18.11.00_";
BA_ "GenSigSendType" SG_ 1266 HU_NaviStatus 4;
BA_ "UserSigValidity" SG_ 1266 HU_NaviStatus 1;
BA_ "NetworkRequest" SG_ 1266 HU_NaviStatus 0;
BA_ "Version" SG_ 1266 HU_NaviStatus "18.11.01";
BA_ "Description" SG_ 1266 HU_NaviDisp "16.03.03_";
BA_ "GenSigSendType" SG_ 1266 HU_NaviDisp 4;
BA_ "GenSigStartValue" SG_ 1266 HU_NaviDisp 3;
BA_ "UserSigValidity" SG_ 1266 HU_NaviDisp 1;
BA_ "NetworkRequest" SG_ 1266 HU_NaviDisp 0;
BA_ "Version" SG_ 1266 HU_NaviDisp "18.04.02";
BA_ "Description" SG_ 1266 HU_BVM_Display_Message "18.08.09_BVM Operation Message";
BA_ "GenSigSendType" SG_ 1266 HU_BVM_Display_Message 4;
BA_ "GenSigStartValue" SG_ 1266 HU_BVM_Display_Message 7;
BA_ "UserSigValidity" SG_ 1266 HU_BVM_Display_Message 3;
BA_ "Version" SG_ 1266 HU_BVM_Display_Message "18.09.02";
BA_ "Description" SG_ 1266 HU_SVM_View_Display "18.04.00_This signal indicates on/off BVM view on the cluster";
BA_ "GenSigSendType" SG_ 1266 HU_SVM_View_Display 4;
BA_ "GenSigStartValue" SG_ 1266 HU_SVM_View_Display 31;
BA_ "UserSigValidity" SG_ 1266 HU_SVM_View_Display 3;
BA_ "Version" SG_ 1266 HU_SVM_View_Display "18.04.02";
BA_ "Description" SG_ 1266 HU_NaviCamSettingStatus "18.08.09_";
BA_ "GenSigSendType" SG_ 1266 HU_NaviCamSettingStatus 4;
BA_ "GenSigStartValue" SG_ 1266 HU_NaviCamSettingStatus 255;
BA_ "UserSigValidity" SG_ 1266 HU_NaviCamSettingStatus 1;
BA_ "NetworkRequest" SG_ 1266 HU_NaviCamSettingStatus 0;
BA_ "Version" SG_ 1266 HU_NaviCamSettingStatus "18.09.02";
BA_ "Description" SG_ 1266 HU_EVSupport "Notification whether EV function support or not.";
BA_ "GenSigSendType" SG_ 1266 HU_EVSupport 4;
BA_ "GenSigStartValue" SG_ 1266 HU_EVSupport 3;
BA_ "UserSigValidity" SG_ 1266 HU_EVSupport 7;
BA_ "Version" SG_ 1266 HU_EVSupport "19.08.06";
BA_ "Description" SG_ 1266 HU_DayNightState "HU(AVNT) display day and night time state (When automatically adjusted)";
BA_ "GenSigSendType" SG_ 1266 HU_DayNightState 4;
BA_ "UserSigValidity" SG_ 1266 HU_DayNightState 0;
BA_ "Version" SG_ 1266 HU_DayNightState "20.11.00";
BA_ "Description" SG_ 1266 HU_AutoBrightState_New "HU Display Brightness State(When automatically adjusted)";
BA_ "GenSigSendType" SG_ 1266 HU_AutoBrightState_New 4;
BA_ "UserSigValidity" SG_ 1266 HU_AutoBrightState_New 0;
BA_ "Version" SG_ 1266 HU_AutoBrightState_New "20.09.01";
BA_ "Description" SG_ 1266 HU_VolumeStatus "16.03.03_";
BA_ "GenSigSendType" SG_ 1266 HU_VolumeStatus 4;
BA_ "GenSigStartValue" SG_ 1266 HU_VolumeStatus 63;
BA_ "UserSigValidity" SG_ 1266 HU_VolumeStatus 1;
BA_ "NetworkRequest" SG_ 1266 HU_VolumeStatus 0;
BA_ "Version" SG_ 1266 HU_VolumeStatus "18.04.02";
BA_ "GenMsgSendType" BO_ 1267 0;
BA_ "GenMsgCycleTime" BO_ 1267 1000;
BA_ "GenSigSendType" SG_ 1267 RSELockOnOff 4;
BA_ "GenSigStartValue" SG_ 1267 RSELockOnOff 3;
BA_ "UserSigValidity" SG_ 1267 RSELockOnOff 1;
BA_REL_ "GenSigTimeoutTime" BU_SG_REL_ APSU SG_ 1267 RSELockOnOff 5000;
BA_REL_ "GenSigTimeoutTime" BU_SG_REL_ ATS SG_ 1267 RSELockOnOff 5000;
BA_ "NetworkRequest" SG_ 1267 RSELockOnOff 0;
BA_ "NetworkRequestHoldingTime" SG_ 1267 RSELockOnOff 5000;
BA_ "Version" SG_ 1267 RSELockOnOff "19.11.11";
BA_ "Description" SG_ 1267 HU_DATC_RearLockSet "18.08.09_";
BA_ "GenSigSendType" SG_ 1267 HU_DATC_RearLockSet 4;
BA_ "GenSigStartValue" SG_ 1267 HU_DATC_RearLockSet 3;
BA_ "UserSigValidity" SG_ 1267 HU_DATC_RearLockSet 3;
BA_ "Version" SG_ 1267 HU_DATC_RearLockSet "18.09.04";
BA_ "Description" SG_ 1267 HU_Graphreset_Info "18.08.09_";
BA_ "GenSigSendType" SG_ 1267 HU_Graphreset_Info 4;
BA_ "GenSigStartValue" SG_ 1267 HU_Graphreset_Info 3;
BA_ "UserSigValidity" SG_ 1267 HU_Graphreset_Info 1;
BA_ "Version" SG_ 1267 HU_Graphreset_Info "18.09.04";
BA_ "Description" SG_ 1267 HU_PhoneActivity "18.08.09_";
BA_ "GenSigSendType" SG_ 1267 HU_PhoneActivity 4;
BA_ "GenSigStartValue" SG_ 1267 HU_PhoneActivity 3;
BA_ "UserSigValidity" SG_ 1267 HU_PhoneActivity 1;
BA_ "NetworkRequest" SG_ 1267 HU_PhoneActivity 0;
BA_ "Version" SG_ 1267 HU_PhoneActivity "19.02.08";
BA_ "Description" SG_ 1267 HU_VRActivity "18.08.09_";
BA_ "GenSigSendType" SG_ 1267 HU_VRActivity 4;
BA_ "GenSigStartValue" SG_ 1267 HU_VRActivity 3;
BA_ "UserSigValidity" SG_ 1267 HU_VRActivity 1;
BA_ "NetworkRequest" SG_ 1267 HU_VRActivity 0;
BA_ "Version" SG_ 1267 HU_VRActivity "19.02.08";
BA_ "Description" SG_ 1267 HU_DATC_AirQuality_Info "18.08.09_";
BA_ "GenSigSendType" SG_ 1267 HU_DATC_AirQuality_Info 4;
BA_ "GenSigStartValue" SG_ 1267 HU_DATC_AirQuality_Info 15;
BA_ "UserSigValidity" SG_ 1267 HU_DATC_AirQuality_Info 3;
BA_ "Version" SG_ 1267 HU_DATC_AirQuality_Info "18.09.04";
BA_ "GenMsgSendType" BO_ 1265 0;
BA_ "GenMsgCycleTime" BO_ 1265 1000;
BA_ "Description" SG_ 1265 HU_IG3_Request "IG3 wake up and sleep Request signal for EV/PHEV/HEV



Please apply this signal after checking ICU on your vehicle.";
BA_ "GenSigSendType" SG_ 1265 HU_IG3_Request 4;
BA_ "GenSigStartValue" SG_ 1265 HU_IG3_Request 3;
BA_ "UserSigValidity" SG_ 1265 HU_IG3_Request 0;
BA_ "Version" SG_ 1265 HU_IG3_Request "20.03.05";
BA_ "Description" SG_ 1265 HU_TeleVehicleStatusReq "18.08.09_Request vehicle status information.";
BA_ "GenSigSendType" SG_ 1265 HU_TeleVehicleStatusReq 4;
BA_ "GenSigStartValue" SG_ 1265 HU_TeleVehicleStatusReq 3;
BA_ "UserSigValidity" SG_ 1265 HU_TeleVehicleStatusReq 0;
BA_ "Version" SG_ 1265 HU_TeleVehicleStatusReq "18.09.04";
BA_ "Description" SG_ 1265 HU_Background "HU Backgound image info";
BA_ "GenSigSendType" SG_ 1265 HU_Background 4;
BA_ "GenSigStartValue" SG_ 1265 HU_Background 7;
BA_ "UserSigValidity" SG_ 1265 HU_Background 1;
BA_REL_ "GenSigTimeoutTime" BU_SG_REL_ ATS SG_ 1265 HU_Background 5000;
BA_REL_ "GenSigTimeoutTime" BU_SG_REL_ BLTN_CAM SG_ 1265 HU_Background 5000;
BA_ "Version" SG_ 1265 HU_Background "21.01.06";
BA_ "Description" SG_ 1265 ccIC_HUD_PbackSta "Status signal for HUD interoperation with IMS

(The number of memory is expanded.)";
BA_ "GenSigSendType" SG_ 1265 ccIC_HUD_PbackSta 4;
BA_ "UserSigValidity" SG_ 1265 ccIC_HUD_PbackSta 3;
BA_REL_ "GenSigTimeoutTime" BU_SG_REL_ DPSU SG_ 1265 ccIC_HUD_PbackSta 5000;
BA_ "Version" SG_ 1265 ccIC_HUD_PbackSta "19.12.00";
BA_ "Description" SG_ 1265 HU_BackgroundFadeInOut "HU Background Fade in/out info

(HEX * Factor) %";
BA_ "GenSigSendType" SG_ 1265 HU_BackgroundFadeInOut 4;
BA_ "GenSigStartValue" SG_ 1265 HU_BackgroundFadeInOut 1023;
BA_ "UserSigValidity" SG_ 1265 HU_BackgroundFadeInOut 1;
BA_REL_ "GenSigTimeoutTime" BU_SG_REL_ ATS SG_ 1265 HU_BackgroundFadeInOut 5000;
BA_REL_ "GenSigTimeoutTime" BU_SG_REL_ BLTN_CAM SG_ 1265 HU_BackgroundFadeInOut 5000;
BA_ "Version" SG_ 1265 HU_BackgroundFadeInOut "21.01.06";
BA_ "Description" SG_ 1265 CF_AVN_AutoWashModeSta "Washer Mode status signal";
BA_ "GenSigSendType" SG_ 1265 CF_AVN_AutoWashModeSta 4;
BA_ "UserSigValidity" SG_ 1265 CF_AVN_AutoWashModeSta 3;
BA_REL_ "GenSigTimeoutTime" BU_SG_REL_ RCM SG_ 1265 CF_AVN_AutoWashModeSta 5000;
BA_ "Version" SG_ 1265 CF_AVN_AutoWashModeSta "21.12.00";
BA_ "GenMsgSendType" BO_ 1278 0;
BA_ "GenMsgCycleTime" BO_ 1278 2000;
BA_ "GenSigSendType" SG_ 1278 HU_Type 4;
BA_ "GenSigStartValue" SG_ 1278 HU_Type 255;
BA_ "UserSigValidity" SG_ 1278 HU_Type 1;
BA_REL_ "GenSigTimeoutTime" BU_SG_REL_ BLTN_CAM SG_ 1278 HU_Type 5000;
BA_ "NetworkRequest" SG_ 1278 HU_Type 0;
BA_ "NetworkRequestHoldingTime" SG_ 1278 HU_Type 7000;
BA_ "Version" SG_ 1278 HU_Type "21.05.00";
BA_ "GenSigSendType" SG_ 1278 HU_DistributeInfo 4;
BA_ "GenSigStartValue" SG_ 1278 HU_DistributeInfo 255;
BA_ "UserSigValidity" SG_ 1278 HU_DistributeInfo 1;
BA_REL_ "GenSigTimeoutTime" BU_SG_REL_ BLTN_CAM SG_ 1278 HU_DistributeInfo 5000;
BA_ "NetworkRequest" SG_ 1278 HU_DistributeInfo 0;
BA_ "NetworkRequestHoldingTime" SG_ 1278 HU_DistributeInfo 7000;
BA_ "Version" SG_ 1278 HU_DistributeInfo "20.09.00";
BA_ "Description" SG_ 1278 HU_OptionInfo "Bit0 : Navi (0: Not Support / 1: Support)

Bit1 : USM (0: Not Support / 1: Support)

Bit2 : TMS (0: Not Support / 1: Support)

Bit3 : Multi Profile (0: Not Support(No Profile or Single Profile)  / 1: Support)

Bit4 : Camera Guideline (0: Displayed by Camera / 1: Displayed by H/U)

Bit5 : LVDS Interface (0:MIPI, 1:Non-MIPI)

Bit6 : Welcome/Goodbye Animation Support (0: Not Support / 1: Support)

Bit7 : Drive/Custom Mode Support (0: Not Support / 1 : Support)

Bit8 : Automatic brightness adjustment function Support (0: Not Support / 1 : Support) 

Bit9~Bit14 : Reserved

Bit15 : 1 Invalid";
BA_ "GenSigSendType" SG_ 1278 HU_OptionInfo 4;
BA_ "GenSigStartValue" SG_ 1278 HU_OptionInfo 32768;
BA_ "UserSigValidity" SG_ 1278 HU_OptionInfo 0;
BA_REL_ "GenSigTimeoutTime" BU_SG_REL_ BLTN_CAM SG_ 1278 HU_OptionInfo 5000;
BA_ "Version" SG_ 1278 HU_OptionInfo "21.04.03";
BA_ "Description" SG_ 1278 HU_NaviMapInfo "Information about map data  used in Navigation";
BA_ "GenSigSendType" SG_ 1278 HU_NaviMapInfo 4;
BA_ "UserSigValidity" SG_ 1278 HU_NaviMapInfo 1;
BA_ "Version" SG_ 1278 HU_NaviMapInfo "20.05.03";
BA_ "Description" SG_ 1278 HU_NaviHandshakingSupport "This is a signal to send whether handshaking logic is applied related to Navigation's 'Map based ADAS' specification";
BA_ "GenSigSendType" SG_ 1278 HU_NaviHandshakingSupport 4;
BA_ "UserSigValidity" SG_ 1278 HU_NaviHandshakingSupport 1;
BA_ "Version" SG_ 1278 HU_NaviHandshakingSupport "20.05.02";
BA_ "GenSigSendType" SG_ 1278 HU_AMP_EQVariant 4;
BA_ "GenSigStartValue" SG_ 1278 HU_AMP_EQVariant 31;
BA_ "UserSigValidity" SG_ 1278 HU_AMP_EQVariant 1;
BA_ "Version" SG_ 1278 HU_AMP_EQVariant "20.08.06";
BA_ "Description" SG_ 1278 HU_AdasSupport "0x0 : Not Support

0x1 : ADAS Support (General Map) - Send map information based on General Map

0x2 : ADAS Support (Map based ADAS v1) - Send map information based on Map based ADAS v1 or v1.5

0x3 : ADAS Support (Map based ADAS v2) - Send map information based on Map based ADAS v2.0

0x4 : ADAS Support (Map based ADAS v2.0 & Handshaking) - Send map information based on Map based ADAS v2.0 & Support Handshaking 

0x5 : ADAS Support (Map based ADAS v2.3)  

 - 2nd CAN DB :  Send map information based on Map based ADAS v2.3 

 - 3rd CAN DB : Send map information based on Map based ADAS v2.3 & Support Handshaking";
BA_ "GenSigSendType" SG_ 1278 HU_AdasSupport 4;
BA_ "GenSigStartValue" SG_ 1278 HU_AdasSupport 7;
BA_ "UserSigValidity" SG_ 1278 HU_AdasSupport 1;
BA_ "NetworkRequest" SG_ 1278 HU_AdasSupport 0;
BA_ "NetworkRequestHoldingTime" SG_ 1278 HU_AdasSupport 5000;
BA_ "Version" SG_ 1278 HU_AdasSupport "20.05.02";
BA_ "Description" SG_ 1278 HU_Navi_RspADASMapMsg "This signal indicates an ADAS map message response from H_U to ECU 

which is stored the  required Map based ADAS messages for each ECU



Each bit indicates the request messages as follows.

(1: Sending message / 0 : Doens't sending message)

- Bit 0 : H_U_NAVI_V2_STUB_E

- Bit 1 : HU_NAVI_V2_PROSHORT_E_00 (Curvature info)

- Bit 2 : HU_NAVI_V2_PROSHORT_E_00 (Info execpt curvature)

- Bit 3 : HU_NAVI_V2_PROSHORT_E_01

- Bit 4 : HU_NAVI_V2_PROSHORT_E_02

- Bit 5 : HU_NAVI_V2_PROLONG_E

- Bit 6 : HU_NAVI_V2_SEG_SUB_E, 

             HU_NAVI_V2_STUB_SUB_E, 

             HU_NAVI_V2_PROSHORT_SUB_E, 

             HU_NAVI_V2_PROLONG_SUB_E

- Bit 7 : HU_NAVI_V2_PATH_PE_00, 

             HU_NAVI_V2_PATH_PE_01

- Bit 8~15 : Reserved";
BA_ "GenSigSendType" SG_ 1278 HU_Navi_RspADASMapMsg 4;
BA_ "UserSigValidity" SG_ 1278 HU_Navi_RspADASMapMsg 3;
BA_ "Version" SG_ 1278 HU_Navi_RspADASMapMsg "21.11.04";
BA_ "GenMsgCycleTime" BO_ 1279 0;
BA_ "Description" SG_ 1279 USM_SmartRegen_Map_Set "Smart Regeneration 2.0 Map information USM User set signal";
BA_ "GenSigSendType" SG_ 1279 USM_SmartRegen_Map_Set 4;
BA_ "UserSigValidity" SG_ 1279 USM_SmartRegen_Map_Set 3;
BA_ "Version" SG_ 1279 USM_SmartRegen_Map_Set "19.11.05";
BA_ "Description" SG_ 1279 USM_SmartRegen_Sens_Set "Smart Regeneration User Personality of Reduction Set Signal";
BA_ "GenSigSendType" SG_ 1279 USM_SmartRegen_Sens_Set 4;
BA_ "UserSigValidity" SG_ 1279 USM_SmartRegen_Sens_Set 3;
BA_ "Version" SG_ 1279 USM_SmartRegen_Sens_Set "19.11.05";
BA_ "Description" SG_ 1279 AVN_SeatPosMemory_Btn "Seat position save signal";
BA_ "GenSigSendType" SG_ 1279 AVN_SeatPosMemory_Btn 4;
BA_ "UserSigValidity" SG_ 1279 AVN_SeatPosMemory_Btn 3;
BA_ "Version" SG_ 1279 AVN_SeatPosMemory_Btn "19.11.11";
BA_ "Description" SG_ 1279 AVN_SeatPosPlyBck_Btn "Seat position move signal";
BA_ "GenSigSendType" SG_ 1279 AVN_SeatPosPlyBck_Btn 4;
BA_ "UserSigValidity" SG_ 1279 AVN_SeatPosPlyBck_Btn 3;
BA_REL_ "GenSigTimeoutTime" BU_SG_REL_ DPSU SG_ 1279 AVN_SeatPosPlyBck_Btn 0;
BA_ "Version" SG_ 1279 AVN_SeatPosPlyBck_Btn "19.11.11";
BA_ "Description" SG_ 1279 USM_RhstaLvlEnaSetReq "USM Request for CMS Brightness with Rheostat";
BA_ "GenSigSendType" SG_ 1279 USM_RhstaLvlEnaSetReq 4;
BA_ "UserSigValidity" SG_ 1279 USM_RhstaLvlEnaSetReq 0;
BA_ "Version" SG_ 1279 USM_RhstaLvlEnaSetReq "19.12.00";
BA_ "Description" SG_ 1279 USM_CMSDayBrgtnsLvlLHSetReq "USM Request for Day Brightness Level of CMS LH";
BA_ "GenSigSendType" SG_ 1279 USM_CMSDayBrgtnsLvlLHSetReq 4;
BA_ "GenSigStartValue" SG_ 1279 USM_CMSDayBrgtnsLvlLHSetReq 15;
BA_ "UserSigValidity" SG_ 1279 USM_CMSDayBrgtnsLvlLHSetReq 0;
BA_ "Version" SG_ 1279 USM_CMSDayBrgtnsLvlLHSetReq "19.12.00";
BA_ "Description" SG_ 1279 USM_CMSNgtBrgtnsLvlLHSetReq "USM Request for Night Brightness Level of CMS LH";
BA_ "GenSigSendType" SG_ 1279 USM_CMSNgtBrgtnsLvlLHSetReq 4;
BA_ "GenSigStartValue" SG_ 1279 USM_CMSNgtBrgtnsLvlLHSetReq 15;
BA_ "UserSigValidity" SG_ 1279 USM_CMSNgtBrgtnsLvlLHSetReq 0;
BA_ "Version" SG_ 1279 USM_CMSNgtBrgtnsLvlLHSetReq "19.12.00";
BA_ "Description" SG_ 1279 USM_CMSDayBrgtnsLvlRHSetReq "USM Request for Day Brightness Level of CMS RH";
BA_ "GenSigSendType" SG_ 1279 USM_CMSDayBrgtnsLvlRHSetReq 4;
BA_ "GenSigStartValue" SG_ 1279 USM_CMSDayBrgtnsLvlRHSetReq 15;
BA_ "UserSigValidity" SG_ 1279 USM_CMSDayBrgtnsLvlRHSetReq 0;
BA_ "Version" SG_ 1279 USM_CMSDayBrgtnsLvlRHSetReq "19.12.00";
BA_ "Description" SG_ 1279 USM_CMSNgtBrgtnsLvlRHSetReq "USM Request for Night Brightness Level of CMS RH";
BA_ "GenSigSendType" SG_ 1279 USM_CMSNgtBrgtnsLvlRHSetReq 4;
BA_ "GenSigStartValue" SG_ 1279 USM_CMSNgtBrgtnsLvlRHSetReq 15;
BA_ "UserSigValidity" SG_ 1279 USM_CMSNgtBrgtnsLvlRHSetReq 0;
BA_ "Version" SG_ 1279 USM_CMSNgtBrgtnsLvlRHSetReq "19.12.00";
BA_ "Description" SG_ 1279 USM_CMSBrgtnsReset "CMS Brightness Reset (LH/RH)";
BA_ "GenSigSendType" SG_ 1279 USM_CMSBrgtnsReset 4;
BA_ "UserSigValidity" SG_ 1279 USM_CMSBrgtnsReset 3;
BA_ "Version" SG_ 1279 USM_CMSBrgtnsReset "20.06.01";
BA_ "Description" SG_ 1279 USM_TurnDistLnDispSetReq "USM Request for CMS Distance Lane Display";
BA_ "GenSigSendType" SG_ 1279 USM_TurnDistLnDispSetReq 4;
BA_ "UserSigValidity" SG_ 1279 USM_TurnDistLnDispSetReq 0;
BA_ "Version" SG_ 1279 USM_TurnDistLnDispSetReq "19.12.00";
BA_ "Description" SG_ 1279 PCA_FrSd_NValueSet "USM Request for PCA Front/Side";
BA_ "GenSigSendType" SG_ 1279 PCA_FrSd_NValueSet 4;
BA_ "UserSigValidity" SG_ 1279 PCA_FrSd_NValueSet 3;
BA_ "Version" SG_ 1279 PCA_FrSd_NValueSet "19.12.00";
BA_ "Description" SG_ 1279 CF_AVN_1stRrStRmndNValueSet "This signal is for seting the ROA function when IBU control ROA Function.";
BA_ "GenSigSendType" SG_ 1279 CF_AVN_1stRrStRmndNValueSet 4;
BA_ "UserSigValidity" SG_ 1279 CF_AVN_1stRrStRmndNValueSet 3;
BA_ "Version" SG_ 1279 CF_AVN_1stRrStRmndNValueSet "20.03.05";
BA_ "Description" SG_ 1279 AVN_Usm_CluThemeSta_New "This signal is used for a Cluster theme setting.";
BA_ "GenSigSendType" SG_ 1279 AVN_Usm_CluThemeSta_New 4;
BA_ "UserSigValidity" SG_ 1279 AVN_Usm_CluThemeSta_New 3;
BA_ "Version" SG_ 1279 AVN_Usm_CluThemeSta_New "20.09.00";
BA_ "Description" SG_ 1279 C_AllDrOpnNValueSet "ALL Door (PSD PTG) Open Function by FOB Unlock Long Key USM Setting Signal

0x0 : Not Display in USM

0x1 : All Door Open Function Off

0x2 : Only PSD Open By FOB Unlock Long KEY

0x3 : PSD and PTG Open by FOB Unlock Long KEY

0x4 ~ 0x6 : Reserved

0x7 : Invalid";
BA_ "GenSigSendType" SG_ 1279 C_AllDrOpnNValueSet 4;
BA_ "UserSigValidity" SG_ 1279 C_AllDrOpnNValueSet 3;
BA_ "Version" SG_ 1279 C_AllDrOpnNValueSet "19.12.07";
BA_ "Description" SG_ 1279 USM_RpmECOSet "Relation To cluster Gauge Display";
BA_ "GenSigSendType" SG_ 1279 USM_RpmECOSet 4;
BA_ "UserSigValidity" SG_ 1279 USM_RpmECOSet 3;
BA_ "Version" SG_ 1279 USM_RpmECOSet "20.06.01";
BA_ "Description" SG_ 1279 VESS_ChgGuideMdLvl "Charging Guide Volume Level function USM signal";
BA_ "GenSigSendType" SG_ 1279 VESS_ChgGuideMdLvl 4;
BA_ "UserSigValidity" SG_ 1279 VESS_ChgGuideMdLvl 3;
BA_ "Version" SG_ 1279 VESS_ChgGuideMdLvl "20.05.01";
BA_ "Description" SG_ 1279 Usm_RpmSPORTSet "Relation to cluster RPM Gauge Display";
BA_ "GenSigSendType" SG_ 1279 Usm_RpmSPORTSet 4;
BA_ "UserSigValidity" SG_ 1279 Usm_RpmSPORTSet 3;
BA_ "Version" SG_ 1279 Usm_RpmSPORTSet "20.02.04";
BA_ "Description" SG_ 1279 Usm_RpmSPORTPLUSSet "RElation to Cluster RPM Gauge Display";
BA_ "GenSigSendType" SG_ 1279 Usm_RpmSPORTPLUSSet 4;
BA_ "UserSigValidity" SG_ 1279 Usm_RpmSPORTPLUSSet 3;
BA_ "Version" SG_ 1279 Usm_RpmSPORTPLUSSet "20.02.04";
BA_ "GenMsgCycleTime" BO_ 200 0;
BA_ "Description" SG_ 200 CF_AVN_ADrLNValueSet_2 "USM Reqeust for Auto Door Lock";
BA_ "GenSigSendType" SG_ 200 CF_AVN_ADrLNValueSet_2 4;
BA_ "UserSigValidity" SG_ 200 CF_AVN_ADrLNValueSet_2 3;
BA_ "RoutingFactor" SG_ 200 CF_AVN_ADrLNValueSet_2 0;
BA_ "Version" SG_ 200 CF_AVN_ADrLNValueSet_2 "21.01.06";
BA_ "Description" SG_ 200 CF_AVN_FCA_JC_OnOffEquipNvalueSet "USM Set signal for Forward Corss-traffic";
BA_ "GenSigSendType" SG_ 200 CF_AVN_FCA_JC_OnOffEquipNvalueSet 4;
BA_ "UserSigValidity" SG_ 200 CF_AVN_FCA_JC_OnOffEquipNvalueSet 3;
BA_ "RoutingFactor" SG_ 200 CF_AVN_FCA_JC_OnOffEquipNvalueSet 0;
BA_ "Version" SG_ 200 CF_AVN_FCA_JC_OnOffEquipNvalueSet "20.12.00";
BA_ "Description" SG_ 200 CF_AVN_FCA_FrSdOnOffEquipNvalueSet "USM Set signal for Forward/Side Safety";
BA_ "GenSigSendType" SG_ 200 CF_AVN_FCA_FrSdOnOffEquipNvalueSet 4;
BA_ "UserSigValidity" SG_ 200 CF_AVN_FCA_FrSdOnOffEquipNvalueSet 3;
BA_ "RoutingFactor" SG_ 200 CF_AVN_FCA_FrSdOnOffEquipNvalueSet 0;
BA_ "Version" SG_ 200 CF_AVN_FCA_FrSdOnOffEquipNvalueSet "20.12.00";
BA_ "Description" SG_ 200 CF_AVN_LKA_OnOffEquip2NvalueSet "USM Set Signal for Lane safety";
BA_ "GenSigSendType" SG_ 200 CF_AVN_LKA_OnOffEquip2NvalueSet 4;
BA_ "UserSigValidity" SG_ 200 CF_AVN_LKA_OnOffEquip2NvalueSet 3;
BA_ "RoutingFactor" SG_ 200 CF_AVN_LKA_OnOffEquip2NvalueSet 0;
BA_ "Version" SG_ 200 CF_AVN_LKA_OnOffEquip2NvalueSet "20.12.00";
BA_ "Description" SG_ 200 CF_AVN_BCA_OnOffEquip2NvalueSet "USM Set signal for Side/Rear Safety";
BA_ "GenSigSendType" SG_ 200 CF_AVN_BCA_OnOffEquip2NvalueSet 4;
BA_ "UserSigValidity" SG_ 200 CF_AVN_BCA_OnOffEquip2NvalueSet 3;
BA_ "RoutingFactor" SG_ 200 CF_AVN_BCA_OnOffEquip2NvalueSet 0;
BA_ "Version" SG_ 200 CF_AVN_BCA_OnOffEquip2NvalueSet "20.12.00";
BA_ "Description" SG_ 200 CF_AVN_BVM_OnOffEquipNvalueSet "USM Set signal for Blind Spot View";
BA_ "GenSigSendType" SG_ 200 CF_AVN_BVM_OnOffEquipNvalueSet 4;
BA_ "UserSigValidity" SG_ 200 CF_AVN_BVM_OnOffEquipNvalueSet 3;
BA_ "RoutingFactor" SG_ 200 CF_AVN_BVM_OnOffEquipNvalueSet 0;
BA_ "Version" SG_ 200 CF_AVN_BVM_OnOffEquipNvalueSet "20.12.00";
BA_ "Description" SG_ 200 CF_AVN_SEA_OnOffEquip3NvalueSet "Usm Set signal for safety exit assist";
BA_ "GenSigSendType" SG_ 200 CF_AVN_SEA_OnOffEquip3NvalueSet 4;
BA_ "UserSigValidity" SG_ 200 CF_AVN_SEA_OnOffEquip3NvalueSet 3;
BA_ "RoutingFactor" SG_ 200 CF_AVN_SEA_OnOffEquip3NvalueSet 0;
BA_ "Version" SG_ 200 CF_AVN_SEA_OnOffEquip3NvalueSet "20.12.00";
BA_ "Description" SG_ 200 CF_AVN_BodySpprtSet_AST "Ergo-Motion Seat Smart Posture Assist";
BA_ "GenSigSendType" SG_ 200 CF_AVN_BodySpprtSet_AST 4;
BA_ "GenSigStartValue" SG_ 200 CF_AVN_BodySpprtSet_AST 3;
BA_ "UserSigValidity" SG_ 200 CF_AVN_BodySpprtSet_AST 3;
BA_REL_ "GenSigTimeoutTime" BU_SG_REL_ ALBCU SG_ 200 CF_AVN_BodySpprtSet_AST 0;
BA_ "RoutingFactor" SG_ 200 CF_AVN_BodySpprtSet_AST 0;
BA_ "Version" SG_ 200 CF_AVN_BodySpprtSet_AST "20.10.02";
BA_ "Description" SG_ 200 CF_AVN_SEW_OnOffEquip3NvalueSet "Usm Set signal for Safety exit warning";
BA_ "GenSigSendType" SG_ 200 CF_AVN_SEW_OnOffEquip3NvalueSet 4;
BA_ "UserSigValidity" SG_ 200 CF_AVN_SEW_OnOffEquip3NvalueSet 3;
BA_ "RoutingFactor" SG_ 200 CF_AVN_SEW_OnOffEquip3NvalueSet 0;
BA_ "Version" SG_ 200 CF_AVN_SEW_OnOffEquip3NvalueSet "20.12.00";
BA_ "Description" SG_ 200 CF_AVN_HudImsAutoSave "USM request for auto save HUD setting with IMS";
BA_ "GenSigSendType" SG_ 200 CF_AVN_HudImsAutoSave 4;
BA_ "UserSigValidity" SG_ 200 CF_AVN_HudImsAutoSave 3;
BA_ "RoutingFactor" SG_ 200 CF_AVN_HudImsAutoSave 0;
BA_ "Version" SG_ 200 CF_AVN_HudImsAutoSave "20.12.05";
BA_ "Description" SG_ 200 USM_PwrDrBuzzerNValueSet "USM Request for Power Door Buzzer";
BA_ "GenSigSendType" SG_ 200 USM_PwrDrBuzzerNValueSet 4;
BA_ "UserSigValidity" SG_ 200 USM_PwrDrBuzzerNValueSet 3;
BA_ "RoutingFactor" SG_ 200 USM_PwrDrBuzzerNValueSet 0;
BA_ "Version" SG_ 200 USM_PwrDrBuzzerNValueSet "21.01.06";
BA_ "Description" SG_ 200 CF_AVN_DWLNValueSet "Request for USM Dynamic Welcome Light";
BA_ "GenSigSendType" SG_ 200 CF_AVN_DWLNValueSet 4;
BA_ "UserSigValidity" SG_ 200 CF_AVN_DWLNValueSet 3;
BA_ "RoutingFactor" SG_ 200 CF_AVN_DWLNValueSet 0;
BA_ "Version" SG_ 200 CF_AVN_DWLNValueSet "21.01.01";
BA_ "Description" SG_ 200 CF_AVN_AirSptTimeNValueSet_AST "Ergo-Motion Seat Comfortable Stretch Operational Time";
BA_ "GenSigSendType" SG_ 200 CF_AVN_AirSptTimeNValueSet_AST 4;
BA_ "GenSigStartValue" SG_ 200 CF_AVN_AirSptTimeNValueSet_AST 7;
BA_ "UserSigValidity" SG_ 200 CF_AVN_AirSptTimeNValueSet_AST 3;
BA_REL_ "GenSigTimeoutTime" BU_SG_REL_ ALBCU SG_ 200 CF_AVN_AirSptTimeNValueSet_AST 0;
BA_ "RoutingFactor" SG_ 200 CF_AVN_AirSptTimeNValueSet_AST 0;
BA_ "Version" SG_ 200 CF_AVN_AirSptTimeNValueSet_AST "20.10.02";
BA_ "Description" SG_ 200 CF_AVN_AirSptStrNValue_AST "Ergo-Motion Seat Comfortable Stretch Strong/Normal";
BA_ "GenSigSendType" SG_ 200 CF_AVN_AirSptStrNValue_AST 4;
BA_ "GenSigStartValue" SG_ 200 CF_AVN_AirSptStrNValue_AST 3;
BA_ "UserSigValidity" SG_ 200 CF_AVN_AirSptStrNValue_AST 3;
BA_REL_ "GenSigTimeoutTime" BU_SG_REL_ ALBCU SG_ 200 CF_AVN_AirSptStrNValue_AST 0;
BA_ "RoutingFactor" SG_ 200 CF_AVN_AirSptStrNValue_AST 0;
BA_ "Version" SG_ 200 CF_AVN_AirSptStrNValue_AST "20.10.02";
BA_ "Description" SG_ 200 CF_AVN_SeatDrvModNvalueSet_AST "Ergo-Motion Seat Smart Support";
BA_ "GenSigSendType" SG_ 200 CF_AVN_SeatDrvModNvalueSet_AST 4;
BA_ "GenSigStartValue" SG_ 200 CF_AVN_SeatDrvModNvalueSet_AST 3;
BA_ "UserSigValidity" SG_ 200 CF_AVN_SeatDrvModNvalueSet_AST 3;
BA_REL_ "GenSigTimeoutTime" BU_SG_REL_ ALBCU SG_ 200 CF_AVN_SeatDrvModNvalueSet_AST 0;
BA_ "RoutingFactor" SG_ 200 CF_AVN_SeatDrvModNvalueSet_AST 0;
BA_ "Version" SG_ 200 CF_AVN_SeatDrvModNvalueSet_AST "20.12.00";
BA_ "Description" SG_ 200 CF_AVN_TPMS_TireReplaceNValueSet "USM Set Signal for Standard Tire to Wnter Tire";
BA_ "GenSigSendType" SG_ 200 CF_AVN_TPMS_TireReplaceNValueSet 4;
BA_ "UserSigValidity" SG_ 200 CF_AVN_TPMS_TireReplaceNValueSet 3;
BA_ "RoutingFactor" SG_ 200 CF_AVN_TPMS_TireReplaceNValueSet 0;
BA_ "Version" SG_ 200 CF_AVN_TPMS_TireReplaceNValueSet "20.12.04";
BA_ "Description" SG_ 200 CF_AVN_TowModeSet "USM Set signal For TowMode";
BA_ "GenSigSendType" SG_ 200 CF_AVN_TowModeSet 4;
BA_ "UserSigValidity" SG_ 200 CF_AVN_TowModeSet 3;
BA_ "RoutingFactor" SG_ 200 CF_AVN_TowModeSet 0;
BA_ "Version" SG_ 200 CF_AVN_TowModeSet "20.12.04";
BA_ "Description" SG_ 200 USM_PwrDrCloseByBraekNValueSet "USM Reqeust for Power Door Close by Brake";
BA_ "GenSigSendType" SG_ 200 USM_PwrDrCloseByBraekNValueSet 4;
BA_ "UserSigValidity" SG_ 200 USM_PwrDrCloseByBraekNValueSet 3;
BA_ "RoutingFactor" SG_ 200 USM_PwrDrCloseByBraekNValueSet 0;
BA_ "Version" SG_ 200 USM_PwrDrCloseByBraekNValueSet "21.01.06";
BA_ "Description" SG_ 200 CF_AVN_ISLANAOffstNvalueSet "Control ISLA offset on USM Fucntion (North America)";
BA_ "GenSigSendType" SG_ 200 CF_AVN_ISLANAOffstNvalueSet 4;
BA_ "UserSigValidity" SG_ 200 CF_AVN_ISLANAOffstNvalueSet 3;
BA_ "RoutingFactor" SG_ 200 CF_AVN_ISLANAOffstNvalueSet 0;
BA_ "Version" SG_ 200 CF_AVN_ISLANAOffstNvalueSet "21.03.10";
BA_ "Description" SG_ 200 USM_DrvGhostDoorReq "USM Request for Driver Door Ghost Door Closing On/Off";
BA_ "GenSigSendType" SG_ 200 USM_DrvGhostDoorReq 4;
BA_ "UserSigValidity" SG_ 200 USM_DrvGhostDoorReq 3;
BA_ "RoutingFactor" SG_ 200 USM_DrvGhostDoorReq 0;
BA_ "Version" SG_ 200 USM_DrvGhostDoorReq "21.03.11";
BA_ "Description" SG_ 200 USM_AstGhostDoorReq "USM Request for Assistant Ghost Door Closing On/Off";
BA_ "GenSigSendType" SG_ 200 USM_AstGhostDoorReq 4;
BA_ "UserSigValidity" SG_ 200 USM_AstGhostDoorReq 3;
BA_ "RoutingFactor" SG_ 200 USM_AstGhostDoorReq 0;
BA_ "Version" SG_ 200 USM_AstGhostDoorReq "21.03.11";
BA_ "Description" SG_ 200 USM_RLGhostDoorReq "USM Request for Rear Left Ghost Door Closing On/Off";
BA_ "GenSigSendType" SG_ 200 USM_RLGhostDoorReq 4;
BA_ "UserSigValidity" SG_ 200 USM_RLGhostDoorReq 3;
BA_ "RoutingFactor" SG_ 200 USM_RLGhostDoorReq 0;
BA_ "Version" SG_ 200 USM_RLGhostDoorReq "21.03.11";
BA_ "Description" SG_ 200 USM_RRGhostDoorReq "USM Request for Rear Right Ghost Door Closing On/Off";
BA_ "GenSigSendType" SG_ 200 USM_RRGhostDoorReq 4;
BA_ "UserSigValidity" SG_ 200 USM_RRGhostDoorReq 3;
BA_ "RoutingFactor" SG_ 200 USM_RRGhostDoorReq 0;
BA_ "Version" SG_ 200 USM_RRGhostDoorReq "21.03.11";
BA_ "Description" SG_ 200 CF_AVN_FCA_FrOnOffEquipNvalueSet "USM Set Signal for Forward Safety";
BA_ "GenSigSendType" SG_ 200 CF_AVN_FCA_FrOnOffEquipNvalueSet 4;
BA_ "UserSigValidity" SG_ 200 CF_AVN_FCA_FrOnOffEquipNvalueSet 3;
BA_ "RoutingFactor" SG_ 200 CF_AVN_FCA_FrOnOffEquipNvalueSet 0;
BA_ "Version" SG_ 200 CF_AVN_FCA_FrOnOffEquipNvalueSet "20.12.00";
BA_ "Description" SG_ 200 CF_AVN_FCA_WarnTimeNvalueSet "USM Set signal for Forward Warntime";
BA_ "GenSigSendType" SG_ 200 CF_AVN_FCA_WarnTimeNvalueSet 4;
BA_ "UserSigValidity" SG_ 200 CF_AVN_FCA_WarnTimeNvalueSet 3;
BA_ "RoutingFactor" SG_ 200 CF_AVN_FCA_WarnTimeNvalueSet 0;
BA_ "Version" SG_ 200 CF_AVN_FCA_WarnTimeNvalueSet "20.12.00";
BA_ "GenMsgSendType" BO_ 2172675330 0;
BA_ "GenMsgCycleTime" BO_ 2172675330 50;
BA_ "GenMsgCycleTimeFast" BO_ 2172675330 0;
BA_ "GenMsgNrOfRepetition" BO_ 2172675330 0;
BA_ "VFrameFormat" BO_ 2172675330 1;
BA_ "Description" SG_ 2172675330 IEB_Sta "EBS Ready Status

¡Ø Àü/ÈÄ·û¿¡ ´ëÇÑ ±¸ºÐÀÌ ¾ø´Â °æ¿ì¿¡´Â 0x0 (Not Ready) / 0x1(Ready) ¸¸ »ç¿ëÇÑ´Ù.

     : Àü·û ±¸µ¿ È¸»ýÁ¦µ¿ Â÷·®ÀÇ °æ¿ì, 0x0 ´Â Front not Ready / 0x1Àº Front only Ready¸¦ ÀÇ¹ÌÇÔ.";
BA_ "UserSigValidity" SG_ 2172675330 IEB_Sta 3;
BA_ "RoutingFactor" SG_ 2172675330 IEB_Sta 5;
BA_ "Version" SG_ 2172675330 IEB_Sta "19.06.01";
BA_ "UserSigValidity" SG_ 2172675330 IEB_SnsrFailSta 3;
BA_ "RoutingFactor" SG_ 2172675330 IEB_SnsrFailSta 5;
BA_ "Version" SG_ 2172675330 IEB_SnsrFailSta "19.05.02";
BA_ "Description" SG_ 2172675330 IEB_EstTtlBrkFrcNmVal "Estimated Total Brake Force";
BA_ "UserSigValidity" SG_ 2172675330 IEB_EstTtlBrkFrcNmVal 3;
BA_ "RoutingFactor" SG_ 2172675330 IEB_EstTtlBrkFrcNmVal 5;
BA_ "Version" SG_ 2172675330 IEB_EstTtlBrkFrcNmVal "19.05.02";
BA_ "Description" SG_ 2172675330 IEB_RbsWrngLmpSta "This signal indicates RBS warning lamp status.";
BA_ "UserSigValidity" SG_ 2172675330 IEB_RbsWrngLmpSta 3;
BA_ "RoutingFactor" SG_ 2172675330 IEB_RbsWrngLmpSta 5;
BA_ "Version" SG_ 2172675330 IEB_RbsWrngLmpSta "19.05.02";
BA_ "Description" SG_ 2172675330 IEB_StrkDpthPcVal "Brake Pedal Stroke Depth";
BA_ "UserSigValidity" SG_ 2172675330 IEB_StrkDpthPcVal 3;
BA_ "RoutingFactor" SG_ 2172675330 IEB_StrkDpthPcVal 5;
BA_ "Version" SG_ 2172675330 IEB_StrkDpthPcVal "19.05.02";
BA_ "Description" SG_ 2172675330 IEB_EstDpthPcVal "Estimated Brake Pedal Depth for SCC";
BA_ "UserSigValidity" SG_ 2172675330 IEB_EstDpthPcVal 3;
BA_ "RoutingFactor" SG_ 2172675330 IEB_EstDpthPcVal 5;
BA_ "Version" SG_ 2172675330 IEB_EstDpthPcVal "19.05.02";
BA_ "Description" SG_ 2172675330 IEB_AbsNGearReq "indigates N gear position request while ABS activation";
BA_ "UserSigValidity" SG_ 2172675330 IEB_AbsNGearReq 3;
BA_ "RoutingFactor" SG_ 2172675330 IEB_AbsNGearReq 5;
BA_ "Version" SG_ 2172675330 IEB_AbsNGearReq "19.05.02";
BA_ "Description" SG_ 2172675330 IEB_EstBrkPdlValVldSta "Estimated Brake pedal value Validity";
BA_ "GenSigStartValue" SG_ 2172675330 IEB_EstBrkPdlValVldSta 1;
BA_ "UserSigValidity" SG_ 2172675330 IEB_EstBrkPdlValVldSta 3;
BA_ "RoutingFactor" SG_ 2172675330 IEB_EstBrkPdlValVldSta 5;
BA_ "Version" SG_ 2172675330 IEB_EstBrkPdlValVldSta "19.05.02";
BA_ "Description" SG_ 2172675330 IEB_VacSysDfctvSta "This signal indicates Vacuum pump ¡°defective¡±.";
BA_ "UserSigValidity" SG_ 2172675330 IEB_VacSysDfctvSta 3;
BA_ "RoutingFactor" SG_ 2172675330 IEB_VacSysDfctvSta 5;
BA_ "Version" SG_ 2172675330 IEB_VacSysDfctvSta "19.05.02";
BA_ "Description" SG_ 2172675330 IEB_InhbtTrnstnTo4wd_Req "ÀÌ ½ÅÈ£´Â 2WD ¸ðµå¿¡¼­ Á¦µ¿½Ã¿¡ 4WD ÀüÈ¯ ±ÝÁö¸¦ ¿äÃ»ÇÏ´Â ½ÅÈ£ÀÌ´Ù.";
BA_ "UserSigValidity" SG_ 2172675330 IEB_InhbtTrnstnTo4wd_Req 3;
BA_ "RoutingFactor" SG_ 2172675330 IEB_InhbtTrnstnTo4wd_Req 5;
BA_ "Version" SG_ 2172675330 IEB_InhbtTrnstnTo4wd_Req "19.05.03";
BA_ "Description" SG_ 2172675330 IEB_RegenTqLimitNmVal_Frnt "Regen Brake Torque limit at front wheel";
BA_ "UserSigValidity" SG_ 2172675330 IEB_RegenTqLimitNmVal_Frnt 3;
BA_ "RoutingFactor" SG_ 2172675330 IEB_RegenTqLimitNmVal_Frnt 5;
BA_ "Version" SG_ 2172675330 IEB_RegenTqLimitNmVal_Frnt "19.05.03";
BA_ "GenMsgSendType" BO_ 2172675331 0;
BA_ "GenMsgCycleTime" BO_ 2172675331 50;
BA_ "GenMsgCycleTimeFast" BO_ 2172675331 0;
BA_ "GenMsgNrOfRepetition" BO_ 2172675331 0;
BA_ "VFrameFormat" BO_ 2172675331 1;
BA_ "Description" SG_ 2172675331 IEB_RegenTqLimitNmVal_Rear "Regen Brake Torque limit at rear wheel";
BA_ "UserSigValidity" SG_ 2172675331 IEB_RegenTqLimitNmVal_Rear 3;
BA_ "RoutingFactor" SG_ 2172675331 IEB_RegenTqLimitNmVal_Rear 5;
BA_ "Version" SG_ 2172675331 IEB_RegenTqLimitNmVal_Rear "19.05.03";
BA_ "Description" SG_ 2172675331 IEB_DrvWhlSlipFlg_Frnt "This signal is to indicate the slip status of the driving wheels.";
BA_ "UserSigValidity" SG_ 2172675331 IEB_DrvWhlSlipFlg_Frnt 3;
BA_ "RoutingFactor" SG_ 2172675331 IEB_DrvWhlSlipFlg_Frnt 5;
BA_ "Version" SG_ 2172675331 IEB_DrvWhlSlipFlg_Frnt "20.10.02";
BA_ "Description" SG_ 2172675331 IEB_TCS_Req "ÀÌ ½ÅÈ£´Â IEB_01_10ms ¸Þ½ÃÁöÀÇ TCS ÅäÅ© ½ÅÈ£¿¡ ´ëÇÑ Validity¸¦ ÀÇ¹ÌÇÑ´Ù.



0x1 : TCS_TqIntrvntnVal_Frnt, TCS_TqIntrvntnVal_Rear ½ÅÈ£¿¡ ÀÇÇÑ TCS Á¦¾î

0x2 : TCS_MtrTrgtRpm_Frnt, TCS_MtrTrgtRpm_Rear ½ÅÈ£¿¡ ÀÇÇÑ TCS Á¦¾î";
BA_ "UserSigValidity" SG_ 2172675331 IEB_TCS_Req 3;
BA_ "RoutingFactor" SG_ 2172675331 IEB_TCS_Req 5;
BA_ "Version" SG_ 2172675331 IEB_TCS_Req "20.04.05";
BA_ "Description" SG_ 2172675331 IEB_RSC_Req "Validity of RSC torque signal from IEB_01_10ms";
BA_ "UserSigValidity" SG_ 2172675331 IEB_RSC_Req 3;
BA_ "RoutingFactor" SG_ 2172675331 IEB_RSC_Req 5;
BA_ "Version" SG_ 2172675331 IEB_RSC_Req "20.06.07";
BA_ "Description" SG_ 2172675331 TCS_TqFlag_Frnt "ÀÌ ½ÅÈ£´Â IEB_01_10ms ¸Þ½ÃÁöÀÇ TCS Àü·û ÅäÅ© ½ÅÈ£¿¡ ´ëÇÑ ºÎÈ£¸¦ ÀÇ¹ÌÇÑ´Ù.";
BA_ "UserSigValidity" SG_ 2172675331 TCS_TqFlag_Frnt 3;
BA_ "RoutingFactor" SG_ 2172675331 TCS_TqFlag_Frnt 5;
BA_ "Version" SG_ 2172675331 TCS_TqFlag_Frnt "19.05.03";
BA_ "Description" SG_ 2172675331 TCS_TqFlag_Rear "ÀÌ ½ÅÈ£´Â IEB_01_10ms ¸Þ½ÃÁöÀÇ TCS ÈÄ·û ÅäÅ© ½ÅÈ£¿¡ ´ëÇÑ ºÎÈ£¸¦ ÀÇ¹ÌÇÑ´Ù.";
BA_ "UserSigValidity" SG_ 2172675331 TCS_TqFlag_Rear 3;
BA_ "RoutingFactor" SG_ 2172675331 TCS_TqFlag_Rear 5;
BA_ "Version" SG_ 2172675331 TCS_TqFlag_Rear "19.05.03";
BA_ "Description" SG_ 2172675331 RSC_TqFlag_Frnt "ÀÌ ½ÅÈ£´Â IEB_01_10ms ¸Þ½ÃÁöÀÇ RSC Àü·û ÅäÅ© ½ÅÈ£¿¡ ´ëÇÑ ºÎÈ£¸¦ ÀÇ¹ÌÇÑ´Ù.";
BA_ "UserSigValidity" SG_ 2172675331 RSC_TqFlag_Frnt 3;
BA_ "RoutingFactor" SG_ 2172675331 RSC_TqFlag_Frnt 5;
BA_ "Version" SG_ 2172675331 RSC_TqFlag_Frnt "19.05.03";
BA_ "Description" SG_ 2172675331 RSC_TqFlag_Rear "ÀÌ ½ÅÈ£´Â IEB_01_10ms ¸Þ½ÃÁöÀÇ RSC ÈÄ·û ÅäÅ© ½ÅÈ£¿¡ ´ëÇÑ ºÎÈ£¸¦ ÀÇ¹ÌÇÑ´Ù.";
BA_ "UserSigValidity" SG_ 2172675331 RSC_TqFlag_Rear 3;
BA_ "RoutingFactor" SG_ 2172675331 RSC_TqFlag_Rear 5;
BA_ "Version" SG_ 2172675331 RSC_TqFlag_Rear "19.05.03";
BA_ "Description" SG_ 2172675331 TCS_TqIntrvntnVal_Frnt "TCS Á¦¾î¸¦ À§ÇÑ Àü·û ±¸µ¿ÅäÅ©ÀÇ ¿ä±¸°ªÀ» ÀÇ¹Ì.

ºÎÈ£´Â TCS_TqFlag_Frnt ½ÅÈ£¸¦ ÂüÁ¶.";
BA_ "UserSigValidity" SG_ 2172675331 TCS_TqIntrvntnVal_Frnt 3;
BA_ "RoutingFactor" SG_ 2172675331 TCS_TqIntrvntnVal_Frnt 5;
BA_ "Version" SG_ 2172675331 TCS_TqIntrvntnVal_Frnt "19.05.03";
BA_ "Description" SG_ 2172675331 TCS_TqIntrvntnVal_Rear "TCS Á¦¾î¸¦ À§ÇÑ ÈÄ·û ±¸µ¿ÅäÅ©ÀÇ ¿ä±¸°ªÀ» ÀÇ¹Ì.

ºÎÈ£´Â TCS_TqFlag_Rear ½ÅÈ£¸¦ ÂüÁ¶.";
BA_ "UserSigValidity" SG_ 2172675331 TCS_TqIntrvntnVal_Rear 3;
BA_ "RoutingFactor" SG_ 2172675331 TCS_TqIntrvntnVal_Rear 5;
BA_ "Version" SG_ 2172675331 TCS_TqIntrvntnVal_Rear "19.05.03";
BA_ "Description" SG_ 2172675331 RSC_TqIntrvntnVal_Frnt "RSC Á¦¾î¸¦ À§ÇÑ Àü·û ±¸µ¿ÅäÅ©ÀÇ ¿ä±¸°ªÀ» ÀÇ¹Ì.

ºÎÈ£´Â RSC_TqFlag_Frnt ½ÅÈ£¸¦ ÂüÁ¶.";
BA_ "UserSigValidity" SG_ 2172675331 RSC_TqIntrvntnVal_Frnt 3;
BA_ "RoutingFactor" SG_ 2172675331 RSC_TqIntrvntnVal_Frnt 5;
BA_ "Version" SG_ 2172675331 RSC_TqIntrvntnVal_Frnt "19.05.03";
BA_ "Description" SG_ 2172675331 RSC_TqIntrvntnVal_Rear "RSC Á¦¾î¸¦ À§ÇÑ ÈÄ·û ±¸µ¿ÅäÅ©ÀÇ ¿ä±¸°ªÀ» ÀÇ¹Ì.

ºÎÈ£´Â RSC_TqFlag_Rear ½ÅÈ£¸¦ ÂüÁ¶.";
BA_ "UserSigValidity" SG_ 2172675331 RSC_TqIntrvntnVal_Rear 3;
BA_ "RoutingFactor" SG_ 2172675331 RSC_TqIntrvntnVal_Rear 5;
BA_ "Version" SG_ 2172675331 RSC_TqIntrvntnVal_Rear "19.05.03";
BA_ "GenMsgSendType" BO_ 191 0;
BA_ "Description" SG_ 191 RL_SHVU_DTCdisplay "0x00: DTC is not exist(Fail is not exist)/0x01:IGN2 Fuse Open Detection/0x02:Switch Input Detection at Same Time/0x03:NTC/Heating wire Open Detection/0x04:NTC+/NTC- Terminal Short Detection/0x05:NTC+/Heater+ Terminal Short Detection/0x06:NTC+/Heater-, Heater+/Heater-, Heater+/NTC- Terminal Short Detection/0x07:NTC+/Heater- Wiring Short Detection/0x08:NTC+/Heater-, Heater+/Heater-, Heater+/NTC- Wiring Short Detection/0x09:Target Temperature Dissatisfied/0x0A:Blower+/Blower- Short, Blower+/Blower Speed, Blower-/Blower Speed Wiring Short Detection/0x0B:Blower+/Blower RPM, Blower-/Blower RPM, Blower Speed/Blower RPM Short Detection/0x0C:Blower+, Blower-, Blower Speed Signal open Detection/0x0D:Blower RPM signal Open Detection/0x0E~0xFD:Unused/0xFE:No Display/0xFF:Invalid";
BA_ "GenSigSendType" SG_ 191 RL_SHVU_DTCdisplay 4;
BA_ "UserSigValidity" SG_ 191 RL_SHVU_DTCdisplay 3;
BA_REL_ "GenSigTimeoutTime" BU_SG_REL_ ATS SG_ 191 RL_SHVU_DTCdisplay 1500;
BA_ "NetworkRequest" SG_ 191 RL_SHVU_DTCdisplay 0;
BA_ "NetworkRequestHoldingTime" SG_ 191 RL_SHVU_DTCdisplay 5000;
BA_ "Version" SG_ 191 RL_SHVU_DTCdisplay "19.12.08";
BA_ "Description" SG_ 191 RL_SHVU_DiagMode "0x0:Default/0x1:DTC Mode/0x2:Normal Mode/0x3:Invalid";
BA_ "GenSigSendType" SG_ 191 RL_SHVU_DiagMode 4;
BA_ "UserSigValidity" SG_ 191 RL_SHVU_DiagMode 3;
BA_REL_ "GenSigTimeoutTime" BU_SG_REL_ ATS SG_ 191 RL_SHVU_DiagMode 1500;
BA_ "NetworkRequest" SG_ 191 RL_SHVU_DiagMode 0;
BA_ "NetworkRequestHoldingTime" SG_ 191 RL_SHVU_DiagMode 5000;
BA_ "Version" SG_ 191 RL_SHVU_DiagMode "19.12.08";
BA_ "GenMsgSendType" BO_ 2328016129 0;
BA_ "GenMsgCycleTimeFast" BO_ 2328016129 0;
BA_ "GenMsgNrOfRepetition" BO_ 2328016129 0;
BA_ "VFrameFormat" BO_ 2328016129 1;
BA_ "Description" SG_ 2328016129 VCU_Crc5Val "The data area for CRC calculation is based on the data length (DLC) of the message DB.

The CRC shall be calculated over the entire data block (excluding the CRC bytes) including the user data, alive counter and Data ID

 

- CRC Polynomial (0x1021) , Initial Value : 0xFFFF, XOR value : 0x0000, Data ID : Message ID + 0xF800 

- The initial value is for CRC calculation and the message should be sent with the calculated result value. 

- The mathematical expression to 16 bit CRC polynomial is given here. G(x) = x16 + x12 + x5 + 1";
BA_ "GenSigStartValue" SG_ 2328016129 VCU_Crc5Val 65535;
BA_ "UserSigValidity" SG_ 2328016129 VCU_Crc5Val 7;
BA_ "RoutingFactor" SG_ 2328016129 VCU_Crc5Val 2;
BA_ "Version" SG_ 2328016129 VCU_Crc5Val "20.07.05";
BA_ "Description" SG_ 2328016129 VCU_AlvCnt5Val "For the first transmission request for a data element the counter shall be initialized with 0 and shall be incremented by 1 for every subsequent send request. 

When the counter reaches the maximum value(0xFF), then it shall restart with 0 for the next send request";
BA_ "UserSigValidity" SG_ 2328016129 VCU_AlvCnt5Val 7;
BA_ "RoutingFactor" SG_ 2328016129 VCU_AlvCnt5Val 2;
BA_ "Version" SG_ 2328016129 VCU_AlvCnt5Val "20.07.05";
BA_ "Description" SG_ 2328016129 VCU_EvDrvRdyCluDispSta "EV Drive Ready for Cluster Display Only";
BA_ "UserSigValidity" SG_ 2328016129 VCU_EvDrvRdyCluDispSta 7;
BA_REL_ "GenSigTimeoutTime" BU_SG_REL_ SWRC SG_ 2328016129 VCU_EvDrvRdyCluDispSta 1500;
BA_ "RoutingFactor" SG_ 2328016129 VCU_EvDrvRdyCluDispSta 2;
BA_ "Version" SG_ 2328016129 VCU_EvDrvRdyCluDispSta "19.09.05";
BA_ "Description" SG_ 2328016129 VCU_PwrDnModeSta "Power Down Mode";
BA_ "UserSigValidity" SG_ 2328016129 VCU_PwrDnModeSta 7;
BA_ "RoutingFactor" SG_ 2328016129 VCU_PwrDnModeSta 2;
BA_ "Version" SG_ 2328016129 VCU_PwrDnModeSta "19.03.03";
BA_ "Description" SG_ 2328016129 VCU_CluWarnMsgSta "Cluster Warning Message";
BA_ "UserSigValidity" SG_ 2328016129 VCU_CluWarnMsgSta 7;
BA_ "RoutingFactor" SG_ 2328016129 VCU_CluWarnMsgSta 2;
BA_ "Version" SG_ 2328016129 VCU_CluWarnMsgSta "19.03.03";
BA_ "Description" SG_ 2328016129 VCU_DteOffDispSta "DTE Off('---' Display)";
BA_ "UserSigValidity" SG_ 2328016129 VCU_DteOffDispSta 7;
BA_ "RoutingFactor" SG_ 2328016129 VCU_DteOffDispSta 2;
BA_ "Version" SG_ 2328016129 VCU_DteOffDispSta "19.06.02";
BA_ "Description" SG_ 2328016129 VCU_LowSocAlertSta "Low SOC Alert of High-Voltage Battery";
BA_ "UserSigValidity" SG_ 2328016129 VCU_LowSocAlertSta 7;
BA_ "RoutingFactor" SG_ 2328016129 VCU_LowSocAlertSta 2;
BA_ "Version" SG_ 2328016129 VCU_LowSocAlertSta "19.03.03";
BA_ "Description" SG_ 2328016129 VCU_VcrmReq "VCRM Trigger Signal(Request VCRM Data Logging)";
BA_ "UserSigValidity" SG_ 2328016129 VCU_VcrmReq 7;
BA_ "RoutingFactor" SG_ 2328016129 VCU_VcrmReq 2;
BA_ "Version" SG_ 2328016129 VCU_VcrmReq "19.03.03";
BA_ "UserSigValidity" SG_ 2328016129 VCU_PdlWarnMsgSta 7;
BA_ "RoutingFactor" SG_ 2328016129 VCU_PdlWarnMsgSta 2;
BA_ "Version" SG_ 2328016129 VCU_PdlWarnMsgSta "19.03.03";
BA_ "Description" SG_ 2328016129 VCU_AwdDiagDispSta "e4WD Diagnosis Display Status";
BA_ "UserSigValidity" SG_ 2328016129 VCU_AwdDiagDispSta 7;
BA_ "RoutingFactor" SG_ 2328016129 VCU_AwdDiagDispSta 2;
BA_ "Version" SG_ 2328016129 VCU_AwdDiagDispSta "20.01.00";
BA_ "Description" SG_ 2328016129 VCU_AwdLockDispSta "e4WD Lock Mode Display Status";
BA_ "UserSigValidity" SG_ 2328016129 VCU_AwdLockDispSta 7;
BA_ "RoutingFactor" SG_ 2328016129 VCU_AwdLockDispSta 2;
BA_ "Version" SG_ 2328016129 VCU_AwdLockDispSta "20.01.00";
BA_ "Description" SG_ 2328016129 VCU_VirtualApsActSta "Virtual APS Activated";
BA_ "UserSigValidity" SG_ 2328016129 VCU_VirtualApsActSta 7;
BA_ "RoutingFactor" SG_ 2328016129 VCU_VirtualApsActSta 2;
BA_ "Version" SG_ 2328016129 VCU_VirtualApsActSta "19.03.03";
BA_ "Description" SG_ 2328016129 VCU_VirtualApsVal "Estimated Accelerator Pedal Value when Auto Cruise Mode";
BA_ "UserSigValidity" SG_ 2328016129 VCU_VirtualApsVal 7;
BA_ "RoutingFactor" SG_ 2328016129 VCU_VirtualApsVal 2;
BA_ "Version" SG_ 2328016129 VCU_VirtualApsVal "19.03.03";
BA_ "Description" SG_ 2328016129 VCU_ServiceLampReq "Sevice Lamp Request";
BA_ "UserSigValidity" SG_ 2328016129 VCU_ServiceLampReq 7;
BA_ "RoutingFactor" SG_ 2328016129 VCU_ServiceLampReq 2;
BA_ "Version" SG_ 2328016129 VCU_ServiceLampReq "19.03.03";
BA_ "Description" SG_ 2328016129 VCU_ServiceModeSta "Service Mode";
BA_ "UserSigValidity" SG_ 2328016129 VCU_ServiceModeSta 7;
BA_ "RoutingFactor" SG_ 2328016129 VCU_ServiceModeSta 2;
BA_ "Version" SG_ 2328016129 VCU_ServiceModeSta "20.10.00";
BA_ "Description" SG_ 2328016129 VCU_NPosWshModSta "N Wash Mode Status";
BA_ "UserSigValidity" SG_ 2328016129 VCU_NPosWshModSta 7;
BA_ "RoutingFactor" SG_ 2328016129 VCU_NPosWshModSta 2;
BA_ "Version" SG_ 2328016129 VCU_NPosWshModSta "19.07.06";
BA_ "Description" SG_ 2328016129 VCU_PowerTrainType "VCU_PowerTrainType";
BA_ "UserSigValidity" SG_ 2328016129 VCU_PowerTrainType 7;
BA_ "RoutingFactor" SG_ 2328016129 VCU_PowerTrainType 2;
BA_ "Version" SG_ 2328016129 VCU_PowerTrainType "19.03.03";
BA_ "GenMsgSendType" BO_ 2328016130 0;
BA_ "GenMsgCycleTimeFast" BO_ 2328016130 0;
BA_ "GenMsgNrOfRepetition" BO_ 2328016130 0;
BA_ "VFrameFormat" BO_ 2328016130 1;
BA_ "Description" SG_ 2328016130 VCU_DteBaseVal "Maximum Drivable Distance_Adaption";
BA_ "UserSigValidity" SG_ 2328016130 VCU_DteBaseVal 7;
BA_ "RoutingFactor" SG_ 2328016130 VCU_DteBaseVal 2;
BA_ "Version" SG_ 2328016130 VCU_DteBaseVal "19.03.03";
BA_ "Description" SG_ 2328016130 VCU_AvnDteOnCalcSta "DTE calculation status";
BA_ "UserSigValidity" SG_ 2328016130 VCU_AvnDteOnCalcSta 7;
BA_ "RoutingFactor" SG_ 2328016130 VCU_AvnDteOnCalcSta 2;
BA_ "Version" SG_ 2328016130 VCU_AvnDteOnCalcSta "19.03.03";
BA_ "Description" SG_ 2328016130 VCU_SbwWarnMsgSta "SBW Warning Message";
BA_ "UserSigValidity" SG_ 2328016130 VCU_SbwWarnMsgSta 7;
BA_ "RoutingFactor" SG_ 2328016130 VCU_SbwWarnMsgSta 2;
BA_ "Version" SG_ 2328016130 VCU_SbwWarnMsgSta "19.06.02";
BA_ "Description" SG_ 2328016130 VCU_DteNaviRouteVal "Drivable distance for calculation AVN DTE";
BA_ "UserSigValidity" SG_ 2328016130 VCU_DteNaviRouteVal 7;
BA_ "RoutingFactor" SG_ 2328016130 VCU_DteNaviRouteVal 2;
BA_ "Version" SG_ 2328016130 VCU_DteNaviRouteVal "19.03.03";
BA_ "Description" SG_ 2328016130 VCU_DteAddVal "Added Drivable Distance by DATC Off";
BA_ "UserSigValidity" SG_ 2328016130 VCU_DteAddVal 7;
BA_ "RoutingFactor" SG_ 2328016130 VCU_DteAddVal 2;
BA_ "Version" SG_ 2328016130 VCU_DteAddVal "19.03.03";
BA_ "Description" SG_ 2328016130 VCU_PwrGaugeVal "Motor Torque Ratio To Cluster

:VCU send this signal to cluster to show motor power status";
BA_ "UserSigValidity" SG_ 2328016130 VCU_PwrGaugeVal 7;
BA_ "RoutingFactor" SG_ 2328016130 VCU_PwrGaugeVal 2;
BA_ "Version" SG_ 2328016130 VCU_PwrGaugeVal "19.03.03";
BA_ "Description" SG_ 2328016130 VCU_EnergyFlowSta "Energy Flow Display Status";
BA_ "UserSigValidity" SG_ 2328016130 VCU_EnergyFlowSta 7;
BA_ "RoutingFactor" SG_ 2328016130 VCU_EnergyFlowSta 2;
BA_ "Version" SG_ 2328016130 VCU_EnergyFlowSta "20.09.00";
BA_ "Description" SG_ 2328016130 VCU_SbwWarnSndSta "SBW Warning Sound";
BA_ "UserSigValidity" SG_ 2328016130 VCU_SbwWarnSndSta 7;
BA_ "RoutingFactor" SG_ 2328016130 VCU_SbwWarnSndSta 2;
BA_ "Version" SG_ 2328016130 VCU_SbwWarnSndSta "19.06.02";
BA_ "Description" SG_ 2328016130 VCU_EcoGuide_DispReq "Display On/Off";
BA_ "UserSigValidity" SG_ 2328016130 VCU_EcoGuide_DispReq 7;
BA_ "RoutingFactor" SG_ 2328016130 VCU_EcoGuide_DispReq 2;
BA_ "Version" SG_ 2328016130 VCU_EcoGuide_DispReq "19.03.03";
BA_ "Description" SG_ 2328016130 VCU_EcoGuide_ApsGaugeVal "APS Gauge Display for Smart ECO Guide";
BA_ "UserSigValidity" SG_ 2328016130 VCU_EcoGuide_ApsGaugeVal 7;
BA_ "RoutingFactor" SG_ 2328016130 VCU_EcoGuide_ApsGaugeVal 2;
BA_ "Version" SG_ 2328016130 VCU_EcoGuide_ApsGaugeVal "19.03.03";
BA_ "Description" SG_ 2328016130 VCU_EcoGuide_EcoGaugeVal "ECO Range Display for Smart ECO Guide";
BA_ "UserSigValidity" SG_ 2328016130 VCU_EcoGuide_EcoGaugeVal 7;
BA_ "RoutingFactor" SG_ 2328016130 VCU_EcoGuide_EcoGaugeVal 2;
BA_ "Version" SG_ 2328016130 VCU_EcoGuide_EcoGaugeVal "19.03.03";
BA_ "GenMsgSendType" BO_ 2328016131 0;
BA_ "GenMsgCycleTimeFast" BO_ 2328016131 0;
BA_ "GenMsgNrOfRepetition" BO_ 2328016131 0;
BA_ "VFrameFormat" BO_ 2328016131 1;
BA_ "Description" SG_ 2328016131 VCU_TgSocDteAcChgVal "Estimated DTE for slow charger(SC/AC) target SOC";
BA_ "UserSigValidity" SG_ 2328016131 VCU_TgSocDteAcChgVal 7;
BA_ "RoutingFactor" SG_ 2328016131 VCU_TgSocDteAcChgVal 2;
BA_ "Version" SG_ 2328016131 VCU_TgSocDteAcChgVal "19.03.03";
BA_ "Description" SG_ 2328016131 VCU_TgSocDteDcChgVal "Estimated DTE for fast charger(QC/DC) target SOC";
BA_ "UserSigValidity" SG_ 2328016131 VCU_TgSocDteDcChgVal 7;
BA_ "RoutingFactor" SG_ 2328016131 VCU_TgSocDteDcChgVal 2;
BA_ "Version" SG_ 2328016131 VCU_TgSocDteDcChgVal "19.03.03";
BA_ "Description" SG_ 2328016131 VCU_DistFromRegenDispReq "Distance from Regeneration Display status";
BA_ "UserSigValidity" SG_ 2328016131 VCU_DistFromRegenDispReq 7;
BA_ "RoutingFactor" SG_ 2328016131 VCU_DistFromRegenDispReq 2;
BA_ "Version" SG_ 2328016131 VCU_DistFromRegenDispReq "19.03.03";
BA_ "Description" SG_ 2328016131 VCU_DistFromRegenVal "DTE Increment at Regeneration";
BA_ "UserSigValidity" SG_ 2328016131 VCU_DistFromRegenVal 7;
BA_ "RoutingFactor" SG_ 2328016131 VCU_DistFromRegenVal 2;
BA_ "Version" SG_ 2328016131 VCU_DistFromRegenVal "19.03.03";
BA_ "Description" SG_ 2328016131 VCU_DrvStyle_DispReq "Fuel Efficiency Percent Display Status";
BA_ "UserSigValidity" SG_ 2328016131 VCU_DrvStyle_DispReq 7;
BA_ "RoutingFactor" SG_ 2328016131 VCU_DrvStyle_DispReq 2;
BA_ "Version" SG_ 2328016131 VCU_DrvStyle_DispReq "19.03.03";
BA_ "Description" SG_ 2328016131 VCU_DrvStyle_HighLightSta "Fuel Efficiency High Light Status";
BA_ "UserSigValidity" SG_ 2328016131 VCU_DrvStyle_HighLightSta 7;
BA_ "RoutingFactor" SG_ 2328016131 VCU_DrvStyle_HighLightSta 2;
BA_ "Version" SG_ 2328016131 VCU_DrvStyle_HighLightSta "19.03.03";
BA_ "Description" SG_ 2328016131 VCU_DrvStyle_EcoVal "High Fuel Efficiency Percent Value";
BA_ "UserSigValidity" SG_ 2328016131 VCU_DrvStyle_EcoVal 7;
BA_ "RoutingFactor" SG_ 2328016131 VCU_DrvStyle_EcoVal 2;
BA_ "Version" SG_ 2328016131 VCU_DrvStyle_EcoVal "19.03.03";
BA_ "Description" SG_ 2328016131 VCU_DrvStyle_NonEcoVal "Low Fuel Efficiency Percent Value";
BA_ "UserSigValidity" SG_ 2328016131 VCU_DrvStyle_NonEcoVal 7;
BA_ "RoutingFactor" SG_ 2328016131 VCU_DrvStyle_NonEcoVal 2;
BA_ "Version" SG_ 2328016131 VCU_DrvStyle_NonEcoVal "19.03.03";
BA_ "Description" SG_ 2328016131 VCU_DrvStyle_NorVal "Normal Fuel Efficiency Percent Value";
BA_ "UserSigValidity" SG_ 2328016131 VCU_DrvStyle_NorVal 7;
BA_ "RoutingFactor" SG_ 2328016131 VCU_DrvStyle_NorVal 2;
BA_ "Version" SG_ 2328016131 VCU_DrvStyle_NorVal "19.03.03";
BA_ "GenMsgSendType" BO_ 2328016132 0;
BA_ "GenMsgCycleTimeFast" BO_ 2328016132 0;
BA_ "GenMsgNrOfRepetition" BO_ 2328016132 0;
BA_ "VFrameFormat" BO_ 2328016132 1;
BA_ "Description" SG_ 2328016132 VCU_LowSocDispPcVal "Low SOC Display Percent Value";
BA_ "TimeoutValue" SG_ 2328016132 VCU_LowSocDispPcVal "0x0";
BA_ "UserSigValidity" SG_ 2328016132 VCU_LowSocDispPcVal 7;
BA_ "RoutingFactor" SG_ 2328016132 VCU_LowSocDispPcVal 2;
BA_ "Version" SG_ 2328016132 VCU_LowSocDispPcVal "21.03.00";
BA_ "Description" SG_ 2328016132 VCU_DteSocBasedVal "Maximum Drivable Distance with Soc Based (China Only Func)";
BA_ "UserSigValidity" SG_ 2328016132 VCU_DteSocBasedVal 7;
BA_ "RoutingFactor" SG_ 2328016132 VCU_DteSocBasedVal 2;
BA_ "Version" SG_ 2328016132 VCU_DteSocBasedVal "20.12.04";
BA_ "Description" SG_ 2328016132 VCU_InstFuelEcoVal_Per100km "Instant Fuel Economy(kWh/100km)";
BA_ "UserSigValidity" SG_ 2328016132 VCU_InstFuelEcoVal_Per100km 7;
BA_ "RoutingFactor" SG_ 2328016132 VCU_InstFuelEcoVal_Per100km 2;
BA_ "Version" SG_ 2328016132 VCU_InstFuelEcoVal_Per100km "19.03.03";
BA_ "Description" SG_ 2328016132 VCU_InstFuelEcoVal_PerkWh "Fuel Economy in EV";
BA_ "UserSigValidity" SG_ 2328016132 VCU_InstFuelEcoVal_PerkWh 7;
BA_ "RoutingFactor" SG_ 2328016132 VCU_InstFuelEcoVal_PerkWh 2;
BA_ "Version" SG_ 2328016132 VCU_InstFuelEcoVal_PerkWh "19.03.03";
BA_ "Description" SG_ 2328016132 VCU_CO2RdcTripDistVal "Trip Distance for CO2 Reduction";
BA_ "UserSigValidity" SG_ 2328016132 VCU_CO2RdcTripDistVal 7;
BA_ "RoutingFactor" SG_ 2328016132 VCU_CO2RdcTripDistVal 2;
BA_ "Version" SG_ 2328016132 VCU_CO2RdcTripDistVal "19.03.03";
BA_ "Description" SG_ 2328016132 VCU_CO2RdcVal "CO2 Reduction Amount(Integrated Value)";
BA_ "UserSigValidity" SG_ 2328016132 VCU_CO2RdcVal 7;
BA_ "RoutingFactor" SG_ 2328016132 VCU_CO2RdcVal 2;
BA_ "Version" SG_ 2328016132 VCU_CO2RdcVal "19.03.03";
BA_ "Description" SG_ 2328016132 VCU_StopCtrlWarnMsgSta "i-Pedal Warning Message Status";
BA_ "UserSigValidity" SG_ 2328016132 VCU_StopCtrlWarnMsgSta 7;
BA_ "RoutingFactor" SG_ 2328016132 VCU_StopCtrlWarnMsgSta 2;
BA_ "Version" SG_ 2328016132 VCU_StopCtrlWarnMsgSta "21.12.02";
BA_ "Description" SG_ 2328016132 VCU_DrvModeDefault "This signal is the drive mode that needs to return to default on initial strat-up and restart. 

This signal is only used for cluster display.";
BA_ "UserSigValidity" SG_ 2328016132 VCU_DrvModeDefault 7;
BA_ "RoutingFactor" SG_ 2328016132 VCU_DrvModeDefault 2;
BA_ "Version" SG_ 2328016132 VCU_DrvModeDefault "21.09.07";
BA_ "Description" SG_ 2328016132 VCU_DrvModeLast "This signal is the drive mode that needs to maintain on restart.This signal is only used for cluster display* If BitX is 1, the drive mode remains in the last mode on restart.* If BitX is 0, the drive mode returns to default mode on restart.";
BA_ "UserSigValidity" SG_ 2328016132 VCU_DrvModeLast 7;
BA_ "RoutingFactor" SG_ 2328016132 VCU_DrvModeLast 2;
BA_ "Version" SG_ 2328016132 VCU_DrvModeLast "21.09.07";
VAL_ 2227254529 BAT_Crc1Val 65535 "Signal Invalid (Message with unused CRC. CRC signal is transmitted fixed value)" ;
VAL_ 2227254529 BAT_AlvCnt1Val 255 "Signal Invalid (Message with unused Alive counter. Alive counter signal is transmitted fixed value)" ;
VAL_ 2227254529 BAT_CurrVal 65535 "Error indicator" ;
VAL_ 2227254529 BAT_SocVal 255 "Error indicator" ;
VAL_ 2227254529 BAT_VoltVal 16383 "Error indicator" ;
VAL_ 2227254530 BAT_TempVal 511 "Error indicator" ;
VAL_ 2227254530 BAT_SohVal 127 "Error indicator" ;
VAL_ 2227254530 BAT_SnsrInvldSta 0 "Valid Condition" 1 "Invalid Condition" 2 "Not used" 3 "Error indicator" ;
VAL_ 2227254530 BAT_SofVal 127 "Error indicator" ;
VAL_ 2227254530 BAT_RspErrSta 0 "Operating correctly" 1 "Response error" 2 "Not used" 3 "Error indicator" ;
VAL_ 2227254530 BAT_CapacityVal 255 "Error" ;
VAL_ 2227254530 BAT_SocErrSta 0 "Nomal State" 1 "Implausible State" 2 "Not used" 3 "Error indicator" ;
VAL_ 2315421697 CCU_OTA_mode 0 "idle" 1 "Download" 2 "BackgroundSend" 3 "UpdateReady_bf_apv" 4 "UpdateReady_af_apv" 5 "Update_preprocess" 6 "Update_PE" 7 "Update_other" ;
VAL_ 2315421697 CCU_OTA_IG3On_request 0 "off(Default)" 1 "on" 2 "Not used" 3 "Error Indicator" ;
VAL_ 2315421697 OTA_Cond_Vehicle_Pwr 0 "NoDisplay" 1 "OK" 2 "NOK" 3 "Reserved" ;
VAL_ 2315421697 OTA_Cond_Gear_P 0 "NoDisplay" 1 "OK" 2 "NOK" 3 "Reserved" ;
VAL_ 2315421697 OTA_Cond_Parking_Brk 0 "NoDisplay" 1 "OK" 2 "NOK" 3 "Reserved" ;
VAL_ 2315421697 OTA_Cond_Ext_Lamp 0 "NoDisplay" 1 "OK" 2 "NOK" 3 "Reserved" ;
VAL_ 2315421697 OTA_Cond_Hood_Closed 0 "NoDisplay" 1 "OK" 2 "NOK" 3 "Reserved" ;
VAL_ 2315421697 OTA_UI_Ready_request 0 "off (default)" 1 "ON" 2 "Not Used" 3 "Error Indicator" ;
VAL_ 2315421697 OTA_Result 0 "Default" 1 "Success" 2 "failed_rollback_complete" 3 "failed_rollback_failed" ;
VAL_ 2315421697 CF_AVN_InterAutoLockMode_Set2_Copy_1 0 "Default" 1 "Auto Mode" 2 "Lock Mode" 3 "Unlock Mode" 4 "Reserved" 5 "Reserved" 6 "Reserved" 7 "Invalid" ;
VAL_ 2315421697 CCU_OTA_EOU 0 "OFF" 1 "ON" 2 "Reserved" 3 "Invalid" ;
VAL_ 2470763009 USM_MdLmpClrSetReq 0 "Default" 1 "color 1" 2 "color 2" 3 "color 3" 4 "color 4" 5 "color 5" 6 "color 6" 7 "color 7" 8 "color 8" 9 "color 9" 10 "color 10" 11 "reserved" 12 "reserved" 13 "reserved" 14 "reserved" 15 "Invalid" ;
VAL_ 2470763009 USM_RrWiperRevSetReq 0 "Default" 1 "Rear Wiper(reverse) Off" 2 "Rear Wiper(reverse) On" 3 "Invalid" ;
VAL_ 2470763009 USM_RrStRemindSetReq 0 "Default" 1 "Off(Disable)" 2 "On(Enable)" 3 "Invalid" ;
VAL_ 2470763009 USM_RrWpcSetReq 0 "Default" 1 "Off(Disable)" 2 "On(Enable)" 3 "Invalid" ;
VAL_ 2470763009 USM_WpcSetReq 0 "Default" 1 "Off(Disable)" 2 "On(Enable)" 3 "Invalid" ;
VAL_ 2470763009 USM_SeqLmpSetReq 0 "Default" 1 "Off" 2 "On" 3 "Invalid" ;
VAL_ 2470763009 USM_UnlckWlcmSetReq 0 "Default Value" 1 "Off" 2 "On" 3 "Invalid" ;
VAL_ 2470763009 USM_SmrtWlcmSetReq 0 "Default Value" 1 "Off" 2 "On" 3 "Invalid" ;
VAL_ 2470763009 USM_UipSetReq 0 "Default(USM¹Ì±¸¼º)" 1 "Off(Disable)" 2 "On(Enable)" 3 "Invalid" ;
VAL_ 2470763009 USM_DigitalKeyEnblSetReq 0 "Default(¹Ì±¸¼º)" 1 "Disable" 2 "Enable" 3 "Invalid" ;
VAL_ 2470763009 USM_OwnerPhnRegSetReq 0 "Default(¹Ì±¸¼º)" 1 "Deleter" 2 "Register" 3 "Invalid" ;
VAL_ 2470763009 USM_NFCCard1RegSetReq 0 "Default(¹Ì±¸¼º)" 1 "Disable" 2 "Enable" 3 "Invalid" ;
VAL_ 2470763009 USM_NFCCard2RegSetReq 0 "Default(¹Ì±¸¼º)" 1 "Disable" 2 "Enable" 3 "Invalid" ;
VAL_ 2470763009 USM_ProcStpReq 0 "Default" 1 "StopReq" ;
VAL_ 2470763009 USM_PwrAutoOffTimeSetReq 0 "Default" 1 "Timer1" 2 "Timer2" 3 "Timer3" 4 "Timer4" 5 "Reserved" 6 "Reserved" 7 "Invalid" ;
VAL_ 2470763009 USM_RrStRemindSetReq_RestMode 0 "Default" 1 "Off(Disable)" 2 "On(Enable)" 3 "Invalid" 4 "Reserved" 5 "Reserved" 6 "Not Used" 7 "Error Indicator" ;
VAL_ 2470763009 USM_1stRrStRemindSetReq 0 "Default" 1 "Off(Disable)" 2 "On(Enable)" 3 "Invalid" ;
VAL_ 2231452929 DATC_PtcRlySta 0 "PTC OFF" 1 "PTC ON Lv1" 2 "PTC ON Lv1&2" 3 "PTC ON Lv1&2&3" 4 "Not used" 5 "Not used" 6 "Not used" 7 "Error Indicator" ;
VAL_ 2231452929 DATC_ManufacturerTyp 0 "FATC Type 0 (default)" 1 "FATC Type 1 (Doowon)" 2 "FATC Type 2 (Hanon)/0X3:FATC Type 3(DENSO)" 4 "Not used" 5 "Not used" 6 "Not used" 7 "Error Indicator" ;
VAL_ 2231452929 DATC_DatcPwmSts 0 "Default" 1 "PWM Off" 2 "PWM On" 3 "Error Indicator" ;
VAL_ 2231452929 DATC_AcnCompTyp 0 "Internal Compressor" 1 "External Compressor with Comp clutch" 2 "External Compressor without Comp clutch" 3 "Fixed Compressor" 4 "electrical Compressor" 6 "Not used" 7 "Error Indicator" ;
VAL_ 2231452929 DATC_EewpRpmLvlReq 0 "MAX A/C" 1 "LOW" 2 "MID" 3 "HIGH" 4 "Not used" 5 "Not used" 6 "Not used" 7 "Error Indicator" ;
VAL_ 2231452929 DATC_Cooldown 0 "Default" 1 "Initial" 2 "Cool down" 3 "Error Indicator" ;
VAL_ 2231452929 DATC_AcnReq 0 "A/C Non-Request" 1 "A/C Request" 2 "Not used" 3 "Error Indicator" ;
VAL_ 2231452929 DATC_BlwSta 0 "Blower Off" 1 "Blower On" 2 "Not used" 3 "Error Indicator" ;
VAL_ 2231452929 DATC_BlwMaxSta 0 "NOT Max blower speed" 1 "Max blower speed" 2 "Not used" 3 "Error Indicator" ;
VAL_ 2231452929 DATC_EngStrtReq 0 "Engine Not on Request" 1 "Engine Auto Start Request" 2 "Not used" 3 "Error Indicator" ;
VAL_ 2231452929 DATC_IsgInhbtReq 0 "ISG Inhibit Request Off" 1 "ISG Inhibit Request ON" 2 "Not used" 3 "Error Indicator" ;
VAL_ 2231452929 DATC_AcnCompOnReq 0 "A/C COMP Request Off" 1 "A/C COMP Request ON" 2 "Not used" 3 "Error Indicator" ;
VAL_ 2231452929 DATC_SrvLmpReq 0 "Off" 1 "Service Lamp On" 2 "Not used" 3 "Error Indicator" ;
VAL_ 2231452929 DATC_EcvFltSta 0 "Normal(No fault)" 1 "ECV Control Fault" 2 "Not used" 3 "Error Indicator" ;
VAL_ 2231452929 DATC_CalcAcnCompTqVal 254 "Not used" 255 "Error Indicator" ;
VAL_ 2231452930 DATC_AcnECompOpSta 0 "E-Compressor Not-Operation" 1 "E-Compressor Operation" 2 "Not used" 3 "Error Indicator" ;
VAL_ 2231452930 DATC_HVCompIntlkSta 0 "Disconnect" 1 "Connect" 2 "Not used" 3 "Error Indicator" ;
VAL_ 2231452930 DATC_HVIntDischrgLkReq 0 "Not Request" 1 "Request" 2 "Not used" 3 "Error Indicator" ;
VAL_ 2231452930 DATC_AcnECompMaxReqPwrVal 1023 "Error Indicator" ;
VAL_ 2231452930 DATC_AcnCompFltSta 0 "A/C E-Compressor Normal" 1 "A/C E-Compressor Fail" 2 "Not used" 3 "Error Indicator" ;
VAL_ 2231452930 DATC_AcnECompCnsmptPwrVal 1023 "Error Indicator" ;
VAL_ 2231452930 DATC_MainRlyOffReq 0 "Non-Request" 1 "Request" 2 "Not used" 3 "Error Indicator" ;
VAL_ 2231452930 DATC_MixDfgSelSta 0 "Battery FAN Non-on Request" 1 "Battery FAN On Request" 2 "Not used" 3 "Error Indicator" ;
VAL_ 2231452930 DATC_BattChlrVlvSta 0 "Dafault" 1 "Valve Off (OPEN)" 2 "Valve On (CLOSE)" 3 "Error Indicator" ;
VAL_ 2231452930 DATC_WaterPmpOnReq 0 "Engine Water Pump Non request" 1 "Engine Water Pump On request" 2 "Not used" 3 "Error Indicator" ;
VAL_ 2231452930 DATC_AcnECompSpdVal 65534 "Not used" 65535 "Error Indicator" ;
VAL_ 2231452930 DATC_AcnCompSlpModCodVal 0 "Normal" 1 "Thermistor open" 2 "Thermister short" 4 "Over torque stall" 8 "Short circuit current" 16 "Driver voltage" 32 "Current measuring" 64 "Max Temperature Gradient" 128 "Internal Error" 255 "Error" ;
VAL_ 2231452930 DATC_RrDfgOpSta 0 "Rear Defog Off" 1 "Rear Defog On" 2 "Not used" 3 "Error Indicator" ;
VAL_ 2231452930 DATC_AcnECompCANFltSta 0 "LOCAL CAN Normal" 1 "LOCAL CAN Fail" 2 "Not used" 3 "Error Indicator" ;
VAL_ 2231452931 DATC_AcnCompWaitCodVal 0 "Normal" 1 "Low_Voltage" 2 "High_Voltage" 4 "Over_Heat_Protection" 8 "Over_Loaded" 16 "Over_Current_Protection" 32 "Abnormal(not receiving)" 64 "Missed_Restart" ;
VAL_ 2231452931 DATC_RadFanReq_Duty 254 "EMS Wake Up Req" ;
VAL_ 2231452931 DATC_OutTempSnsrVal 255 "Error" ;
VAL_ 2231452931 DATC_ActvEco 0 "Active ECO Button is not selected" 1 "Active ECO Button is selected" 2 "Not used" 3 "Error Indicator" ;
VAL_ 2231452931 DATC_AUTOActv 0 "Default" 1 "Automatic control is Active" 2 "Not used" 3 "Error Indicator" ;
VAL_ 2231452931 DATC_DfgSw 0 "FRONT DEF switch is not selected" 1 "FRONT DEF switch is selected" 2 "Not Used" 3 "Error Indicator" ;
VAL_ 2231452931 DATC_BattChlrVlv_FltCode 0 "Dafault" 1 "No Error" 2 "Error" 3 "Error Indicator" ;
VAL_ 2231452931 DATC_BattEvapVlvSta 0 "Default" 1 "Valve Off (OPEN)" 2 "Valve On (CLOSE)" 3 "Error Indicator" ;
VAL_ 2231452931 DATC_BattEvapVlv_FltCode 0 "Default" 1 "No Error" 2 "Error" 3 "Error Indicator" ;
VAL_ 2231452931 DATC_Wrmup 0 "Default" 1 "Initial" 2 "Warm Up" 3 "Error Indicator" ;
VAL_ 2231452931 DATC_SSC_EngStrtReq 0 "Normal (Default)" 1 "Engine Auto Start Request" 2 "Reserved" 3 "Error Indicator" ;
VAL_ 2231452931 DATC_AcnCompSta 1 "Initialize Mode" 2 "Standby Mode" 4 "Wait Mode" 8 "Sleep Mode" 16 "Operating Mode" 255 "Error" ;
VAL_ 2231452932 DATC_SSC_InhbtReq 0 "Normal (Default)" 1 "Inhibit Engine Stop" 2 "Reserved" 3 "Error Indicator" ;
VAL_ 2231452932 DATC_EngIdlRpmUpReq 0 "Off" 1 "A/C Off request" 2 "A/C On request" 3 "A/C On and Engine Speed 1 stage up request" 4 "A/C On and Engine Speed 2 stage up request" 5 "Warmup_Idle RPM_Up" 6 "Reserved" 7 "Error Indicator" ;
VAL_ 2231452932 DATC_MaxBlwVolt 0 "Default" 1 "OFF" 2 "ON (B+)" 3 "Error Indicator" ;
VAL_ 2231452932 DATC_HVACPmpOpSta 0 "Default" 1 "Pump Not Operation" 2 "Pump Operation" 3 "Error Indicator" ;
VAL_ 2231452932 DATC_MildCooldown 0 "Default" 1 "Initial State" 2 "Mild Cooldown" 3 "Error Indicator" ;
VAL_ 2231452932 DATC_MildWrmup 0 "Default" 1 "Initial" 2 "Mild Warm Up" 3 "Error Indicator" ;
VAL_ 2231452932 DATC_BlwrLvl 0 "OFF" 1 "0 level" 2 "1 level" 3 "2 level" 4 "3 level" 5 "4 level" 6 "5 level" 7 "6 level" 8 "7 evel" 9 "8 level" 10 "Reserved" 11 "Reserved" 12 "Reserved" 13 "Reserved" 14 "Reserved" 15 "Error Indicator" ;
VAL_ 2231452932 DATC_AAFOpenReq 0 "Default" 1 "1 st" 2 "2 nd" 3 "Open" 4 "Reserved" 5 "Reserved" 6 "Reserved" 7 "Error indicator" ;
VAL_ 2231452932 DATC_BattEwpOpReq 255 "Error Indicator" ;
VAL_ 649 DLBCU_SmartCtrl_1h 0 "Default" 1 "Group1" 2 "Group2" 3 "Group3" 4 "Group4" 5 "Group5" 6 "Group6" 7 "Group7" 8 "Group8" 9 "Group9" 10 "General Group" 11 "Unused" 12 "Unused" 13 "Unused" 14 "Unused" 15 "Invalid" ;
VAL_ 649 DLBCU_SmartCtrl_2h 0 "Default" 1 "Group1" 2 "Group2" 3 "Group3" 4 "Group4" 5 "Group5" 6 "Group6" 7 "Group7" 8 "Group8" 9 "Group9" 10 "General Group" 11 "Unused" 12 "Unused" 13 "Unused" 14 "Unused" 15 "Invalid" ;
VAL_ 649 DLBCU_SmartCtrl_Status 0 "Default" 1 "Start" 2 "Finished" 3 "Stop" 4 "Unused" 5 "Unused" 6 "Unused" 7 "Invalid" ;
VAL_ 1159 C_AstRclBwdSw_HU 0 "Default" 1 "Off" 2 "On" 3 "Invalid" ;
VAL_ 1159 C_AstHeightUpSw_HU 0 "Default" 1 "Off" 2 "On" 3 "Invalid" ;
VAL_ 1159 C_AstTiltDnSw_HU 0 "Default" 1 "Off" 2 "On" 3 "Invalid" ;
VAL_ 1159 C_AstTiltUpSw_HU 0 "Default" 1 "Off" 2 "On" 3 "Invalid" ;
VAL_ 1159 C_AstLumbarDefSw_HU 0 "Default" 1 "Off" 2 "On" 3 "Invalid" ;
VAL_ 1159 C_AstLumbarLowSw_HU 0 "Default" 1 "Off" 2 "On" 3 "Invalid" ;
VAL_ 1159 C_AstRclFwdSw_HU 0 "Default" 1 "Off" 2 "On" 3 "Invalid" ;
VAL_ 1159 C_AstLumbarMidSw_HU 0 "Default" 1 "Off" 2 "On" 3 "Invalid" ;
VAL_ 1159 C_AstLumbarUpSw_HU 0 "Default" 1 "Off" 2 "On" 3 "Invalid" ;
VAL_ 1159 C_RRSlideFwdSw_HU 0 "Default" 1 "Off" 2 "On" 3 "Invalid" ;
VAL_ 1159 C_RRSlideBwdSw_HU 0 "Default" 1 "Off" 2 "On" 3 "Invalid" ;
VAL_ 1159 C_RLSlideFwdSw_HU 0 "Default" 1 "Off" 2 "On" 3 "Invalid" ;
VAL_ 1159 C_RLSlideBwdSw_HU 0 "Default" 1 "Off" 2 "On" 3 "Invalid" ;
VAL_ 1159 C_AstSlideBwdSw_HU 0 "Default" 1 "Off" 2 "On" 3 "Invalid" ;
VAL_ 1159 C_AstSlideFwdSw_HU 0 "Default" 1 "Off" 2 "On" 3 "Invalid" ;
VAL_ 1159 C_AstHeightDnSw_HU 0 "Default" 1 "Off" 2 "On" 3 "Invalid" ;
VAL_ 197 C_DrvRclBwdSw_HU 0 "Default" 1 "Off" 2 "On" 3 "Invalid" ;
VAL_ 197 C_DrvSlideFwdSw_HU 0 "Default" 1 "Off" 2 "On" 3 "Invalid" ;
VAL_ 197 C_RLLegSupFwdSw_HU 0 "Default" 1 "Off" 2 "On" 3 "Invalid" ;
VAL_ 197 C_RLLegSupBwdSw_HU 0 "Default" 1 "Off" 2 "On" 3 "Invalid" ;
VAL_ 197 C_DrvSlideBwdSw_HU 0 "Default" 1 "Off" 2 "On" 3 "Invalid" ;
VAL_ 197 C_RLLegSupUpSw_HU 0 "Default" 1 "Off" 2 "On" 3 "Invalid" ;
VAL_ 197 C_RLLegSupDnSw_HU 0 "Default" 1 "Off" 2 "On" 3 "Invalid" ;
VAL_ 197 C_DrvRclFwdSw_HU 0 "Default" 1 "Off" 2 "On" 3 "Invalid" ;
VAL_ 172 BLTN_CAM_FR_VerPos_NvalueSet 0 "Mid" 1 "Upper Level (1 ~ 10)" 2 "Upper Level (1 ~ 10)" 3 "Upper Level (1 ~ 10)" 4 "Upper Level (1 ~ 10)" 5 "Upper Level (1 ~ 10)" 6 "Upper Level (1 ~ 10)" 7 "Upper Level (1 ~ 10)" 8 "Upper Level (1 ~ 10)" 9 "Upper Level (1 ~ 10)" 10 "Upper Level (1 ~ 10)" 10 "Reserved" 11 "Reserved" 12 "Reserved" 13 "Reserved" 14 "Reserved" 15 "Reserved" 16 "Reserved" 17 "Lower Level (-1 ~ -10)" 18 "Lower Level (-1 ~ -10)" 19 "Lower Level (-1 ~ -10)" 20 "Lower Level (-1 ~ -10)" 21 "Lower Level (-1 ~ -10)" 22 "Lower Level (-1 ~ -10)" 23 "Lower Level (-1 ~ -10)" 24 "Lower Level (-1 ~ -10)" 25 "Lower Level (-1 ~ -10)" 26 "Lower Level (-1 ~ -10)" 27 "Reserved" 28 "Reserved" 29 "Reserved" 30 "Reserved" 31 "Invalid" ;
VAL_ 172 BLTN_CAM_AppNoti_PEV_NvalueSet 0 "Default" 1 "Off" 2 "On" 3 "Invalid" ;
VAL_ 172 BLTN_CAM_WiFi_AutoOn_NvalueSet 0 "Default" 1 "Off" 2 "On" 3 "Invalid" ;
VAL_ 172 BLTN_CAM_StoProp_NvalueSet 0 "Normal" 1 "On While Recordings" 2 "On While Parked" 3 "Driving Events" 4 "Parked Events" 5 "Reserved" 6 "Reserved" 7 "Reserved" 8 "Reserved" 9 "Reserved" 10 "Reserved" 11 "Reserved" 12 "Reserved" 13 "Reserved" 14 "Reserved" 15 "Invalid" ;
VAL_ 172 CF_AVN_BLTN_CAM_USMReset 0 "Default" 1 "Built-in CAM USM Reset" 2 "Reserved" 3 "Invalid" ;
VAL_ 172 CF_AVN_BLTN_CAM_RecReset 0 "Default" 1 "Record Data Reset(format)" 2 "Reserved" 3 "Invalid" ;
VAL_ 172 BLTN_CAM_File_DEL_CPY_Cmd 0 "Default" 1 "Pause the operation" 2 "Cancel the operation" 3 "Continue operation" 4 "Reserved" 5 "Reserved" 6 "Reserved" 7 "Reserved" 8 "Reserved" 9 "Reserved" 10 "Reserved" 11 "Reserved" 12 "Reserved" 13 "Reserved" 14 "Reserved" 15 "Invalid" ;
VAL_ 172 BLTN_CAM_LVDS_Mode_Cmd 0 "Front and Rear Camera" 1 "Front Camera for AR Navi." 2 "Built-In Cam Engineer Mode" 3 "Reserved" ;
VAL_ 172 HU_BLTN_CAM_Disp_Touch_Pos_X 0 "0x0x0~0x77F:X position of the touch(Pixel)" 1919 "0x0x0~0x77F:X position of the touch(Pixel)" 2046 "Default" 2047 "Invalid" ;
VAL_ 172 HU_BLTN_CAM_Disp_Touch_Pos_Y 0 "0x0x0~0x3FD:Y position of the touch(Pixel)" 1021 "0x0x0~0x3FD:Y position of the touch(Pixel)" 1022 "Default" 1023 "Invalid" ;
VAL_ 172 BLTN_CAM_RR_VerPos_NvalueSet 0 "Mid" 1 "Upper Level (1 ~ 10)" 2 "Upper Level (1 ~ 10)" 3 "Upper Level (1 ~ 10)" 4 "Upper Level (1 ~ 10)" 5 "Upper Level (1 ~ 10)" 6 "Upper Level (1 ~ 10)" 7 "Upper Level (1 ~ 10)" 8 "Upper Level (1 ~ 10)" 9 "Upper Level (1 ~ 10)" 10 "Upper Level (1 ~ 10)" 10 "Reserved" 11 "Reserved" 12 "Reserved" 13 "Reserved" 14 "Reserved" 15 "Reserved" 16 "Reserved" 17 "Lower Level (-1 ~ -10)" 18 "Lower Level (-1 ~ -10)" 19 "Lower Level (-1 ~ -10)" 20 "Lower Level (-1 ~ -10)" 21 "Lower Level (-1 ~ -10)" 22 "Lower Level (-1 ~ -10)" 23 "Lower Level (-1 ~ -10)" 24 "Lower Level (-1 ~ -10)" 25 "Lower Level (-1 ~ -10)" 26 "Lower Level (-1 ~ -10)" 27 "Reserved" 28 "Reserved" 29 "Reserved" 30 "Reserved" 31 "Invalid" ;
VAL_ 1264 HU_TimeSetting 0 "not used" 1 "User Time" 2 "GPS Time" 3 "invalid" ;
VAL_ 1264 HU_DisplayMinute 0 "0 minute" 59 "59 Minute" 255 "invalid" ;
VAL_ 1264 HU_Status 0 "not used" 1 "Booting Head Unit" 2 "GPS receiving" 3 "Setting Mode" 4 "GPS Unavailable Mode" 5 "No GPS" 15 "invalid" ;
VAL_ 1264 HU_DisplaySecond 0 "0 minute" 59 "59 second" 255 "invalid" ;
VAL_ 1264 HU_DisplayMonth 0 "not used" 1 "1 month" 12 "12 month" 15 "invalid" ;
VAL_ 1264 HU_DisplayYear1 0 "19" 1 "20" 2 "21" 3 "invalid" ;
VAL_ 1264 HU_DisplayYear2 0 "0 year" 99 "99 year" 255 "invalid" ;
VAL_ 1264 HU_DisplayDay 0 "not used" 1 "1 day" 31 "31 day" 255 "invalid" ;
VAL_ 1264 HU_AM_PM_INFO 0 "Not Used" 1 "AM" 2 "PM" 3 "invalid" ;
VAL_ 1264 HU_TimeFormat 0 "Not used" 1 "12Hour" 2 "24Hour" 3 "invalid" ;
VAL_ 1264 HU_ComRefresh 0 "Not Used" 1 "Internal Clock None" 2 "Internal Clock Exist" 3 "Invalid" ;
VAL_ 1264 HU_ClockInfo 0 "Not Used" 1 "ACLOCK Refresh" 2 "Not Used" 3 "invalid" ;
VAL_ 1264 HU_DisplayHour 0 "0 Hour" 23 "23 Hour" 255 "invalid" ;
VAL_ 1266 HU_LanguageInfo 0 "Off" 1 "Korea" 2 "English(US)" 3 "English(UK)" 4 "Simplified chinese" 5 "Traditional chinese" 6 "French(EU)" 7 "Spanish(EU)" 8 "Arabic" 9 "Czech" 10 "Danish" 11 "German" 12 "Italian" 13 "Dutch" 14 "Polish" 15 "Portuguese" 16 "Russain" 17 "Slovak" 18 "Swedish" 19 "Turkish" 20 "French(US)" 21 "Spanish(US)" 22 "English(India)" 23 "Norwegian" 24 "Finnish" 25 "Indonesian" 26 "Brazilian Portuguese" 27 "Malay" 28 "Hungarian" 29 "English (Australia)" 30 "Japanese" 31 "Hindi" 32 "Hebrew" 33 "Greek" 34 "Ukrainian" 35 "Slovenian" 36 "Bulgarian" 37 "Croatian" 38 "Romanian" 39 "Bengali" 40 "Marathi" 41 "Telugu" 42 "Tamil" 43 "Gujarati" 44 "Kannada" 45 "Odia" 46 "Malayalam" 47 "Punjabi" 48 "Thai" 49 "Tagalog" 50 "Vietnamese" 51 "0x33~0xFE:Reserved" 254 "0x33~0xFE:Reserved" 255 "Invalid" ;
VAL_ 1266 HU_MuteStatus 0 "Off" 1 "Mute On" 2 "reserved" 3 "Invalid" ;
VAL_ 1266 HU_WelcomeReady 0 "Default" 1 "Ready" 2 "Reserved" 3 "Invalid" ;
VAL_ 1266 HU_UsmSupport 0 "Not support" 1 "Support" 2 "reserved" 3 "Invalid" ;
VAL_ 1266 HU_NaviStatus 0 "Booting" 1 "Normal Operation" 2 "No SD Card(Map)" 3 "Invalid" ;
VAL_ 1266 HU_NaviDisp 0 "Non_Navi" 1 "Navi" 2 "reserved" 3 "Invalid" ;
VAL_ 1266 HU_BVM_Display_Message 0 "Not Used" 1 "No Message" 2 "Rain_Warning Message" 3 "Reserved" 4 "Reserved" 5 "Reserved" 6 "Reserved" 7 "Invalid" ;
VAL_ 1266 HU_SVM_View_Display 0 "Not Used" 1 "AVM Display View OFF" 31 "Invalid" 2 "AVM Display View ON(LH)" 3 "AVM Display View ON(RH)" 4 "Reserved" 5 "Reserved" 6 "Reserved" 7 "Reserved" 8 "Reserved" 9 "Reserved" 10 "Reserved" 11 "Reserved" 12 "Reserved" 13 "Reserved" 14 "Reserved" 15 "Reserved" 16 "Reserved" 17 "Reserved" 18 "Reserved" 19 "Reserved" 20 "Reserved" 21 "Reserved" 22 "Reserved" 23 "Reserved" 24 "Reserved" 25 "Reserved" 26 "Reserved" 27 "Reserved" 28 "Reserved" 29 "Reserved" 30 "Reserved" ;
VAL_ 1266 HU_NaviCamSettingStatus 0 "Navi Camera Alert Setting Status" 1 "Navi Camera Alert Setting Status" 2 "Navi Camera Alert Setting Status" 3 "Navi Camera Alert Setting Status" 4 "Navi Camera Alert Setting Status" 5 "Navi Camera Alert Setting Status" 6 "Navi Camera Alert Setting Status" 7 "Navi Camera Alert Setting Status" 8 "Navi Camera Alert Setting Status" 9 "Navi Camera Alert Setting Status" 10 "Navi Camera Alert Setting Status" 11 "Navi Camera Alert Setting Status" 12 "Navi Camera Alert Setting Status" 13 "Navi Camera Alert Setting Status" 14 "Navi Camera Alert Setting Status" 15 "Navi Camera Alert Setting Status" 16 "Navi Camera Alert Setting Status" 17 "Navi Camera Alert Setting Status" 18 "Navi Camera Alert Setting Status" 19 "Navi Camera Alert Setting Status" 20 "Navi Camera Alert Setting Status" 21 "Navi Camera Alert Setting Status" 22 "Navi Camera Alert Setting Status" 23 "Navi Camera Alert Setting Status" 24 "Navi Camera Alert Setting Status" 25 "Navi Camera Alert Setting Status" 26 "Navi Camera Alert Setting Status" 27 "Navi Camera Alert Setting Status" 28 "Navi Camera Alert Setting Status" 29 "Navi Camera Alert Setting Status" 30 "Navi Camera Alert Setting Status" 31 "Navi Camera Alert Setting Status" 32 "0x20~0xFE:Reserved" 254 "0x20~0xFE:Reserved" 255 "Invalid" ;
VAL_ 1266 HU_EVSupport 0 "Not support" 1 "Support" 2 "Reserved" 3 "Invalid" ;
VAL_ 1266 HU_DayNightState 0 "Default" 1 "Day" 2 "Night" 3 "Invalid" ;
VAL_ 1266 HU_AutoBrightState_New 0 "Default" 1 "0x1~0x3FE:Brightness" 1022 "0x1~0x3FE:Brightness" 1023 "Invalid" ;
VAL_ 1266 HU_VolumeStatus 63 "Invalid" ;
VAL_ 1267 RSELockOnOff 0 "Unlock" 1 "LockOn" 2 "Reserved" 3 "Invalid" ;
VAL_ 1267 HU_DATC_RearLockSet 0 "Not Used" 1 "Rear Lock Off" 2 "Rear Lock On" 3 "Invalid" ;
VAL_ 1267 HU_Graphreset_Info 0 "No Action" 1 "Clear Request" 2 "Reserved" 3 "Invalid" ;
VAL_ 1267 HU_PhoneActivity 0 "Deactivated" 1 "Activated" 2 "reserved" 3 "Invalid" ;
VAL_ 1267 HU_VRActivity 0 "Deactivated" 1 "Activated" 2 "reserved" 3 "Invalid" ;
VAL_ 1267 HU_DATC_AirQuality_Info 0 "No information" 1 "level 1" 2 "level 2" 3 "level 3" 4 "level 4" 5 "level 5" 6 "level 6" 7 "reserved" 8 "reserved" 9 "reserved" 10 "reserved" 11 "reserved" 12 "reserved" 13 "reserved" 14 "reserved" 15 "invalid" ;
VAL_ 1265 HU_IG3_Request 0 "Off" 1 "On" 2 "Reserved" 3 "Invalid" ;
VAL_ 1265 HU_TeleVehicleStatusReq 0 "Do not Request" 1 "Request" 2 "reserved" 3 "Invalid" ;
VAL_ 1265 HU_Background 0 "Default" 1 "Day" 2 "Night" 3 "Reserved" 4 "Reserved" 5 "Reserved" 6 "Reserved" 7 "Invalid" ;
VAL_ 1265 ccIC_HUD_PbackSta 0 "Stop" 1 "Play 1" 2 "Play 2" 3 "Health Care IMS" 4 "Profile 1" 5 "Profile 2" 6 "Guest" 7 "Invalid" ;
VAL_ 1265 HU_BackgroundFadeInOut 0 "0x0x0~0x3E8:0.0~100.0%" 1000 "0x0x0~0x3E8:0.0~100.0%" 1001 "Reserved" 1002 "Reserved" 1003 "Reserved" 1004 "Reserved" 1005 "Reserved" 1006 "Reserved" 1007 "Reserved" 1008 "Reserved" 1009 "Reserved" 1010 "Reserved" 1011 "Reserved" 1012 "Reserved" 1013 "Reserved" 1014 "Reserved" 1015 "Reserved" 1016 "Reserved" 1017 "Reserved" 1018 "Reserved" 1019 "Reserved" 1020 "Reserved" 1021 "Reserved" 1022 "Default" 1023 "Invalid" ;
VAL_ 1265 CF_AVN_AutoWashModeSta 0 "Default" 1 "Non Auto Wash Mode" 2 "Auto Wash Mode" 3 "RESERVED" 4 "RESERVED" 5 "RESERVED" 6 "RESERVED" 7 "Invalid" ;
VAL_ 1278 HU_Type 16 "AVN(Tuner DVD KOR)" 17 "AVN(Tuner DVD EUR)" 18 "AVN(Tuner DVD China)" 19 "AVN(Tuner DVD Japan)" 20 "AVN(Tuner DVD EUR)" 21 "AVN(Tuner CDP KOR)" 22 "AVN(Tuner CDP EUR)" 23 "AVN(Tuner CDP China)" 24 "AVN(Tuner CDP Japan)" 25 "AVN(Tuner CDP EUR)" 32 "AVNT (Open)" 33 "AVNT (Not open)" 48 "Economic Audio" 64 "Standard Audio (3.0 below)" 65 "Standard Audio 4.0" 66 "STD Audio-3.0Below,No interwork" 67 "Audio 4.0 Value" 80 "AV(Tuner DVD KOR)" 81 "AV(Tuner DVD EUR)" 82 "AV(Tuner DVD China)" 83 "AV(Tuner DVD Japan)" 84 "AV(Tuner DVD EUR)" 85 "AV(Tuner CDP KOR)" 86 "AV(Tuner CDP EUR)" 87 "AV(Tuner CDP China)" 88 "AV(Tuner CDP Japan)" 89 "AV(Tuner CDP EUR)" 96 "AVN 4.0" 97 "Premium AVN2.0" 98 "EU AVN 2.0" 99 "Super Premium w Navi" 100 "Super Premium w_o Navi" 101 "Premium w Navi" 102 "Premium w_o Navi" 103 "Display Audio w_o Navi" 104 "Integrated AVN 1.0 Mobis" 105 "Gen5 Standard Nav Wide" 112 "Compact AVN & Integrated AVN 1.0 LG" 113 "Standard-class Gen6 Navigation" 128 "Premium Navi 5th Gen(w_Navi)" 129 "Premium Navi 5th Gen(w_o Navi)" 130 "Premium Navi 6th Gen(w_Navi)" 131 "Premium Navi 6th Gen(w_o Navi)" 132 "ccNC(w Navi)" 133 "ccNC(w_o Navi)" 134 "ccIC(w Navi)" 135 "ccIC(w_o Navi)" 238 "India PIO w_o CLU interface" 239 "India PIO w_CLU interface" 241 "Gen 1 China OEM Navigation" 250 "PIO AVN" 251 "China  Local OEM Display Audio" 252 "China OPIO w_o CLU interface" 253 "China OPIO w_CLU interface" 254 "China Local OEM AVNT" 255 "Invalid" ;
VAL_ 1278 HU_DistributeInfo 0 "Default (Korea)" 1 "Korea" 2 "North America" 3 "Canada" 4 "East Europe" 5 "West Europe" 6 "China" 7 "India" 8 "Australia" 9 "Middle East" 10 "Africa" 11 "South America" 12 "Russia" 13 "Japan" 14 "General" 15 "0x0F~0xFE:Reserved" 254 "0x0F~0xFE:Reserved" 255 "Invalid" ;
VAL_ 1278 HU_OptionInfo 32768 "Invalid" ;
VAL_ 1278 HU_NaviMapInfo 0 "Unknown" 1 "Korea" 2 "North America" 3 "Europe" 4 "Middle East" 5 "Australia" 6 "South America" 7 "China" 8 "Russia" 9 "Turkey" 10 "India" 11 "Japan" 15 "Invalid" ;
VAL_ 1278 HU_NaviHandshakingSupport 0 "Not Support" 1 "Support" 2 "Unknown" 3 "Invalid" ;
VAL_ 1278 HU_AMP_EQVariant 0 "Default" 1 "WGN" 2 "WGN PHEV" 3 "5DR" 4 "SB" 5 "CUV" 6 "HEV" 7 "PHEV" 8 "EV" 9 "Reserved" 10 "Reserved" 11 "Reserved" 12 "Reserved" 13 "Reserved" 14 "Reserved" 15 "Reserved" 16 "Reserved" 17 "Reserved" 18 "Reserved" 19 "Reserved" 20 "Reserved" 21 "Reserved" 22 "Reserved" 23 "Reserved" 24 "Reserved" 25 "Reserved" 26 "Reserved" 27 "Reserved" 28 "Reserved" 29 "Reserved" 30 "Reserved" ;
VAL_ 1278 HU_AdasSupport 0 "Not Support" 1 "ADAS Support(General Map)" 2 "ADAS Support(Map based ADAS v1)" 3 "ADAS Support(Map based ADAS v2)" 4 "ADAS Support(Map based ADAS v2 & Handshaking)" 5 "ADAS Support(Map based ADAS v2_3)" 6 "Reserved" 7 "Invalid" ;
VAL_ 1278 HU_Navi_RspADASMapMsg 0 "0x0x0~0xFFFF:Refer to Signal Description" 65535 "0x0x0~0xFFFF:Refer to Signal Description" ;
VAL_ 1279 USM_SmartRegen_Map_Set 0 "Default" 1 "Off(Disbaled)" 2 "On(Enabled)" 3 "Invalid" ;
VAL_ 1279 USM_SmartRegen_Sens_Set 0 "Default" 1 "Slow" 2 "Normal" 3 "Fast" 4 "Reserved" 5 "Reserved" 6 "Reserved" 7 "Invalid" ;
VAL_ 1279 AVN_SeatPosMemory_Btn 0 "Default" 1 "Memory 1" 2 "Memory 2" 3 "Memory 3" 4 "Reserved" 5 "Reserved" 6 "Reserved" 7 "Invalid" ;
VAL_ 1279 AVN_SeatPosPlyBck_Btn 0 "Default" 1 "Memory 1" 2 "Memory 2" 3 "Memory 3" 4 "Reserved" 5 "Reserved" 6 "Stop" 7 "Invalid" ;
VAL_ 1279 USM_RhstaLvlEnaSetReq 0 "Default" 1 "Off" 2 "On" 3 "Invalid" ;
VAL_ 1279 USM_CMSDayBrgtnsLvlLHSetReq 0 "-5 Level" 1 "-4 Level" 2 "-3 Level" 3 "-2 Level" 4 "-1 Level" 5 "0 Level" 6 "1 Level" 7 "2 Level" 8 "3 Level" 9 "4 Level" 10 "5 Level" 11 "Not Used" 12 "Not Used" 13 "Not Used" 14 "Error Indicator" 15 "Invalid" ;
VAL_ 1279 USM_CMSNgtBrgtnsLvlLHSetReq 0 "-5 Level" 1 "-4 Level" 2 "-3 Level" 3 "-2 Level" 4 "-1 Level" 5 "0 Level" 6 "1 Level" 7 "2 Level" 8 "3 Level" 9 "4 Level" 10 "5 Level" 11 "Not Used" 12 "Not Used" 13 "Not Used" 14 "Error Indicator" 15 "Invalid" ;
VAL_ 1279 USM_CMSDayBrgtnsLvlRHSetReq 0 "-5 Level" 1 "-4 Level" 2 "-3 Level" 3 "-2 Level" 4 "-1 Level" 5 "0 Level" 6 "1 Level" 7 "2 Level" 8 "3 Level" 9 "4 Level" 10 "5 Level" 11 "Not Used" 12 "Not Used" 13 "Not Used" 14 "Error Indicator" 15 "Invalid" ;
VAL_ 1279 USM_CMSNgtBrgtnsLvlRHSetReq 0 "-5 Level" 1 "-4 Level" 2 "-3 Level" 3 "-2 Level" 4 "-1 Level" 5 "0 Level" 6 "1 Level" 7 "2 Level" 8 "3 Level" 9 "4 Level" 10 "5 Level" 11 "Not Used" 12 "Not Used" 13 "Not Used" 14 "Error Indicator" 15 "Invalid" ;
VAL_ 1279 USM_CMSBrgtnsReset 0 "Default" 1 "Reset" 2 "Reserved" 3 "Invalid" ;
VAL_ 1279 USM_TurnDistLnDispSetReq 0 "Default" 1 "Off" 2 "On" 3 "Invalid" ;
VAL_ 1279 PCA_FrSd_NValueSet 0 "Default" 1 "Off" 2 "On" 3 "Invalid" ;
VAL_ 1279 CF_AVN_1stRrStRmndNValueSet 0 "Default" 1 "Off" 2 "On" 3 "Invalid" ;
VAL_ 1279 AVN_Usm_CluThemeSta_New 0 "Default" 1 "Theme A(Classic A)" 2 "Theme B(Classic B)" 3 "Theme C(Classic C)" 4 "Theme D(Cube/Dynamic)" 5 "Reserved" 6 "Reserved" 7 "Reserved" 8 "Reserved" 9 "Reserved" 10 "Reserved" 11 "Reserved" 12 "Reserved" 13 "Reserved" 14 "Reserved" 15 "Invalid" ;
VAL_ 1279 C_AllDrOpnNValueSet 0 "Default" 1 "Off" 2 "PSD Open" 3 "PSD PTG Open" 4 "Reserved" 5 "Reserved" 6 "Reserved" 7 "Invalid" ;
VAL_ 1279 USM_RpmECOSet 0 "Default" 1 "Off" 2 "On(RPM Gauge Display)" 3 "Invalid" ;
VAL_ 1279 VESS_ChgGuideMdLvl 0 "Default" 1 "Level 1(¾àÇÏ°Ô)" 2 "Level 2(Áß°£)" 3 "Level 3(°­ÇÏ°Ô)" 4 "Reserved" 5 "Reserved" 6 "Off" 7 "Invalid" ;
VAL_ 1279 Usm_RpmSPORTSet 0 "Default" 1 "Off" 2 "On(RPM Gauge Display)" 3 "Invalid" ;
VAL_ 1279 Usm_RpmSPORTPLUSSet 0 "Default" 1 "Off" 2 "On(RPM Gauge Display)" 3 "Invalid" ;
VAL_ 200 CF_AVN_ADrLNValueSet_2 0 "Default" 1 "Off" 2 "Vehicle Speed On (15km/h)" 3 "Vehicle Speed On and Shift Lever On" 4 "Invalid" 5 "Reserved" 6 "Reserved" 7 "Reserved" ;
VAL_ 200 CF_AVN_FCA_JC_OnOffEquipNvalueSet 0 "Default" 1 "Off" 2 "On" 3 "Invalid" ;
VAL_ 200 CF_AVN_FCA_FrSdOnOffEquipNvalueSet 0 "Default" 1 "Off" 2 "On" 3 "Invalid" ;
VAL_ 200 CF_AVN_LKA_OnOffEquip2NvalueSet 0 "Default" 1 "Off" 2 "On" 3 "Invalid" ;
VAL_ 200 CF_AVN_BCA_OnOffEquip2NvalueSet 0 "Default" 1 "Off" 2 "On" 3 "Invalid" ;
VAL_ 200 CF_AVN_BVM_OnOffEquipNvalueSet 0 "Default" 1 "Off" 2 "On" 3 "Invalid" ;
VAL_ 200 CF_AVN_SEA_OnOffEquip3NvalueSet 0 "Default" 1 "Off" 2 "On" 3 "Invalid" ;
VAL_ 200 CF_AVN_BodySpprtSet_AST 0 "Default" 1 "Off" 2 "On" 3 "Invalid" ;
VAL_ 200 CF_AVN_SEW_OnOffEquip3NvalueSet 0 "Default" 1 "Off" 2 "On" 3 "Invalid" ;
VAL_ 200 CF_AVN_HudImsAutoSave 0 "Default" 1 "Off" 2 "On" 3 "Invalid" ;
VAL_ 200 USM_PwrDrBuzzerNValueSet 0 "Default" 1 "Off" 2 "On" 3 "Invalid" ;
VAL_ 200 CF_AVN_DWLNValueSet 0 "Default" 1 "Comfort" 2 "Natural" 3 "Dynamic" 4 "Reserved" 5 "Reserved" 6 "Reserved" 7 "Invalid" ;
VAL_ 200 CF_AVN_AirSptTimeNValueSet_AST 0 "Default" 1 "Short" 2 "Normal" 3 "Long" 4 "Reserved" 5 "Reserved" 6 "Reserved" 7 "Invalid" ;
VAL_ 200 CF_AVN_AirSptStrNValue_AST 0 "Default" 1 "Normal" 2 "Intense" 3 "Invalid" ;
VAL_ 200 CF_AVN_SeatDrvModNvalueSet_AST 0 "Default" 1 "Off" 2 "On" 3 "Invalid" ;
VAL_ 200 CF_AVN_TPMS_TireReplaceNValueSet 0 "Default" 1 "Off(Standard)" 2 "ON(SnowChain)" 3 "Reserved" 4 "Reserved" 5 "Reserved" 6 "Not Used(Gray)" 7 "Error Indicator" ;
VAL_ 200 CF_AVN_TowModeSet 0 "Default" 1 "Off" 2 "Small Weight" 3 "Medium Weight" 4 "Maximum Weight" 5 "Reserved" 6 "Reserved" 7 "Invalid" ;
VAL_ 200 USM_PwrDrCloseByBraekNValueSet 0 "Default" 1 "Off" 2 "On" 3 "Invalid" ;
VAL_ 200 CF_AVN_ISLANAOffstNvalueSet 0 "Default" 1 "-10kph -10mph" 2 "-5kph -5mph" 3 "0kph 0mph" 4 "5kph 5mph" 5 "10kph 10mph" 6 "Reserved" 7 "Invalid" ;
VAL_ 200 USM_DrvGhostDoorReq 0 "Default" 1 "Off" 2 "On" 3 "Invalid" ;
VAL_ 200 USM_AstGhostDoorReq 0 "Default" 1 "Off" 2 "On" 3 "Invalid" ;
VAL_ 200 USM_RLGhostDoorReq 0 "Default" 1 "Off" 2 "On" 3 "Invalid" ;
VAL_ 200 CF_AVN_FCA_FrOnOffEquipNvalueSet 0 "Default" 1 "Off" 2 "On" 3 "Invalid" ;
VAL_ 200 CF_AVN_FCA_WarnTimeNvalueSet 0 "Default" 1 "Late" 2 "Normal" 3 "Reserved" 4 "Reserved" 5 "Reserved" 6 "Reserved" 7 "Invalid" ;
VAL_ 2172675330 IEB_Sta 0 "Not Ready" 1 "Ready" 2 "Ready (Front only) & Not Ready(Rear)" 3 "Ready (Rear only) & Not Ready(Front)" ;
VAL_ 2172675330 IEB_SnsrFailSta 0 "Normal" 1 "Fail" 2 "Not used" 3 "Error Indicator" ;
VAL_ 2172675330 IEB_RbsWrngLmpSta 0 "RBS Warning Lamp OFF" 1 "RBS Warning Lamp ON" 2 "Not used" 3 "Error Indicator" ;
VAL_ 2172675330 IEB_AbsNGearReq 0 "Inactive" 1 "N Gear position Request Active" 2 "Not used" 3 "Error Indicator" ;
VAL_ 2172675330 IEB_EstBrkPdlValVldSta 0 "Invalid" 1 "Valid" 2 "Not used" 3 "Error Indicator" ;
VAL_ 2172675330 IEB_VacSysDfctvSta 0 "Vacuum pump NOT defective" 1 "Vacuum pump defective (failed)" 2 "Not used" 3 "Error Indicator" ;
VAL_ 2172675330 IEB_InhbtTrnstnTo4wd_Req 0 "No Request" 1 "Inhibit Transition To 4WD" 2 "Not used" 3 "Not used" ;
VAL_ 2172675331 IEB_DrvWhlSlipFlg_Frnt 0 "No slip occurred at the driving wheels" 1 "Slip occurred at the driving wheels" ;
VAL_ 2172675331 IEB_TCS_Req 0 "TCS control is not active" 1 "TCS control is active by requested TORQUE based" 2 "TCS control is active by requested RPM based" 3 "Not used" ;
VAL_ 2172675331 IEB_RSC_Req 0 "RSC is not active" 1 "RSC is active" 2 "eDTVC is active" 3 "Not used" ;
VAL_ 2172675331 TCS_TqFlag_Frnt 0 "Positive" 1 "Negative" ;
VAL_ 2172675331 TCS_TqFlag_Rear 0 "Positive" 1 "Negative" ;
VAL_ 2172675331 RSC_TqFlag_Frnt 0 "Positive" 1 "Negative" ;
VAL_ 2172675331 RSC_TqFlag_Rear 0 "Positive" 1 "Negative" ;
VAL_ 191 RL_SHVU_DTCdisplay 0 "DTC is not exist(Fail is not exist)" 1 "IGN2 Fuse Open Detection" 2 "Switch Input Detection at Same Time" 3 "NTC/Heating wire Open Detection" 4 "NTC+/NTC- Terminal Short Detection" 5 "NTC+/Heater+ Terminal Short Detection" 6 "NTC+/Heater-, Heater+/Heater-, Heater+/NTC- Terminal Short Detection" 7 "NTC+/Heater- Wiring Short Detection" 8 "NTC+/Heater-, Heater+/Heater-, Heater+/NTC- Wiring Short Detection" 9 "Target Temperature Dissatisfied" 10 "Blower+/Blower- Short, Blower+/Blower Speed, Blower-/Blower Speed Wiring Short Detection" 11 "Blower+/Blower RPM, Blower-/Blower RPM, Blower Speed/Blower RPM Short Detection" 12 "Blower+, Blower-, Blower Speed Signal open Detection" 13 "Blower RPM signal Open Detection" 14 "0xE~0xFD:Unused" 253 "0xE~0xFD:Unused" 254 "No Display" 255 "Invalid" ;
VAL_ 191 RL_SHVU_DiagMode 0 "Default" 1 "DTC Mode" 2 "Normal Mode" 3 "Invalid" ;
VAL_ 2328016129 VCU_EvDrvRdyCluDispSta 0 "Ready Lamp Off" 1 "Ready Lamp On" 2 "Error Indicator" 3 "Blinking" ;
VAL_ 2328016129 VCU_PwrDnModeSta 0 "None" 1 "Set" 2 "Not used" 3 "Error Indicator" ;
VAL_ 2328016129 VCU_CluWarnMsgSta 0 "None(Default)" 1 "Regenerative Braking System Operating Stop" 2 "AC,PTC Controllable when EV_Ready is OFF" 3 "-" 4 "Gear P Change Impossible(VB 10.5V)" 5 "Gear P Change Impossible(VB 9.5V)" 6 "-" 7 "-" 8 "Reserved" 9 "Reserved" 10 "Reserved" 11 "Reserved" 12 "Reserved" 13 "Reserved" 14 "Reserved" 15 "Reserved" ;
VAL_ 2328016129 VCU_DteOffDispSta 0 "None" 1 "DTE Off('---' Display)" 2 "Not used" 3 "Error Indicator" ;
VAL_ 2328016129 VCU_LowSocAlertSta 0 "No Alert" 1 "Low SOC Alert 1" 2 "Low SOC Alert 2" 3 "Low SOC Alert 3" 4 "Reserved" 5 "Reserved" 6 "Reserved" 7 "SOC Unavailable Alert" ;
VAL_ 2328016129 VCU_VcrmReq 0 "Wait(Not Request Logging)" 1 "Service/MIL Lamp On(Request Logging)" 2 "Warning, Abnormal IG Off(Request Logging)" 3 "Reserved" ;
VAL_ 2328016129 VCU_PdlWarnMsgSta 0 "None" 1 "Pop-up Request" 2 "Not used" 3 "Error Indicator" ;
VAL_ 2328016129 VCU_AwdDiagDispSta 0 "Off" 1 "On" 2 "NotUsed" 3 "ErrorIndicator" ;
VAL_ 2328016129 VCU_AwdLockDispSta 0 "Off" 1 "On" 2 "NotUsed" 3 "ErrorIndicator" ;
VAL_ 2328016129 VCU_VirtualApsActSta 0 "Real APS" 1 "Virtual APS for Crz" 2 "Not used" 3 "Error Indicator" ;
VAL_ 2328016129 VCU_ServiceLampReq 0 "None" 1 "Service Lamp On" 2 "Not used" 3 "Error Indicator" ;
VAL_ 2328016129 VCU_ServiceModeSta 0 "Normal" 1 "Certification Mode (F)" 2 "Certification Mode (R)" 3 "Error Indicator" ;
VAL_ 2328016129 VCU_NPosWshModSta 0 "Normal" 1 "Standby" 2 "N Wash Mode" 3 "Reserved" ;
VAL_ 2328016129 VCU_PowerTrainType 0 "One Moter" 1 "Dual Motor(Base)" 2 "Dual Motor(Performance)" 3 "Reserved" ;
VAL_ 2328016130 VCU_AvnDteOnCalcSta 0 "Display DTE Value" 1 "Display 'Recalculating'" 2 "Not used" 3 "Error Indicator" ;
VAL_ 2328016130 VCU_SbwWarnMsgSta 0 "Off" 1 "Warning 1 - SCU/Parking System Failure" 2 "Warning 2 - Unavailable to Shift Gear" 3 "Warning 3 - Brake On for Gear Shift" 4 "Warning 4 - Unavailable to Park" 5 "Warning 5 - Auto Parked" 6 "Warning 6 - Unavailable to Release Park" 7 "Warning 7 - Same Button Re-Entered" ;
VAL_ 2328016130 VCU_EnergyFlowSta 0 "None" 1 "No Flow" 2 "Front Motor Motoring" 3 "Rear Motor Motoring" 4 "Dual Motor Motoring" 5 "Not Used" 6 "Front Motor Generating" 7 "Rear Motor Generating" 8 "Dual Motor Generating" 9 "Not Used" 10 "Reserved" 11 "Reserved" 12 "Reserved" 13 "Reserved" 14 "Reserved" 15 "Reserved" ;
VAL_ 2328016130 VCU_SbwWarnSndSta 0 "Warning Sound Off" 1 "Warning Sound On" 2 "Not used" 3 "Error Indicator" ;
VAL_ 2328016130 VCU_EcoGuide_DispReq 0 "Smart ECO Guide Off" 1 "Smart ECO Guide On" 2 "Not used" 3 "Error Indicator" ;
VAL_ 2328016130 VCU_EcoGuide_ApsGaugeVal 0 "Not Display" 1 "1~100" 2 "1~100" 3 "1~100" 4 "1~100" 5 "1~100" 6 "1~100" 7 "1~100" 8 "1~100" 9 "1~100" 10 "1~100" 11 "1~100" 12 "1~100" 13 "1~100" 14 "1~100" 15 "1~100" 16 "1~100" 17 "1~100" 18 "1~100" 19 "1~100" 20 "1~100" 21 "1~100" 22 "1~100" 23 "1~100" 24 "1~100" 25 "1~100" 26 "1~100" 27 "1~100" 28 "1~100" 29 "1~100" 30 "1~100" 31 "1~100" 32 "1~100" 33 "1~100" 34 "1~100" 35 "1~100" 36 "1~100" 37 "1~100" 38 "1~100" 39 "1~100" 40 "1~100" 41 "1~100" 42 "1~100" 43 "1~100" 44 "1~100" 45 "1~100" 46 "1~100" 47 "1~100" 48 "1~100" 49 "1~100" 50 "1~100" 51 "1~100" 52 "1~100" 53 "1~100" 54 "1~100" 55 "1~100" 56 "1~100" 57 "1~100" 58 "1~100" 59 "1~100" 60 "1~100" 61 "1~100" 62 "1~100" 63 "1~100" 64 "1~100" 65 "1~100" 66 "1~100" 67 "1~100" 68 "1~100" 69 "1~100" 70 "1~100" 71 "1~100" 72 "1~100" 73 "1~100" 74 "1~100" 75 "1~100" 76 "1~100" 77 "1~100" 78 "1~100" 79 "1~100" 80 "1~100" 81 "1~100" 82 "1~100" 83 "1~100" 84 "1~100" 85 "1~100" 86 "1~100" 87 "1~100" 88 "1~100" 89 "1~100" 90 "1~100" 91 "1~100" 92 "1~100" 93 "1~100" 94 "1~100" 95 "1~100" 96 "1~100" 97 "1~100" 98 "1~100" 99 "1~100" 100 "1~100" 101 "Reserved" 102 "Reserved" 103 "Reserved" 104 "Reserved" 105 "Reserved" 106 "Reserved" 107 "Reserved" 108 "Reserved" 109 "Reserved" 110 "Reserved" 111 "Reserved" 112 "Reserved" 113 "Reserved" 114 "Reserved" 115 "Reserved" 116 "Reserved" 117 "Reserved" 118 "Reserved" 119 "Reserved" 120 "Reserved" 121 "Reserved" 122 "Reserved" 123 "Reserved" 124 "Reserved" 125 "Reserved" 126 "Reserved" 127 "Reserved" ;
VAL_ 2328016130 VCU_EcoGuide_EcoGaugeVal 0 "Not Display" 1 "1~100" 2 "1~100" 3 "1~100" 4 "1~100" 5 "1~100" 6 "1~100" 7 "1~100" 8 "1~100" 9 "1~100" 10 "1~100" 11 "1~100" 12 "1~100" 13 "1~100" 14 "1~100" 15 "1~100" 16 "1~100" 17 "1~100" 18 "1~100" 19 "1~100" 20 "1~100" 21 "1~100" 22 "1~100" 23 "1~100" 24 "1~100" 25 "1~100" 26 "1~100" 27 "1~100" 28 "1~100" 29 "1~100" 30 "1~100" 31 "1~100" 32 "1~100" 33 "1~100" 34 "1~100" 35 "1~100" 36 "1~100" 37 "1~100" 38 "1~100" 39 "1~100" 40 "1~100" 41 "1~100" 42 "1~100" 43 "1~100" 44 "1~100" 45 "1~100" 46 "1~100" 47 "1~100" 48 "1~100" 49 "1~100" 50 "1~100" 51 "1~100" 52 "1~100" 53 "1~100" 54 "1~100" 55 "1~100" 56 "1~100" 57 "1~100" 58 "1~100" 59 "1~100" 60 "1~100" 61 "1~100" 62 "1~100" 63 "1~100" 64 "1~100" 65 "1~100" 66 "1~100" 67 "1~100" 68 "1~100" 69 "1~100" 70 "1~100" 71 "1~100" 72 "1~100" 73 "1~100" 74 "1~100" 75 "1~100" 76 "1~100" 77 "1~100" 78 "1~100" 79 "1~100" 80 "1~100" 81 "1~100" 82 "1~100" 83 "1~100" 84 "1~100" 85 "1~100" 86 "1~100" 87 "1~100" 88 "1~100" 89 "1~100" 90 "1~100" 91 "1~100" 92 "1~100" 93 "1~100" 94 "1~100" 95 "1~100" 96 "1~100" 97 "1~100" 98 "1~100" 99 "1~100" 100 "1~100" 101 "Reserved" 102 "Reserved" 103 "Reserved" 104 "Reserved" 105 "Reserved" 106 "Reserved" 107 "Reserved" 108 "Reserved" 109 "Reserved" 110 "Reserved" 111 "Reserved" 112 "Reserved" 113 "Reserved" 114 "Reserved" 115 "Reserved" 116 "Reserved" 117 "Reserved" 118 "Reserved" 119 "Reserved" 120 "Reserved" 121 "Reserved" 122 "Reserved" 123 "Reserved" 124 "Reserved" 125 "Reserved" 126 "Reserved" 127 "Reserved" ;
VAL_ 2328016131 VCU_DistFromRegenDispReq 0 "Default" 1 "Displayed ---" 2 "Positive Value" 3 "Negative Value" ;
VAL_ 2328016131 VCU_DrvStyle_DispReq 0 "Invalid" 1 "Valid" 2 "Not used" 3 "Error Indicator" ;
VAL_ 2328016131 VCU_DrvStyle_HighLightSta 0 "None" 1 "High Fuel Efficiency" 2 "Normal Fuel Efficiency" 3 "Low Fuel Efficiency" ;
VAL_ 2328016131 VCU_DrvStyle_EcoVal 0 "0x0x0~0x64:0~100" 100 "0x0x0~0x64:0~100" 101 "Reserved" 102 "Reserved" 103 "Reserved" 104 "Reserved" 105 "Reserved" 106 "Reserved" 107 "Reserved" 108 "Reserved" 109 "Reserved" 110 "Reserved" 111 "Reserved" 112 "Reserved" 113 "Reserved" 114 "Reserved" 115 "Reserved" 116 "Reserved" 117 "Reserved" 118 "Reserved" 119 "Reserved" 120 "Reserved" 121 "Reserved" 122 "Reserved" 123 "Reserved" 124 "Reserved" 125 "Reserved" 126 "Reserved" 127 "Reserved" ;
VAL_ 2328016131 VCU_DrvStyle_NonEcoVal 0 "0x0x0~0x64:0~100" 100 "0x0x0~0x64:0~100" 101 "Reserved" 102 "Reserved" 103 "Reserved" 104 "Reserved" 105 "Reserved" 106 "Reserved" 107 "Reserved" 108 "Reserved" 109 "Reserved" 110 "Reserved" 111 "Reserved" 112 "Reserved" 113 "Reserved" 114 "Reserved" 115 "Reserved" 116 "Reserved" 117 "Reserved" 118 "Reserved" 119 "Reserved" 120 "Reserved" 121 "Reserved" 122 "Reserved" 123 "Reserved" 124 "Reserved" 125 "Reserved" 126 "Reserved" 127 "Reserved" ;
VAL_ 2328016131 VCU_DrvStyle_NorVal 0 "0x0x0~0x64:0~100" 100 "0x0x0~0x64:0~100" 101 "Reserved" 102 "Reserved" 103 "Reserved" 104 "Reserved" 105 "Reserved" 106 "Reserved" 107 "Reserved" 108 "Reserved" 109 "Reserved" 110 "Reserved" 111 "Reserved" 112 "Reserved" 113 "Reserved" 114 "Reserved" 115 "Reserved" 116 "Reserved" 117 "Reserved" 118 "Reserved" 119 "Reserved" 120 "Reserved" 121 "Reserved" 122 "Reserved" 123 "Reserved" 124 "Reserved" 125 "Reserved" 126 "Reserved" 127 "Reserved" ;
VAL_ 2328016132 VCU_StopCtrlWarnMsgSta 0 "None" 1 "i-Pedal On Popup Request" 2 "i-Pedal Off Popup Request" 3 "i-Pedal Forced Off Popup Request" 4 "SAC Off Popup Request" 5 "Reserved" 6 "Reserved" 7 "Reserved" ;
VAL_ 2328016132 VCU_DrvModeDefault 0 "No Data" 1 "Normal (Comfort)" 2 "ECO" 3 "Reserved" ;
